VERSION ""

NS_ :

BS_:

BU_:

BO_ 2566605566 MG3IAPL: 8 Vector__XXX
 SG_ MtGt3IvtPwLtdDTUddRs : 0|2@1+ (1,0) [0|3] "" Vector__XXX
 SG_ MtGt3IvtPwLtdDTMPwMx : 10|2@1+ (1,0) [0|3] "" Vector__XXX
 SG_ MtGt3IvtPwLtdDTMPwM : 12|2@1+ (1,0) [0|3] "" Vector__XXX
 SG_ MtrGnrtr3InvrtrPwrLmtdDTTrqMxmm : 18|2@1+ (1,0) [0|3] "" Vector__XXX
 SG_ MtrGnrtr3InvrtrPwrLmtdDTTrqMnmm : 20|2@1+ (1,0) [0|3] "" Vector__XXX
 SG_ MtrGnrtr3InvrtrPwrLmtdDTSpdMxmm : 22|2@1+ (1,0) [0|3] "" Vector__XXX
 SG_ MtrGnrtr3InvrtrPwrLmtdDTSpdMnmm : 24|2@1+ (1,0) [0|3] "" Vector__XXX
 SG_ MtGt3IvtPwLtdDTIvtTpt : 28|2@1+ (1,0) [0|3] "" Vector__XXX
 SG_ MtGt3IvtPwLtdDTMtTpt : 30|2@1+ (1,0) [0|3] "" Vector__XXX
 SG_ MtGt3IvtPwLtdDTFtCdt : 32|2@1+ (1,0) [0|3] "" Vector__XXX
 SG_ MtGt3IvtPwLtdDTAtvTqRtLt : 34|2@1+ (1,0) [0|3] "" Vector__XXX
 SG_ MtGt3IvtPwLtdDTAtvSpdRtLt : 36|2@1+ (1,0) [0|3] "" Vector__XXX
 SG_ MtGt3IvtTqLtdDTMCtsts : 38|2@1+ (1,0) [0|3] "" Vector__XXX
 SG_ MtGt3IvtPwLtdDTDSdCtMx : 2|2@1+ (1,0) [0|3] "" Vector__XXX
 SG_ MtGt3IvtPwLtdDTDSdCtM : 4|2@1+ (1,0) [0|3] "" Vector__XXX
 SG_ MtGt3IvtPwLtdDTDSdVtMx : 6|2@1+ (1,0) [0|3] "" Vector__XXX
 SG_ MtGt3IvtPwLtdDTDSdVtM : 8|2@1+ (1,0) [0|3] "" Vector__XXX
 SG_ MtGt3IvtPwLtdDTDSdPwMx : 14|2@1+ (1,0) [0|3] "" Vector__XXX
 SG_ MtGt3IvtPwLtdDTDSdPwM : 16|2@1+ (1,0) [0|3] "" Vector__XXX

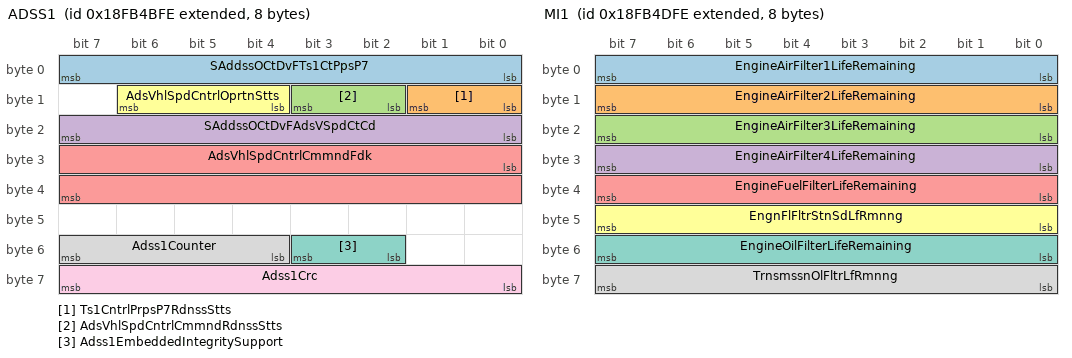
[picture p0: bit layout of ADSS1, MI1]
BO_ 2566605822 ADSS1: 8 Vector__XXX
 SG_ SAddssOCtDvFTs1CtPpsP7 : 0|8@1+ (1,0) [0|250] "sourceadr" Vector__XXX
 SG_ Ts1CntrlPrpsP7RdnssStts : 8|2@1+ (1,0) [0|3] "" Vector__XXX
 SG_ AdsVhlSpdCntrlCmmndRdnssStts : 10|2@1+ (1,0) [0|3] "" Vector__XXX
 SG_ SAddssOCtDvFAdsVSpdCtCd : 16|8@1+ (1,0) [0|250] "sourceadr" Vector__XXX
 SG_ AdsVhlSpdCntrlCmmndFdk : 24|16@1+ (0.00390625,0) [0|250.99609375] "km/h" Vector__XXX
 SG_ AdsVhlSpdCntrlOprtnStts : 12|3@1+ (1,0) [0|7] "" Vector__XXX
 SG_ Adss1EmbeddedIntegritySupport : 50|2@1+ (1,0) [0|3] "" Vector__XXX
 SG_ Adss1Counter : 52|4@1+ (1,0) [0|15] "" Vector__XXX
 SG_ Adss1Crc : 56|8@1+ (1,0) [0|250] "count" Vector__XXX

BO_ 2566606078 CCSI2: 8 Vector__XXX
 SG_ CabHeaterPower : 0|16@1+ (2,0) [0|128510] "W" Vector__XXX
 SG_ CabACCompressorPower : 16|16@1+ (0.5,0) [0|32127.5] "W" Vector__XXX

BO_ 2566606334 MI1: 8 Vector__XXX
 SG_ EngineAirFilter1LifeRemaining : 0|8@1+ (0.4,0) [0|100] "%" Vector__XXX
 SG_ EngineAirFilter2LifeRemaining : 8|8@1+ (0.4,0) [0|100] "%" Vector__XXX
 SG_ EngineAirFilter3LifeRemaining : 16|8@1+ (0.4,0) [0|100] "%" Vector__XXX
 SG_ EngineAirFilter4LifeRemaining : 24|8@1+ (0.4,0) [0|100] "%" Vector__XXX
 SG_ EngineFuelFilterLifeRemaining : 32|8@1+ (0.4,0) [0|100] "%" Vector__XXX
 SG_ EngnFlFltrStnSdLfRmnng : 40|8@1+ (0.4,0) [0|100] "%" Vector__XXX
 SG_ EngineOilFilterLifeRemaining : 48|8@1+ (0.4,0) [0|100] "%" Vector__XXX
 SG_ TrnsmssnOlFltrLfRmnng : 56|8@1+ (0.4,0) [0|100] "%" Vector__XXX

BO_ 2499497726 HCI1: 8 Vector__XXX
 SG_ HoistLeverPosition : 0|16@1+ (0.005,-150) [-100|100] "%" Vector__XXX
 SG_ HoistLeverDetentPositionStatus : 16|2@1+ (1,0) [0|3] "" Vector__XXX

BO_ 2633715710 HVESP6HIST: 19 Vector__XXX
 SG_ Hvesp6StateOfHealth : 0|8@1+ (0.4,0) [0|100] "%" Vector__XXX
 SG_ Hvesp6TotalEnergyThroughput : 24|32@1+ (100,0) [0|421108121500] "Watt-hour" Vector__XXX
 SG_ Hvesp6TotalAccumulatedCharge : 56|32@1+ (100,0) [0|421108121500] "Ah" Vector__XXX
 SG_ Hvesp6TotalLifetimeEnergyInput : 88|32@1+ (1,0) [0|4211081215] "kWh" Vector__XXX
 SG_ Hvesp6TotalLifetimeEnergyOutput : 120|32@1+ (1,0) [0|4211081215] "kWh" Vector__XXX
 SG_ Hvsp6CnttrOpnUndrLdCnt : 8|16@1+ (1,0) [0|64255] "count" Vector__XXX

BO_ 2566607102 HVESP6CFG: 19 Vector__XXX
 SG_ Hvesp6NominalVoltage : 0|16@1+ (0.05,0) [0|3212.75] "V" Vector__XXX
 SG_ Hvesp6CellMaximumVoltageLimit : 112|8@1+ (0.02044,0) [0|5.11] "V" Vector__XXX
 SG_ Hvesp6CellMinimumVoltageLimit : 120|8@1+ (0.02044,0) [0|5.11] "V" Vector__XXX
 SG_ Hvsp6RmmnddMnmmOprtngVltg : 16|16@1+ (0.05,0) [0|3212.75] "V" Vector__XXX
 SG_ Hvsp6RmmnddMxmmOprtngVltg : 32|16@1+ (0.05,0) [0|3212.75] "V" Vector__XXX
 SG_ Hvsp6RmmnddMnmmSttOfChrg : 48|16@1+ (0.0015625,0) [0|100.3984375] "%" Vector__XXX
 SG_ Hvsp6RmmnddMxmmSttOfChrg : 64|16@1+ (0.0015625,0) [0|100.3984375] "%" Vector__XXX
 SG_ Hvsp6RmmnddMxmmOprtngTmprtr : 80|16@1+ (0.03125,-273) [-273|1734.96875] "degC" Vector__XXX
 SG_ Hvsp6RmmnddMnmmOprtngTmprtr : 96|16@1+ (0.03125,-273) [-273|1734.96875] "degC" Vector__XXX
 SG_ Hvesp6NominalRatedCapacity : 128|24@1+ (0.001,0) [0|16449.535] "kWh" Vector__XXX

BO_ 2633716222 HVESP5HIST: 19 Vector__XXX
 SG_ Hvesp5StateOfHealth : 0|8@1+ (0.4,0) [0|100] "%" Vector__XXX
 SG_ Hvesp5TotalEnergyThroughput : 24|32@1+ (100,0) [0|421108121500] "Watt-hour" Vector__XXX
 SG_ Hvesp5TotalAccumulatedCharge : 56|32@1+ (100,0) [0|421108121500] "Ah" Vector__XXX
 SG_ Hvesp5TotalLifetimeEnergyInput : 88|32@1+ (1,0) [0|4211081215] "kWh" Vector__XXX
 SG_ Hvesp5TotalLifetimeEnergyOutput : 120|32@1+ (1,0) [0|4211081215] "kWh" Vector__XXX
 SG_ Hvsp5CnttrOpnUndrLdCnt : 8|16@1+ (1,0) [0|64255] "count" Vector__XXX

BO_ 2566607614 HVESP5CFG: 19 Vector__XXX
 SG_ Hvesp5NominalVoltage : 0|16@1+ (0.05,0) [0|3212.75] "V" Vector__XXX
 SG_ Hvesp5CellMaximumVoltageLimit : 112|8@1+ (0.02044,0) [0|5.11] "V" Vector__XXX
 SG_ Hvesp5CellMinimumVoltageLimit : 120|8@1+ (0.02044,0) [0|5.11] "V" Vector__XXX
 SG_ Hvsp5RmmnddMnmmOprtngVltg : 16|16@1+ (0.05,0) [0|3212.75] "V" Vector__XXX
 SG_ Hvsp5RmmnddMxmmOprtngVltg : 32|16@1+ (0.05,0) [0|3212.75] "V" Vector__XXX
 SG_ Hvsp5RmmnddMnmmSttOfChrg : 48|16@1+ (0.0015625,0) [0|100.3984375] "%" Vector__XXX
 SG_ Hvsp5RmmnddMxmmSttOfChrg : 64|16@1+ (0.0015625,0) [0|100.3984375] "%" Vector__XXX
 SG_ Hvsp5RmmnddMxmmOprtngTmprtr : 80|16@1+ (0.03125,-273) [-273|1734.96875] "degC" Vector__XXX
 SG_ Hvsp5RmmnddMnmmOprtngTmprtr : 96|16@1+ (0.03125,-273) [-273|1734.96875] "degC" Vector__XXX
 SG_ Hvesp5NominalRatedCapacity : 128|24@1+ (0.001,0) [0|16449.535] "kWh" Vector__XXX

BO_ 2633716734 HVESP4HIST: 19 Vector__XXX
 SG_ Hvesp4StateOfHealth : 0|8@1+ (0.4,0) [0|100] "%" Vector__XXX
 SG_ Hvesp4TotalEnergyThroughput : 24|32@1+ (100,0) [0|421108121500] "Watt-hour" Vector__XXX
 SG_ Hvesp4TotalAccumulatedCharge : 56|32@1+ (100,0) [0|421108121500] "Ah" Vector__XXX
 SG_ Hvesp4TotalLifetimeEnergyInput : 88|32@1+ (1,0) [0|4211081215] "kWh" Vector__XXX
 SG_ Hvesp4TotalLifetimeEnergyOutput : 120|32@1+ (1,0) [0|4211081215] "kWh" Vector__XXX
 SG_ Hvsp4CnttrOpnUndrLdCnt : 8|16@1+ (1,0) [0|64255] "count" Vector__XXX

BO_ 2566608126 HVESP4CFG: 19 Vector__XXX
 SG_ Hvesp4NominalVoltage : 0|16@1+ (0.05,0) [0|3212.75] "V" Vector__XXX
 SG_ Hvesp4CellMaximumVoltageLimit : 112|8@1+ (0.02044,0) [0|5.11] "V" Vector__XXX
 SG_ Hvesp4CellMinimumVoltageLimit : 120|8@1+ (0.02044,0) [0|5.11] "V" Vector__XXX
 SG_ Hvsp4RmmnddMnmmOprtngVltg : 16|16@1+ (0.05,0) [0|3212.75] "V" Vector__XXX
 SG_ Hvsp4RmmnddMxmmOprtngVltg : 32|16@1+ (0.05,0) [0|3212.75] "V" Vector__XXX
 SG_ Hvsp4RmmnddMnmmSttOfChrg : 48|16@1+ (0.0015625,0) [0|100.3984375] "%" Vector__XXX
 SG_ Hvsp4RmmnddMxmmSttOfChrg : 64|16@1+ (0.0015625,0) [0|100.3984375] "%" Vector__XXX
 SG_ Hvsp4RmmnddMxmmOprtngTmprtr : 80|16@1+ (0.03125,-273) [-273|1734.96875] "degC" Vector__XXX
 SG_ Hvsp4RmmnddMnmmOprtngTmprtr : 96|16@1+ (0.03125,-273) [-273|1734.96875] "degC" Vector__XXX
 SG_ Hvesp4NominalRatedCapacity : 128|24@1+ (0.001,0) [0|16449.535] "kWh" Vector__XXX

BO_ 2633717246 HVESP3HIST: 19 Vector__XXX
 SG_ Hvesp3StateOfHealth : 0|8@1+ (0.4,0) [0|100] "%" Vector__XXX
 SG_ Hvesp3TotalEnergyThroughput : 24|32@1+ (100,0) [0|421108121500] "Watt-hour" Vector__XXX
 SG_ Hvesp3TotalAccumulatedCharge : 56|32@1+ (100,0) [0|421108121500] "Ah" Vector__XXX
 SG_ Hvesp3TotalLifetimeEnergyInput : 88|32@1+ (1,0) [0|4211081215] "kWh" Vector__XXX
 SG_ Hvesp3TotalLifetimeEnergyOutput : 120|32@1+ (1,0) [0|4211081215] "kWh" Vector__XXX
 SG_ Hvsp3CnttrOpnUndrLdCnt : 8|16@1+ (1,0) [0|64255] "count" Vector__XXX

BO_ 2566608638 HVESP3CFG: 19 Vector__XXX
 SG_ Hvesp3NominalVoltage : 0|16@1+ (0.05,0) [0|3212.75] "V" Vector__XXX
 SG_ Hvesp3CellMaximumVoltageLimit : 112|8@1+ (0.02044,0) [0|5.11] "V" Vector__XXX
 SG_ Hvesp3CellMinimumVoltageLimit : 120|8@1+ (0.02044,0) [0|5.11] "V" Vector__XXX
 SG_ Hvsp3RmmnddMnmmOprtngVltg : 16|16@1+ (0.05,0) [0|3212.75] "V" Vector__XXX
 SG_ Hvsp3RmmnddMxmmOprtngVltg : 32|16@1+ (0.05,0) [0|3212.75] "V" Vector__XXX
 SG_ Hvsp3RmmnddMnmmSttOfChrg : 48|16@1+ (0.0015625,0) [0|100.3984375] "%" Vector__XXX
 SG_ Hvsp3RmmnddMxmmSttOfChrg : 64|16@1+ (0.0015625,0) [0|100.3984375] "%" Vector__XXX
 SG_ Hvsp3RmmnddMxmmOprtngTmprtr : 80|16@1+ (0.03125,-273) [-273|1734.96875] "degC" Vector__XXX
 SG_ Hvsp3RmmnddMnmmOprtngTmprtr : 96|16@1+ (0.03125,-273) [-273|1734.96875] "degC" Vector__XXX
 SG_ Hvesp3NominalRatedCapacity : 128|24@1+ (0.001,0) [0|16449.535] "kWh" Vector__XXX

BO_ 2633717758 HVESP2HIST: 19 Vector__XXX
 SG_ Hvesp2StateOfHealth : 0|8@1+ (0.4,0) [0|100] "%" Vector__XXX
 SG_ Hvesp2TotalEnergyThroughput : 24|32@1+ (100,0) [0|421108121500] "Watt-hour" Vector__XXX
 SG_ Hvesp2TotalAccumulatedCharge : 56|32@1+ (100,0) [0|421108121500] "Ah" Vector__XXX
 SG_ Hvesp2TotalLifetimeEnergyInput : 88|32@1+ (1,0) [0|4211081215] "kWh" Vector__XXX
 SG_ Hvesp2TotalLifetimeEnergyOutput : 120|32@1+ (1,0) [0|4211081215] "kWh" Vector__XXX
 SG_ Hvsp2CnttrOpnUndrLdCnt : 8|16@1+ (1,0) [0|64255] "count" Vector__XXX

BO_ 2566609150 HVESP2CFG: 19 Vector__XXX
 SG_ Hvesp2NominalVoltage : 0|16@1+ (0.05,0) [0|3212.75] "V" Vector__XXX
 SG_ Hvesp2CellMaximumVoltageLimit : 112|8@1+ (0.02044,0) [0|5.11] "V" Vector__XXX
 SG_ Hvesp2CellMinimumVoltageLimit : 120|8@1+ (0.02044,0) [0|5.11] "V" Vector__XXX
 SG_ Hvsp2RmmnddMnmmOprtngVltg : 16|16@1+ (0.05,0) [0|3212.75] "V" Vector__XXX
 SG_ Hvsp2RmmnddMxmmOprtngVltg : 32|16@1+ (0.05,0) [0|3212.75] "V" Vector__XXX
 SG_ Hvsp2RmmnddMnmmSttOfChrg : 48|16@1+ (0.0015625,0) [0|100.3984375] "%" Vector__XXX
 SG_ Hvsp2RmmnddMxmmSttOfChrg : 64|16@1+ (0.0015625,0) [0|100.3984375] "%" Vector__XXX
 SG_ Hvsp2RmmnddMxmmOprtngTmprtr : 80|16@1+ (0.03125,-273) [-273|1734.96875] "degC" Vector__XXX
 SG_ Hvsp2RmmnddMnmmOprtngTmprtr : 96|16@1+ (0.03125,-273) [-273|1734.96875] "degC" Vector__XXX
 SG_ Hvesp2NominalRatedCapacity : 128|24@1+ (0.001,0) [0|16449.535] "kWh" Vector__XXX

BO_ 2633718270 HVESP1HIST: 19 Vector__XXX
 SG_ Hvesp1StateOfHealth : 0|8@1+ (0.4,0) [0|100] "%" Vector__XXX
 SG_ Hvesp1TotalEnergyThroughput : 24|32@1+ (100,0) [0|421108121500] "Watt-hour" Vector__XXX
 SG_ Hvesp1TotalAccumulatedCharge : 56|32@1+ (100,0) [0|421108121500] "Ah" Vector__XXX
 SG_ Hvesp1TotalLifetimeEnergyInput : 88|32@1+ (1,0) [0|4211081215] "kWh" Vector__XXX
 SG_ Hvesp1TotalLifetimeEnergyOutput : 120|32@1+ (1,0) [0|4211081215] "kWh" Vector__XXX
 SG_ Hvsp1CnttrOpnUndrLdCnt : 8|16@1+ (1,0) [0|64255] "count" Vector__XXX

BO_ 2566609662 HVESP1CFG: 19 Vector__XXX
 SG_ Hvesp1NominalVoltage : 0|16@1+ (0.05,0) [0|3212.75] "V" Vector__XXX
 SG_ Hvesp1CellMaximumVoltageLimit : 112|8@1+ (0.02044,0) [0|5.11] "V" Vector__XXX
 SG_ Hvesp1CellMinimumVoltageLimit : 120|8@1+ (0.02044,0) [0|5.11] "V" Vector__XXX
 SG_ Hvsp1RmmnddMnmmOprtngVltg : 16|16@1+ (0.05,0) [0|3212.75] "V" Vector__XXX
 SG_ Hvsp1RmmnddMxmmOprtngVltg : 32|16@1+ (0.05,0) [0|3212.75] "V" Vector__XXX
 SG_ Hvsp1RmmnddMnmmSttOfChrg : 48|16@1+ (0.0015625,0) [0|100.3984375] "%" Vector__XXX
 SG_ Hvsp1RmmnddMxmmSttOfChrg : 64|16@1+ (0.0015625,0) [0|100.3984375] "%" Vector__XXX
 SG_ Hvsp1RmmnddMxmmOprtngTmprtr : 80|16@1+ (0.03125,-273) [-273|1734.96875] "degC" Vector__XXX
 SG_ Hvsp1RmmnddMnmmOprtngTmprtr : 96|16@1+ (0.03125,-273) [-273|1734.96875] "degC" Vector__XXX
 SG_ Hvesp1NominalRatedCapacity : 128|24@1+ (0.001,0) [0|16449.535] "kWh" Vector__XXX

BO_ 2633718782 VFSSM1DET: 24 Vector__XXX
 SG_ VfssMdl1Dttr1DttrTp : 0|4@1+ (1,0) [0|15] "" Vector__XXX
 SG_ VfssMdl1Dttr2DttrTp : 24|4@1+ (1,0) [0|15] "" Vector__XXX
 SG_ VfssMdl1Dttr3DttrTp : 48|4@1+ (1,0) [0|15] "" Vector__XXX
 SG_ VfssMdl1Dttr4DttrTp : 72|4@1+ (1,0) [0|15] "" Vector__XXX
 SG_ VfssMdl1Dttr5DttrTp : 96|4@1+ (1,0) [0|15] "" Vector__XXX
 SG_ VfssMdl1Dttr6DttrTp : 120|4@1+ (1,0) [0|15] "" Vector__XXX
 SG_ VfssMdl1Dttr7DttrTp : 144|4@1+ (1,0) [0|15] "" Vector__XXX
 SG_ VfssMdl1Dttr8DttrTp : 168|4@1+ (1,0) [0|15] "" Vector__XXX
 SG_ VfssMdl1Dttr1DttrDtSlt : 4|4@1+ (1,0) [0|15] "" Vector__XXX
 SG_ VfssMdl1Dttr2DttrDtSlt : 28|4@1+ (1,0) [0|15] "" Vector__XXX
 SG_ VfssMdl1Dttr3DttrDtSlt : 52|4@1+ (1,0) [0|15] "" Vector__XXX
 SG_ VfssMdl1Dttr4DttrDtSlt : 76|4@1+ (1,0) [0|15] "" Vector__XXX
 SG_ VfssMdl1Dttr5DttrDtSlt : 100|4@1+ (1,0) [0|15] "" Vector__XXX
 SG_ VfssMdl1Dttr6DttrDtSlt : 124|4@1+ (1,0) [0|15] "" Vector__XXX
 SG_ VfssMdl1Dttr7DttrDtSlt : 148|4@1+ (1,0) [0|15] "" Vector__XXX
 SG_ VfssMdl1Dttr8DttrDtSlt : 172|4@1+ (1,0) [0|15] "" Vector__XXX

BO_ 2633719038 VFSSM2DET: 24 Vector__XXX
 SG_ VfssMdl2Dttr1DttrTp : 0|4@1+ (1,0) [0|15] "" Vector__XXX
 SG_ VfssMdl2Dttr2DttrTp : 24|4@1+ (1,0) [0|15] "" Vector__XXX
 SG_ VfssMdl2Dttr3DttrTp : 48|4@1+ (1,0) [0|15] "" Vector__XXX
 SG_ VfssMdl2Dttr4DttrTp : 72|4@1+ (1,0) [0|15] "" Vector__XXX
 SG_ VfssMdl2Dttr5DttrTp : 96|4@1+ (1,0) [0|15] "" Vector__XXX
 SG_ VfssMdl2Dttr6DttrTp : 120|4@1+ (1,0) [0|15] "" Vector__XXX
 SG_ VfssMdl2Dttr7DttrTp : 144|4@1+ (1,0) [0|15] "" Vector__XXX
 SG_ VfssMdl2Dttr8DttrTp : 168|4@1+ (1,0) [0|15] "" Vector__XXX
 SG_ VfssMdl2Dttr1DttrDtSlt : 4|4@1+ (1,0) [0|15] "" Vector__XXX
 SG_ VfssMdl2Dttr2DttrDtSlt : 28|4@1+ (1,0) [0|15] "" Vector__XXX
 SG_ VfssMdl2Dttr3DttrDtSlt : 52|4@1+ (1,0) [0|15] "" Vector__XXX
 SG_ VfssMdl2Dttr4DttrDtSlt : 76|4@1+ (1,0) [0|15] "" Vector__XXX
 SG_ VfssMdl2Dttr5DttrDtSlt : 100|4@1+ (1,0) [0|15] "" Vector__XXX
 SG_ VfssMdl2Dttr6DttrDtSlt : 124|4@1+ (1,0) [0|15] "" Vector__XXX
 SG_ VfssMdl2Dttr7DttrDtSlt : 148|4@1+ (1,0) [0|15] "" Vector__XXX
 SG_ VfssMdl2Dttr8DttrDtSlt : 172|4@1+ (1,0) [0|15] "" Vector__XXX

BO_ 2633719294 VFSSM3DET: 24 Vector__XXX
 SG_ VfssMdl3Dttr1DttrTp : 0|4@1+ (1,0) [0|15] "" Vector__XXX
 SG_ VfssMdl3Dttr2DttrTp : 24|4@1+ (1,0) [0|15] "" Vector__XXX
 SG_ VfssMdl3Dttr3DttrTp : 48|4@1+ (1,0) [0|15] "" Vector__XXX
 SG_ VfssMdl3Dttr4DttrTp : 72|4@1+ (1,0) [0|15] "" Vector__XXX
 SG_ VfssMdl3Dttr5DttrTp : 96|4@1+ (1,0) [0|15] "" Vector__XXX
 SG_ VfssMdl3Dttr6DttrTp : 120|4@1+ (1,0) [0|15] "" Vector__XXX
 SG_ VfssMdl3Dttr7DttrTp : 144|4@1+ (1,0) [0|15] "" Vector__XXX
 SG_ VfssMdl3Dttr8DttrTp : 168|4@1+ (1,0) [0|15] "" Vector__XXX
 SG_ VfssMdl3Dttr1DttrDtSlt : 4|4@1+ (1,0) [0|15] "" Vector__XXX
 SG_ VfssMdl3Dttr2DttrDtSlt : 28|4@1+ (1,0) [0|15] "" Vector__XXX
 SG_ VfssMdl3Dttr3DttrDtSlt : 52|4@1+ (1,0) [0|15] "" Vector__XXX
 SG_ VfssMdl3Dttr4DttrDtSlt : 76|4@1+ (1,0) [0|15] "" Vector__XXX
 SG_ VfssMdl3Dttr5DttrDtSlt : 100|4@1+ (1,0) [0|15] "" Vector__XXX
 SG_ VfssMdl3Dttr6DttrDtSlt : 124|4@1+ (1,0) [0|15] "" Vector__XXX
 SG_ VfssMdl3Dttr7DttrDtSlt : 148|4@1+ (1,0) [0|15] "" Vector__XXX
 SG_ VfssMdl3Dttr8DttrDtSlt : 172|4@1+ (1,0) [0|15] "" Vector__XXX

BO_ 2633719550 VFSSM4DET: 24 Vector__XXX
 SG_ VfssMdl4Dttr1DttrTp : 0|4@1+ (1,0) [0|15] "" Vector__XXX
 SG_ VfssMdl4Dttr2DttrTp : 24|4@1+ (1,0) [0|15] "" Vector__XXX
 SG_ VfssMdl4Dttr3DttrTp : 48|4@1+ (1,0) [0|15] "" Vector__XXX
 SG_ VfssMdl4Dttr4DttrTp : 72|4@1+ (1,0) [0|15] "" Vector__XXX
 SG_ VfssMdl4Dttr5DttrTp : 96|4@1+ (1,0) [0|15] "" Vector__XXX
 SG_ VfssMdl4Dttr6DttrTp : 120|4@1+ (1,0) [0|15] "" Vector__XXX
 SG_ VfssMdl4Dttr7DttrTp : 144|4@1+ (1,0) [0|15] "" Vector__XXX
 SG_ VfssMdl4Dttr8DttrTp : 168|4@1+ (1,0) [0|15] "" Vector__XXX
 SG_ VfssMdl4Dttr1DttrDtSlt : 4|4@1+ (1,0) [0|15] "" Vector__XXX
 SG_ VfssMdl4Dttr2DttrDtSlt : 28|4@1+ (1,0) [0|15] "" Vector__XXX
 SG_ VfssMdl4Dttr3DttrDtSlt : 52|4@1+ (1,0) [0|15] "" Vector__XXX
 SG_ VfssMdl4Dttr4DttrDtSlt : 76|4@1+ (1,0) [0|15] "" Vector__XXX
 SG_ VfssMdl4Dttr5DttrDtSlt : 100|4@1+ (1,0) [0|15] "" Vector__XXX
 SG_ VfssMdl4Dttr6DttrDtSlt : 124|4@1+ (1,0) [0|15] "" Vector__XXX
 SG_ VfssMdl4Dttr7DttrDtSlt : 148|4@1+ (1,0) [0|15] "" Vector__XXX
 SG_ VfssMdl4Dttr8DttrDtSlt : 172|4@1+ (1,0) [0|15] "" Vector__XXX

BO_ 2633719806 VFSSM1AUX: 16 Vector__XXX
 SG_ VfssModule1HeatZone1Data : 0|16@1+ (0.01,0) [0|642.55] "V" Vector__XXX
 SG_ VfssModule1HeatZone2Data : 16|16@1+ (0.01,0) [0|642.55] "V" Vector__XXX
 SG_ VfssModule1ReleaseZone1Data : 32|16@1+ (0.01,0) [0|642.55] "V" Vector__XXX
 SG_ VfssModule1ReleaseZone2Data : 48|16@1+ (0.01,0) [0|642.55] "V" Vector__XXX
 SG_ VfssModule1PressureSwitch1Data : 64|16@1+ (0.01,0) [0|642.55] "V" Vector__XXX
 SG_ VfssModule1PressureSwitch2Data : 80|16@1+ (0.01,0) [0|642.55] "V" Vector__XXX
 SG_ VfssModule1PrimaryPowerVoltage : 96|16@1+ (0.01,0) [0|642.55] "V" Vector__XXX
 SG_ VfssMdl1SndrPwrVltg : 112|16@1+ (0.01,0) [0|642.55] "V" Vector__XXX

BO_ 2633720062 VFSSM2AUX: 16 Vector__XXX
 SG_ VfssModule2HeatZone1Data : 0|16@1+ (0.01,0) [0|642.55] "V" Vector__XXX
 SG_ VfssModule2HeatZone2Data : 16|16@1+ (0.01,0) [0|642.55] "V" Vector__XXX
 SG_ VfssModule2ReleaseZone1Data : 32|16@1+ (0.01,0) [0|642.55] "V" Vector__XXX
 SG_ VfssModule2ReleaseZone2Data : 48|16@1+ (0.01,0) [0|642.55] "V" Vector__XXX
 SG_ VfssModule2PressureSwitch1Data : 64|16@1+ (0.01,0) [0|642.55] "V" Vector__XXX
 SG_ VfssModule2PressureSwitch2Data : 80|16@1+ (0.01,0) [0|642.55] "V" Vector__XXX
 SG_ VfssModule2PrimaryPowerVoltage : 96|16@1+ (0.01,0) [0|642.55] "V" Vector__XXX
 SG_ VfssMdl2SndrPwrVltg : 112|16@1+ (0.01,0) [0|642.55] "V" Vector__XXX

BO_ 2633720318 VFSSM3AUX: 16 Vector__XXX
 SG_ VfssModule3HeatZone1Data : 0|16@1+ (0.01,0) [0|642.55] "V" Vector__XXX
 SG_ VfssModule3HeatZone2Data : 16|16@1+ (0.01,0) [0|642.55] "V" Vector__XXX
 SG_ VfssModule3ReleaseZone1Data : 32|16@1+ (0.01,0) [0|642.55] "V" Vector__XXX
 SG_ VfssModule3ReleaseZone2Data : 48|16@1+ (0.01,0) [0|642.55] "V" Vector__XXX
 SG_ VfssModule3PressureSwitch1Data : 64|16@1+ (0.01,0) [0|642.55] "V" Vector__XXX
 SG_ VfssModule3PressureSwitch2Data : 80|16@1+ (0.01,0) [0|642.55] "V" Vector__XXX
 SG_ VfssModule3PrimaryPowerVoltage : 96|16@1+ (0.01,0) [0|642.55] "V" Vector__XXX
 SG_ VfssMdl3SndrPwrVltg : 112|16@1+ (0.01,0) [0|642.55] "V" Vector__XXX

BO_ 2633720574 VFSSM4AUX: 16 Vector__XXX
 SG_ VfssModule4HeatZone1Data : 0|16@1+ (0.01,0) [0|642.55] "V" Vector__XXX
 SG_ VfssModule4HeatZone2Data : 16|16@1+ (0.01,0) [0|642.55] "V" Vector__XXX
 SG_ VfssModule4ReleaseZone1Data : 32|16@1+ (0.01,0) [0|642.55] "V" Vector__XXX
 SG_ VfssModule4ReleaseZone2Data : 48|16@1+ (0.01,0) [0|642.55] "V" Vector__XXX
 SG_ VfssModule4PressureSwitch1Data : 64|16@1+ (0.01,0) [0|642.55] "V" Vector__XXX
 SG_ VfssModule4PressureSwitch2Data : 80|16@1+ (0.01,0) [0|642.55] "V" Vector__XXX
 SG_ VfssModule4PrimaryPowerVoltage : 96|16@1+ (0.01,0) [0|642.55] "V" Vector__XXX
 SG_ VfssMdl4SndrPwrVltg : 112|16@1+ (0.01,0) [0|642.55] "V" Vector__XXX

BO_ 2633720830 VFSSM1NAMES: 104 Vector__XXX
 SG_ VfssModule1Name : 0|64@1+ (1,0) [0|255] "" Vector__XXX
 SG_ VfssModule1DetectorZone1Name : 64|64@1+ (1,0) [0|255] "" Vector__XXX
 SG_ VfssModule1DetectorZone2Name : 128|64@1+ (1,0) [0|255] "" Vector__XXX
 SG_ VfssModule1DetectorZone3Name : 192|64@1+ (1,0) [0|255] "" Vector__XXX
 SG_ VfssModule1DetectorZone4Name : 256|64@1+ (1,0) [0|255] "" Vector__XXX
 SG_ VfssModule1DetectorZone5Name : 320|64@1+ (1,0) [0|255] "" Vector__XXX
 SG_ VfssModule1DetectorZone6Name : 384|64@1+ (1,0) [0|255] "" Vector__XXX
 SG_ VfssModule1DetectorZone7Name : 448|64@1+ (1,0) [0|255] "" Vector__XXX
 SG_ VfssModule1DetectorZone8Name : 512|64@1+ (1,0) [0|255] "" Vector__XXX
 SG_ VfssModule1HeatZone1Name : 576|64@1+ (1,0) [0|255] "" Vector__XXX
 SG_ VfssModule1HeatZone2Name : 640|64@1+ (1,0) [0|255] "" Vector__XXX
 SG_ VfssModule1ReleaseZone1Name : 704|64@1+ (1,0) [0|255] "" Vector__XXX
 SG_ VfssModule1ReleaseZone2Name : 768|64@1+ (1,0) [0|255] "" Vector__XXX

BO_ 2633721086 VFSSM2NAMES: 104 Vector__XXX
 SG_ VfssModule2Name : 0|64@1+ (1,0) [0|255] "" Vector__XXX
 SG_ VfssModule2DetectorZone1Name : 64|64@1+ (1,0) [0|255] "" Vector__XXX
 SG_ VfssModule2DetectorZone2Name : 128|64@1+ (1,0) [0|255] "" Vector__XXX
 SG_ VfssModule2DetectorZone3Name : 192|64@1+ (1,0) [0|255] "" Vector__XXX
 SG_ VfssModule2DetectorZone4Name : 256|64@1+ (1,0) [0|255] "" Vector__XXX
 SG_ VfssModule2DetectorZone5Name : 320|64@1+ (1,0) [0|255] "" Vector__XXX
 SG_ VfssModule2DetectorZone6Name : 384|64@1+ (1,0) [0|255] "" Vector__XXX
 SG_ VfssModule2DetectorZone7Name : 448|64@1+ (1,0) [0|255] "" Vector__XXX
 SG_ VfssModule2DetectorZone8Name : 512|64@1+ (1,0) [0|255] "" Vector__XXX
 SG_ VfssModule2HeatZone1Name : 576|64@1+ (1,0) [0|255] "" Vector__XXX
 SG_ VfssModule2HeatZone2Name : 640|64@1+ (1,0) [0|255] "" Vector__XXX
 SG_ VfssModule2ReleaseZone1Name : 704|64@1+ (1,0) [0|255] "" Vector__XXX
 SG_ VfssModule2ReleaseZone2Name : 768|64@1+ (1,0) [0|255] "" Vector__XXX

BO_ 2633721342 VFSSM3NAMES: 104 Vector__XXX
 SG_ VfssModule3Name : 0|64@1+ (1,0) [0|255] "" Vector__XXX
 SG_ VfssModule3DetectorZone1Name : 64|64@1+ (1,0) [0|255] "" Vector__XXX
 SG_ VfssModule3DetectorZone2Name : 128|64@1+ (1,0) [0|255] "" Vector__XXX
 SG_ VfssModule3DetectorZone3Name : 192|64@1+ (1,0) [0|255] "" Vector__XXX
 SG_ VfssModule3DetectorZone4Name : 256|64@1+ (1,0) [0|255] "" Vector__XXX
 SG_ VfssModule3DetectorZone5Name : 320|64@1+ (1,0) [0|255] "" Vector__XXX
 SG_ VfssModule3DetectorZone6Name : 384|64@1+ (1,0) [0|255] "" Vector__XXX
 SG_ VfssModule3DetectorZone7Name : 448|64@1+ (1,0) [0|255] "" Vector__XXX
 SG_ VfssModule3DetectorZone8Name : 512|64@1+ (1,0) [0|255] "" Vector__XXX
 SG_ VfssModule3HeatZone1Name : 576|64@1+ (1,0) [0|255] "" Vector__XXX
 SG_ VfssModule3HeatZone2Name : 640|64@1+ (1,0) [0|255] "" Vector__XXX
 SG_ VfssModule3ReleaseZone1Name : 704|64@1+ (1,0) [0|255] "" Vector__XXX
 SG_ VfssModule3ReleaseZone2Name : 768|64@1+ (1,0) [0|255] "" Vector__XXX

BO_ 2633721598 VFSSM4NAMES: 104 Vector__XXX
 SG_ VfssModule4Name : 0|64@1+ (1,0) [0|255] "" Vector__XXX
 SG_ VfssModule4DetectorZone1Name : 64|64@1+ (1,0) [0|255] "" Vector__XXX
 SG_ VfssModule4DetectorZone2Name : 128|64@1+ (1,0) [0|255] "" Vector__XXX
 SG_ VfssModule4DetectorZone3Name : 192|64@1+ (1,0) [0|255] "" Vector__XXX
 SG_ VfssModule4DetectorZone4Name : 256|64@1+ (1,0) [0|255] "" Vector__XXX
 SG_ VfssModule4DetectorZone5Name : 320|64@1+ (1,0) [0|255] "" Vector__XXX
 SG_ VfssModule4DetectorZone6Name : 384|64@1+ (1,0) [0|255] "" Vector__XXX
 SG_ VfssModule4DetectorZone7Name : 448|64@1+ (1,0) [0|255] "" Vector__XXX
 SG_ VfssModule4DetectorZone8Name : 512|64@1+ (1,0) [0|255] "" Vector__XXX
 SG_ VfssModule4HeatZone1Name : 576|64@1+ (1,0) [0|255] "" Vector__XXX
 SG_ VfssModule4HeatZone2Name : 640|64@1+ (1,0) [0|255] "" Vector__XXX
 SG_ VfssModule4ReleaseZone1Name : 704|64@1+ (1,0) [0|255] "" Vector__XXX
 SG_ VfssModule4ReleaseZone2Name : 768|64@1+ (1,0) [0|255] "" Vector__XXX

BO_ 2566612990 MG2IAPL: 8 Vector__XXX
 SG_ MtGt2IvtPwLtdDTUddRs : 0|2@1+ (1,0) [0|3] "" Vector__XXX
 SG_ MtGt2IvtPwLtdDTMPwMx : 10|2@1+ (1,0) [0|3] "" Vector__XXX
 SG_ MtGt2IvtPwLtdDTMPwM : 12|2@1+ (1,0) [0|3] "" Vector__XXX
 SG_ MtrGnrtr2InvrtrPwrLmtdDTTrqMxmm : 18|2@1+ (1,0) [0|3] "" Vector__XXX
 SG_ MtrGnrtr2InvrtrPwrLmtdDTTrqMnmm : 20|2@1+ (1,0) [0|3] "" Vector__XXX
 SG_ MtrGnrtr2InvrtrPwrLmtdDTSpdMxmm : 22|2@1+ (1,0) [0|3] "" Vector__XXX
 SG_ MtrGnrtr2InvrtrPwrLmtdDTSpdMnmm : 24|2@1+ (1,0) [0|3] "" Vector__XXX
 SG_ MtGt2IvtPwLtdDTIvtTpt : 28|2@1+ (1,0) [0|3] "" Vector__XXX
 SG_ MtGt2IvtPwLtdDTMtTpt : 30|2@1+ (1,0) [0|3] "" Vector__XXX
 SG_ MtGt2IvtPwLtdDTFtCdt : 32|2@1+ (1,0) [0|3] "" Vector__XXX
 SG_ MtGt2IvtPwLtdDTAtvTqRtLt : 34|2@1+ (1,0) [0|3] "" Vector__XXX
 SG_ MtGt2IvtPwLtdDTAtvSpdRtLt : 36|2@1+ (1,0) [0|3] "" Vector__XXX
 SG_ MtGt2IvtTqLtdDTMCtsts : 38|2@1+ (1,0) [0|3] "" Vector__XXX
 SG_ MtGt2IvtPwLtdDTDSdCtMx : 2|2@1+ (1,0) [0|3] "" Vector__XXX
 SG_ MtGt2IvtPwLtdDTDSdCtM : 4|2@1+ (1,0) [0|3] "" Vector__XXX
 SG_ MtGt2IvtPwLtdDTDSdVtMx : 6|2@1+ (1,0) [0|3] "" Vector__XXX
 SG_ MtGt2IvtPwLtdDTDSdVtM : 8|2@1+ (1,0) [0|3] "" Vector__XXX
 SG_ MtGt2IvtPwLtdDTDSdPwMx : 14|2@1+ (1,0) [0|3] "" Vector__XXX
 SG_ MtGt2IvtPwLtdDTDSdPwM : 16|2@1+ (1,0) [0|3] "" Vector__XXX

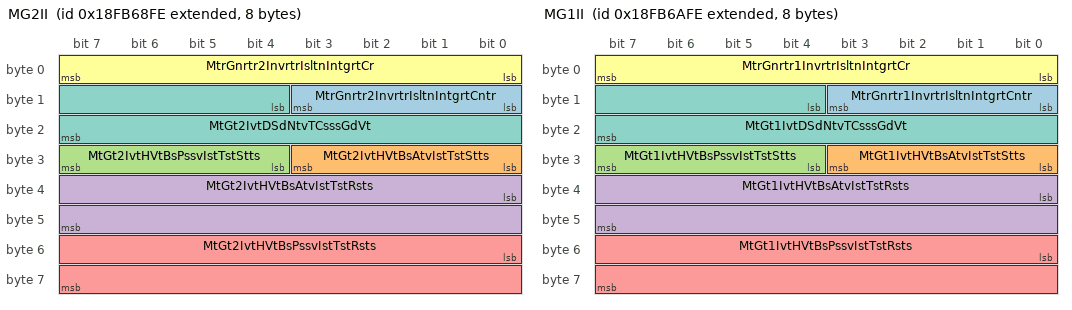
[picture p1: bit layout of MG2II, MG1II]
BO_ 2566613246 MG2II: 8 Vector__XXX
 SG_ MtrGnrtr2InvrtrIsltnIntgrtCntr : 8|4@1+ (1,0) [0|15] "" Vector__XXX
 SG_ MtGt2IvtHVtBsAtvIstTstStts : 24|4@1+ (1,0) [0|15] "" Vector__XXX
 SG_ MtGt2IvtHVtBsPssvIstTstStts : 28|4@1+ (1,0) [0|15] "" Vector__XXX
 SG_ MtGt2IvtHVtBsAtvIstTstRsts : 32|16@1+ (0.1,0) [0|6425.5] "OhmPerV" Vector__XXX
 SG_ MtGt2IvtHVtBsPssvIstTstRsts : 48|16@1+ (0.1,0) [0|6425.5] "OhmPerV" Vector__XXX
 SG_ MtrGnrtr2InvrtrIsltnIntgrtCr : 0|8@1+ (1,0) [0|250] "count" Vector__XXX
 SG_ MtGt2IvtDSdNtvTCsssGdVt : 12|12@1+ (0.0625,-125) [-125|125.9375] "%" Vector__XXX

BO_ 2566613502 MG1IAPL: 8 Vector__XXX
 SG_ MtGt1IvtPwLtdDTUddRs : 0|2@1+ (1,0) [0|3] "" Vector__XXX
 SG_ MtGt1IvtPwLtdDTMPwMx : 10|2@1+ (1,0) [0|3] "" Vector__XXX
 SG_ MtGt1IvtPwLtdDTMPwM : 12|2@1+ (1,0) [0|3] "" Vector__XXX
 SG_ MtrGnrtr1InvrtrPwrLmtdDTTrqMxmm : 18|2@1+ (1,0) [0|3] "" Vector__XXX
 SG_ MtrGnrtr1InvrtrPwrLmtdDTTrqMnmm : 20|2@1+ (1,0) [0|3] "" Vector__XXX
 SG_ MtrGnrtr1InvrtrPwrLmtdDTSpdMxmm : 22|2@1+ (1,0) [0|3] "" Vector__XXX
 SG_ MtrGnrtr1InvrtrPwrLmtdDTSpdMnmm : 24|2@1+ (1,0) [0|3] "" Vector__XXX
 SG_ MtGt1IvtPwLtdDTIvtTpt : 28|2@1+ (1,0) [0|3] "" Vector__XXX
 SG_ MtGt1IvtPwLtdDTMtTpt : 30|2@1+ (1,0) [0|3] "" Vector__XXX
 SG_ MtGt1IvtPwLtdDTFtCdt : 32|2@1+ (1,0) [0|3] "" Vector__XXX
 SG_ MtGt1IvtPwLtdDTAtvTqRtLt : 34|2@1+ (1,0) [0|3] "" Vector__XXX
 SG_ MtGt1IvtPwLtdDTAtvSpdRtLt : 36|2@1+ (1,0) [0|3] "" Vector__XXX
 SG_ MtGt1IvtTqLtdDTMCtsts : 38|2@1+ (1,0) [0|3] "" Vector__XXX
 SG_ MtGt1IvtPwLtdDTDSdCtMx : 2|2@1+ (1,0) [0|3] "" Vector__XXX
 SG_ MtGt1IvtPwLtdDTDSdCtM : 4|2@1+ (1,0) [0|3] "" Vector__XXX
 SG_ MtGt1IvtPwLtdDTDSdVtMx : 6|2@1+ (1,0) [0|3] "" Vector__XXX
 SG_ MtGt1IvtPwLtdDTDSdVtM : 8|2@1+ (1,0) [0|3] "" Vector__XXX
 SG_ MtGt1IvtPwLtdDTDSdPwMx : 14|2@1+ (1,0) [0|3] "" Vector__XXX
 SG_ MtGt1IvtPwLtdDTDSdPwM : 16|2@1+ (1,0) [0|3] "" Vector__XXX

BO_ 2566613758 MG1II: 8 Vector__XXX
 SG_ MtrGnrtr1InvrtrIsltnIntgrtCntr : 8|4@1+ (1,0) [0|15] "" Vector__XXX
 SG_ MtGt1IvtHVtBsAtvIstTstStts : 24|4@1+ (1,0) [0|15] "" Vector__XXX
 SG_ MtGt1IvtHVtBsPssvIstTstStts : 28|4@1+ (1,0) [0|15] "" Vector__XXX
 SG_ MtGt1IvtHVtBsAtvIstTstRsts : 32|16@1+ (0.1,0) [0|6425.5] "OhmPerV" Vector__XXX
 SG_ MtGt1IvtHVtBsPssvIstTstRsts : 48|16@1+ (0.1,0) [0|6425.5] "OhmPerV" Vector__XXX
 SG_ MtrGnrtr1InvrtrIsltnIntgrtCr : 0|8@1+ (1,0) [0|250] "count" Vector__XXX
 SG_ MtGt1IvtDSdNtvTCsssGdVt : 12|12@1+ (0.0625,-125) [-125|125.9375] "%" Vector__XXX

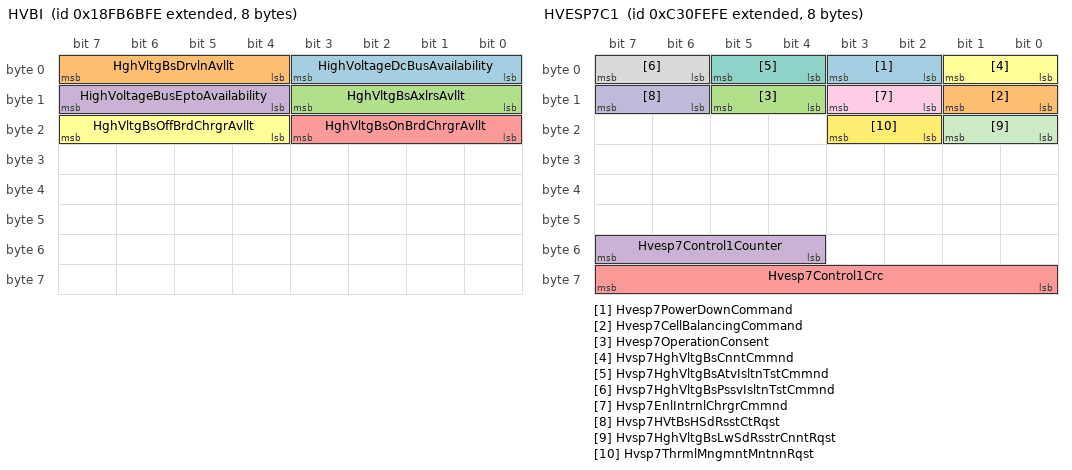
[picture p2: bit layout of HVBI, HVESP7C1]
BO_ 2566614014 HVBI: 8 Vector__XXX
 SG_ HighVoltageDcBusAvailability : 0|4@1+ (1,0) [0|15] "" Vector__XXX
 SG_ HghVltgBsDrvlnAvllt : 4|4@1+ (1,0) [0|15] "" Vector__XXX
 SG_ HghVltgBsAxlrsAvllt : 8|4@1+ (1,0) [0|15] "" Vector__XXX
 SG_ HighVoltageBusEptoAvailability : 12|4@1+ (1,0) [0|15] "" Vector__XXX
 SG_ HghVltgBsOnBrdChrgrAvllt : 16|4@1+ (1,0) [0|15] "" Vector__XXX
 SG_ HghVltgBsOffBrdChrgrAvllt : 20|4@1+ (1,0) [0|15] "" Vector__XXX

BO_ 2352021246 HVESP7C1: 8 Vector__XXX
 SG_ Hvesp7PowerDownCommand : 2|2@1+ (1,0) [0|3] "" Vector__XXX
 SG_ Hvesp7CellBalancingCommand : 8|2@1+ (1,0) [0|3] "" Vector__XXX
 SG_ Hvesp7OperationConsent : 12|2@1+ (1,0) [0|3] "" Vector__XXX
 SG_ Hvesp7Control1Counter : 52|4@1+ (1,0) [0|15] "" Vector__XXX
 SG_ Hvesp7Control1Crc : 56|8@1+ (1,0) [0|250] "count" Vector__XXX
 SG_ Hvsp7HghVltgBsCnntCmmnd : 0|2@1+ (1,0) [0|3] "" Vector__XXX
 SG_ Hvsp7HghVltgBsAtvIsltnTstCmmnd : 4|2@1+ (1,0) [0|3] "" Vector__XXX
 SG_ Hvsp7HghVltgBsPssvIsltnTstCmmnd : 6|2@1+ (1,0) [0|3] "" Vector__XXX
 SG_ Hvsp7EnlIntrnlChrgrCmmnd : 10|2@1+ (1,0) [0|3] "" Vector__XXX
 SG_ Hvsp7HVtBsHSdRsstCtRqst : 14|2@1+ (1,0) [0|3] "" Vector__XXX
 SG_ Hvsp7HghVltgBsLwSdRsstrCnntRqst : 16|2@1+ (1,0) [0|3] "" Vector__XXX
 SG_ Hvsp7ThrmlMngmntMntnnRqst : 18|2@1+ (1,0) [0|3] "" Vector__XXX

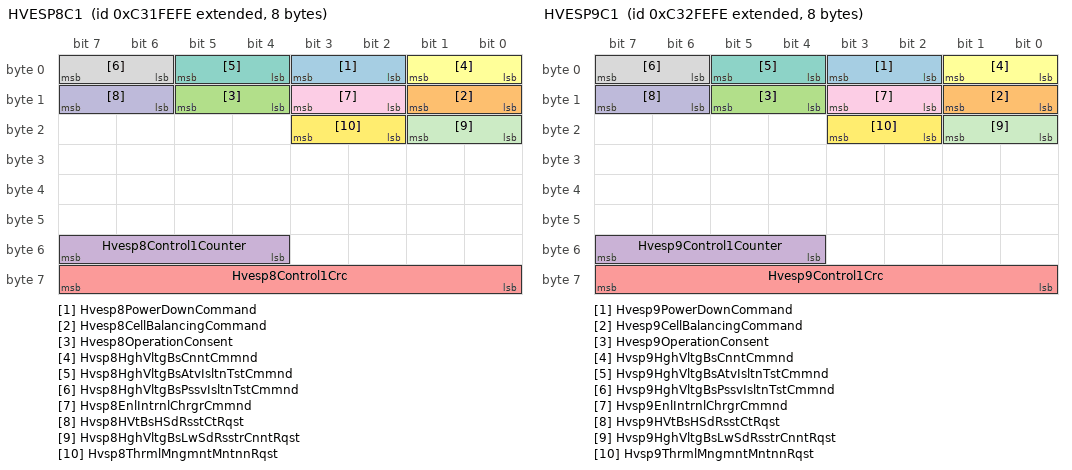
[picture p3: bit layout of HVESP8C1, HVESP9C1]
BO_ 2352086782 HVESP8C1: 8 Vector__XXX
 SG_ Hvesp8PowerDownCommand : 2|2@1+ (1,0) [0|3] "" Vector__XXX
 SG_ Hvesp8CellBalancingCommand : 8|2@1+ (1,0) [0|3] "" Vector__XXX
 SG_ Hvesp8OperationConsent : 12|2@1+ (1,0) [0|3] "" Vector__XXX
 SG_ Hvesp8Control1Counter : 52|4@1+ (1,0) [0|15] "" Vector__XXX
 SG_ Hvesp8Control1Crc : 56|8@1+ (1,0) [0|250] "count" Vector__XXX
 SG_ Hvsp8HghVltgBsCnntCmmnd : 0|2@1+ (1,0) [0|3] "" Vector__XXX
 SG_ Hvsp8HghVltgBsAtvIsltnTstCmmnd : 4|2@1+ (1,0) [0|3] "" Vector__XXX
 SG_ Hvsp8HghVltgBsPssvIsltnTstCmmnd : 6|2@1+ (1,0) [0|3] "" Vector__XXX
 SG_ Hvsp8EnlIntrnlChrgrCmmnd : 10|2@1+ (1,0) [0|3] "" Vector__XXX
 SG_ Hvsp8HVtBsHSdRsstCtRqst : 14|2@1+ (1,0) [0|3] "" Vector__XXX
 SG_ Hvsp8HghVltgBsLwSdRsstrCnntRqst : 16|2@1+ (1,0) [0|3] "" Vector__XXX
 SG_ Hvsp8ThrmlMngmntMntnnRqst : 18|2@1+ (1,0) [0|3] "" Vector__XXX

BO_ 2352152318 HVESP9C1: 8 Vector__XXX
 SG_ Hvesp9PowerDownCommand : 2|2@1+ (1,0) [0|3] "" Vector__XXX
 SG_ Hvesp9CellBalancingCommand : 8|2@1+ (1,0) [0|3] "" Vector__XXX
 SG_ Hvesp9OperationConsent : 12|2@1+ (1,0) [0|3] "" Vector__XXX
 SG_ Hvesp9Control1Counter : 52|4@1+ (1,0) [0|15] "" Vector__XXX
 SG_ Hvesp9Control1Crc : 56|8@1+ (1,0) [0|250] "count" Vector__XXX
 SG_ Hvsp9HghVltgBsCnntCmmnd : 0|2@1+ (1,0) [0|3] "" Vector__XXX
 SG_ Hvsp9HghVltgBsAtvIsltnTstCmmnd : 4|2@1+ (1,0) [0|3] "" Vector__XXX
 SG_ Hvsp9HghVltgBsPssvIsltnTstCmmnd : 6|2@1+ (1,0) [0|3] "" Vector__XXX
 SG_ Hvsp9EnlIntrnlChrgrCmmnd : 10|2@1+ (1,0) [0|3] "" Vector__XXX
 SG_ Hvsp9HVtBsHSdRsstCtRqst : 14|2@1+ (1,0) [0|3] "" Vector__XXX
 SG_ Hvsp9HghVltgBsLwSdRsstrCnntRqst : 16|2@1+ (1,0) [0|3] "" Vector__XXX
 SG_ Hvsp9ThrmlMngmntMntnnRqst : 18|2@1+ (1,0) [0|3] "" Vector__XXX

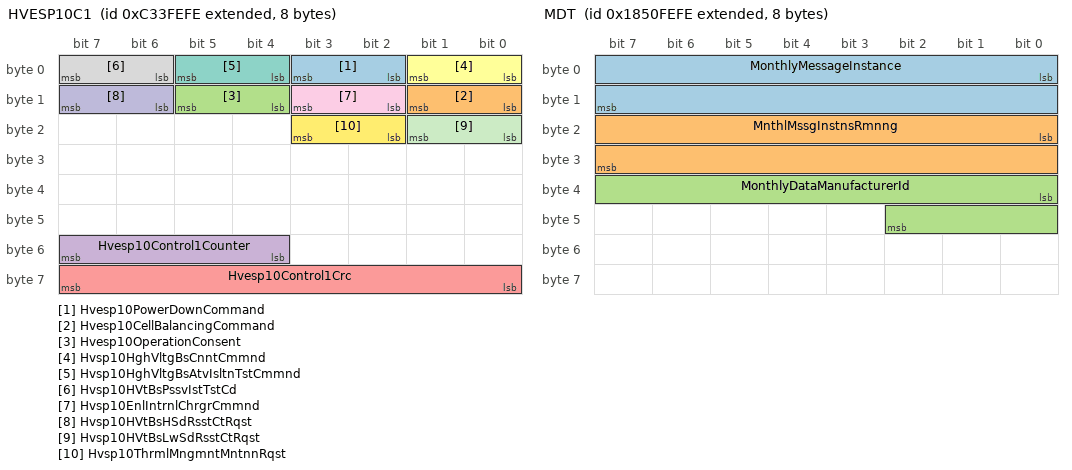
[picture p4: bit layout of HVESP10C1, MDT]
BO_ 2352217854 HVESP10C1: 8 Vector__XXX
 SG_ Hvesp10PowerDownCommand : 2|2@1+ (1,0) [0|3] "" Vector__XXX
 SG_ Hvesp10CellBalancingCommand : 8|2@1+ (1,0) [0|3] "" Vector__XXX
 SG_ Hvesp10OperationConsent : 12|2@1+ (1,0) [0|3] "" Vector__XXX
 SG_ Hvesp10Control1Counter : 52|4@1+ (1,0) [0|15] "" Vector__XXX
 SG_ Hvesp10Control1Crc : 56|8@1+ (1,0) [0|250] "count" Vector__XXX
 SG_ Hvsp10HghVltgBsCnntCmmnd : 0|2@1+ (1,0) [0|3] "" Vector__XXX
 SG_ Hvsp10HghVltgBsAtvIsltnTstCmmnd : 4|2@1+ (1,0) [0|3] "" Vector__XXX
 SG_ Hvsp10HVtBsPssvIstTstCd : 6|2@1+ (1,0) [0|3] "" Vector__XXX
 SG_ Hvsp10EnlIntrnlChrgrCmmnd : 10|2@1+ (1,0) [0|3] "" Vector__XXX
 SG_ Hvsp10HVtBsHSdRsstCtRqst : 14|2@1+ (1,0) [0|3] "" Vector__XXX
 SG_ Hvsp10HVtBsLwSdRsstCtRqst : 16|2@1+ (1,0) [0|3] "" Vector__XXX
 SG_ Hvsp10ThrmlMngmntMntnnRqst : 18|2@1+ (1,0) [0|3] "" Vector__XXX

BO_ 2555379454 DTS: 29 Vector__XXX
 SG_ DataTransferManufacturerId : 0|11@1+ (1,0) [0|2007] "" Vector__XXX
 SG_ TotalWeeklyMessageInstances : 88|16@1+ (1,0) [0|64255] "count" Vector__XXX
 SG_ LongestWeeklyMessageInstance : 104|24@1+ (1,0) [0|16449535] "count" Vector__XXX
 SG_ TotalMonthlyMessageInstances : 160|16@1+ (1,0) [0|64255] "count" Vector__XXX
 SG_ LongestMonthlyMessageInstance : 176|24@1+ (1,0) [0|16449535] "count" Vector__XXX
 SG_ TotalDailyMessageInstances : 16|16@1+ (1,0) [0|64255] "count" Vector__XXX
 SG_ LongestDailyMessageInstance : 32|24@1+ (1,0) [0|16449535] "count" Vector__XXX
 SG_ TotalDailyMessageBytes : 56|32@1+ (1,0) [0|4211081215] "count" Vector__XXX
 SG_ TotalWeeklyMessageBytes : 128|32@1+ (1,0) [0|4211081215] "count" Vector__XXX
 SG_ TotalMonthlyMessageBytes : 200|32@1+ (1,0) [0|4211081215] "count" Vector__XXX

BO_ 2555444990 MDT: 8 Vector__XXX
 SG_ MonthlyMessageInstance : 0|16@1+ (1,0) [0|64255] "count" Vector__XXX
 SG_ MnthlMssgInstnsRmnng : 16|16@1+ (1,0) [0|64255] "count" Vector__XXX
 SG_ MonthlyDataManufacturerId : 32|11@1+ (1,0) [0|2007] "" Vector__XXX

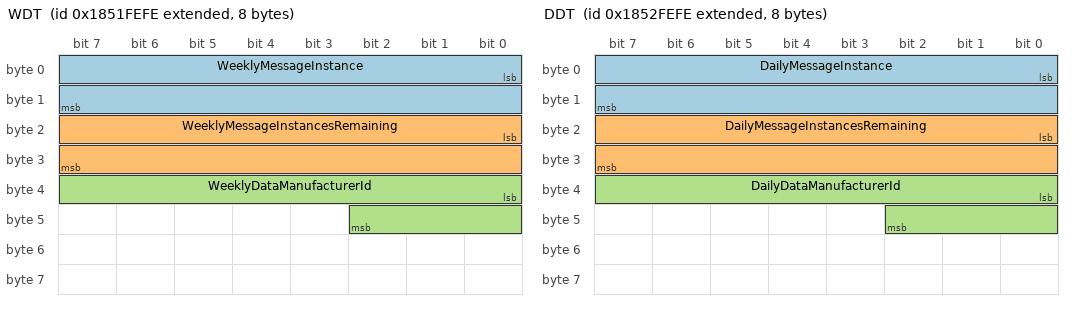
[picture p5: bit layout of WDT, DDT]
BO_ 2555510526 WDT: 8 Vector__XXX
 SG_ WeeklyMessageInstance : 0|16@1+ (1,0) [0|64255] "count" Vector__XXX
 SG_ WeeklyMessageInstancesRemaining : 16|16@1+ (1,0) [0|64255] "count" Vector__XXX
 SG_ WeeklyDataManufacturerId : 32|11@1+ (1,0) [0|2007] "" Vector__XXX

BO_ 2555576062 DDT: 8 Vector__XXX
 SG_ DailyMessageInstance : 0|16@1+ (1,0) [0|64255] "count" Vector__XXX
 SG_ DailyMessageInstancesRemaining : 16|16@1+ (1,0) [0|64255] "count" Vector__XXX
 SG_ DailyDataManufacturerId : 32|11@1+ (1,0) [0|2007] "" Vector__XXX

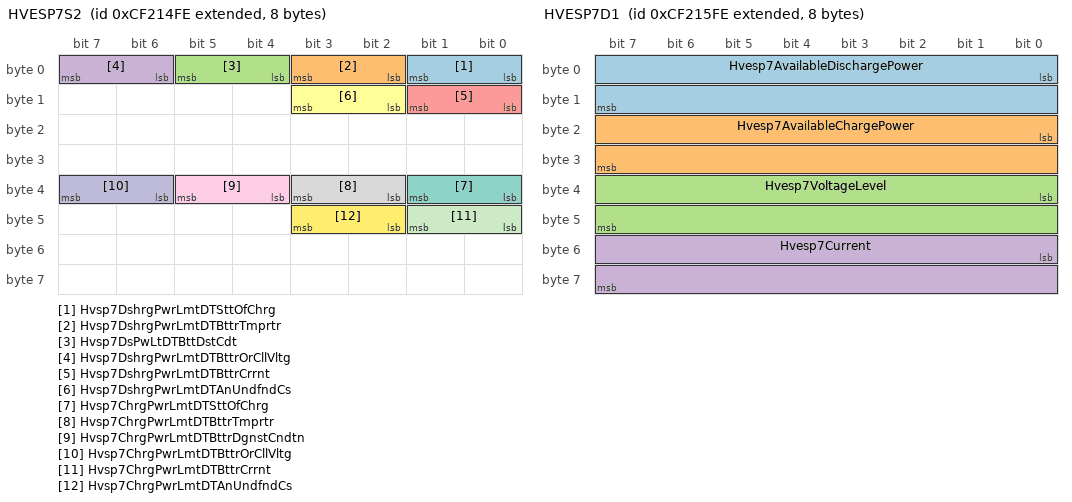
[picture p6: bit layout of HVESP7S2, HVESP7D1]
BO_ 2364675326 HVESP7S2: 8 Vector__XXX
 SG_ Hvsp7DshrgPwrLmtDTSttOfChrg : 0|2@1+ (1,0) [0|3] "" Vector__XXX
 SG_ Hvsp7DshrgPwrLmtDTBttrTmprtr : 2|2@1+ (1,0) [0|3] "" Vector__XXX
 SG_ Hvsp7DsPwLtDTBttDstCdt : 4|2@1+ (1,0) [0|3] "" Vector__XXX
 SG_ Hvsp7DshrgPwrLmtDTBttrOrCllVltg : 6|2@1+ (1,0) [0|3] "" Vector__XXX
 SG_ Hvsp7DshrgPwrLmtDTBttrCrrnt : 8|2@1+ (1,0) [0|3] "" Vector__XXX
 SG_ Hvsp7DshrgPwrLmtDTAnUndfndCs : 10|2@1+ (1,0) [0|3] "" Vector__XXX
 SG_ Hvsp7ChrgPwrLmtDTSttOfChrg : 32|2@1+ (1,0) [0|3] "" Vector__XXX
 SG_ Hvsp7ChrgPwrLmtDTBttrTmprtr : 34|2@1+ (1,0) [0|3] "" Vector__XXX
 SG_ Hvsp7ChrgPwrLmtDTBttrDgnstCndtn : 36|2@1+ (1,0) [0|3] "" Vector__XXX
 SG_ Hvsp7ChrgPwrLmtDTBttrOrCllVltg : 38|2@1+ (1,0) [0|3] "" Vector__XXX
 SG_ Hvsp7ChrgPwrLmtDTBttrCrrnt : 40|2@1+ (1,0) [0|3] "" Vector__XXX
 SG_ Hvsp7ChrgPwrLmtDTAnUndfndCs : 42|2@1+ (1,0) [0|3] "" Vector__XXX

BO_ 2364675582 HVESP7D1: 8 Vector__XXX
 SG_ Hvesp7AvailableDischargePower : 0|16@1+ (0.05,0) [0|3212.75] "kW" Vector__XXX
 SG_ Hvesp7AvailableChargePower : 16|16@1+ (0.05,0) [0|3212.75] "kW" Vector__XXX
 SG_ Hvesp7VoltageLevel : 32|16@1+ (0.05,0) [0|3212.75] "V" Vector__XXX
 SG_ Hvesp7Current : 48|16@1+ (0.05,-1600) [-1600|1612.75] "A" Vector__XXX

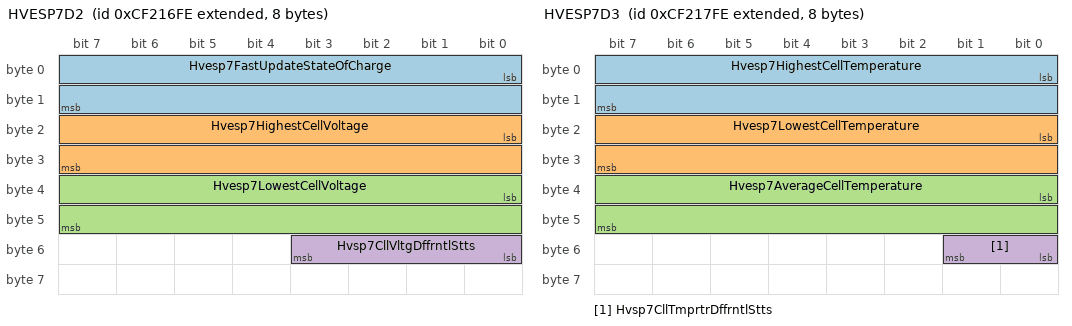
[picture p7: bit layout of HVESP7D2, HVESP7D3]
BO_ 2364675838 HVESP7D2: 8 Vector__XXX
 SG_ Hvesp7FastUpdateStateOfCharge : 0|16@1+ (0.0015625,0) [0|100.3984375] "%" Vector__XXX
 SG_ Hvesp7HighestCellVoltage : 16|16@1+ (0.001,0) [0|64.255] "V" Vector__XXX
 SG_ Hvesp7LowestCellVoltage : 32|16@1+ (0.001,0) [0|64.255] "V" Vector__XXX
 SG_ Hvsp7CllVltgDffrntlStts : 48|4@1+ (1,0) [0|15] "" Vector__XXX

BO_ 2364676094 HVESP7D3: 8 Vector__XXX
 SG_ Hvesp7HighestCellTemperature : 0|16@1+ (0.03125,-273) [-273|1734.96875] "degC" Vector__XXX
 SG_ Hvesp7LowestCellTemperature : 16|16@1+ (0.03125,-273) [-273|1734.96875] "degC" Vector__XXX
 SG_ Hvesp7AverageCellTemperature : 32|16@1+ (0.03125,-273) [-273|1734.96875] "degC" Vector__XXX
 SG_ Hvsp7CllTmprtrDffrntlStts : 48|2@1+ (1,0) [0|3] "" Vector__XXX

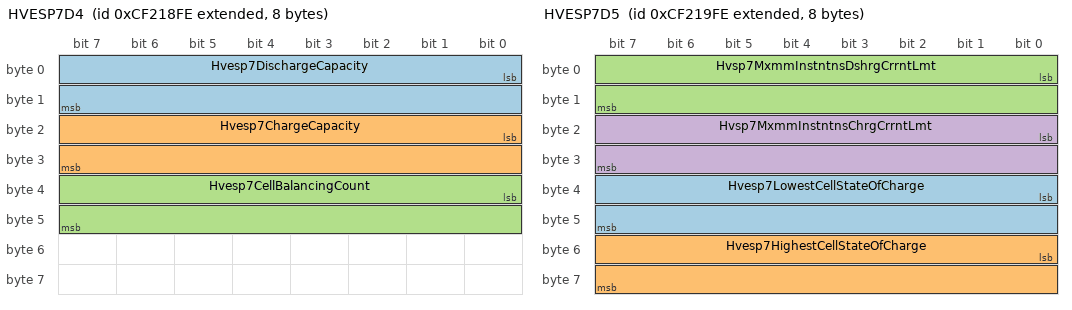
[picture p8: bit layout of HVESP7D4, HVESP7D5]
BO_ 2364676350 HVESP7D4: 8 Vector__XXX
 SG_ Hvesp7DischargeCapacity : 0|16@1+ (0.01,0) [0|642.55] "Ah" Vector__XXX
 SG_ Hvesp7ChargeCapacity : 16|16@1+ (0.01,0) [0|642.55] "Ah" Vector__XXX
 SG_ Hvesp7CellBalancingCount : 32|16@1+ (1,0) [0|64255] "count" Vector__XXX

BO_ 2364676606 HVESP7D5: 8 Vector__XXX
 SG_ Hvesp7LowestCellStateOfCharge : 32|16@1+ (0.0015625,0) [0|100.3984375] "%" Vector__XXX
 SG_ Hvesp7HighestCellStateOfCharge : 48|16@1+ (0.0015625,0) [0|100.3984375] "%" Vector__XXX
 SG_ Hvsp7MxmmInstntnsDshrgCrrntLmt : 0|16@1+ (0.05,-1600) [-1600|0] "A" Vector__XXX
 SG_ Hvsp7MxmmInstntnsChrgCrrntLmt : 16|16@1+ (0.05,-1600) [0|1612.75] "A" Vector__XXX

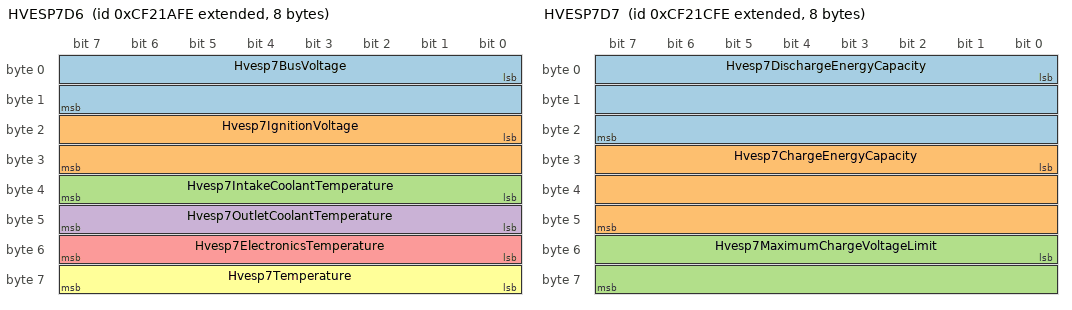
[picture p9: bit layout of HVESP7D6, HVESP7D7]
BO_ 2364676862 HVESP7D6: 8 Vector__XXX
 SG_ Hvesp7BusVoltage : 0|16@1+ (0.05,0) [0|3212.75] "V" Vector__XXX
 SG_ Hvesp7IgnitionVoltage : 16|16@1+ (0.01,0) [0|642.55] "V" Vector__XXX
 SG_ Hvesp7IntakeCoolantTemperature : 32|8@1+ (1,-40) [-40|210] "degC" Vector__XXX
 SG_ Hvesp7OutletCoolantTemperature : 40|8@1+ (1,-40) [-40|210] "degC" Vector__XXX
 SG_ Hvesp7ElectronicsTemperature : 48|8@1+ (1,-40) [-40|210] "degC" Vector__XXX
 SG_ Hvesp7Temperature : 56|8@1+ (1,-40) [-40|210] "degC" Vector__XXX

BO_ 2364677118 HVESP7S1: 8 Vector__XXX
 SG_ Hvesp7HvilStatus : 20|2@1+ (1,0) [0|3] "" Vector__XXX
 SG_ Hvesp7InertiaSwitchStatus : 22|2@1+ (1,0) [0|3] "" Vector__XXX
 SG_ Hvesp7StateOfChargeStatus : 24|4@1+ (1,0) [0|15] "" Vector__XXX
 SG_ Hvesp7CellBalanceStatus : 28|2@1+ (1,0) [0|3] "" Vector__XXX
 SG_ Hvesp7CellBalancingActive : 30|2@1+ (1,0) [0|3] "" Vector__XXX
 SG_ Hvesp7InternalChargerStatus : 32|2@1+ (1,0) [0|3] "" Vector__XXX
 SG_ Hvesp7OperationalStatus : 44|4@1+ (1,0) [0|15] "" Vector__XXX
 SG_ Hvesp7Status1Counter : 52|4@1+ (1,0) [0|15] "" Vector__XXX
 SG_ Hvesp7Status1Crc : 56|8@1+ (1,0) [0|250] "count" Vector__XXX
 SG_ Hvsp7HghVltgBsPstvCnttrStt : 0|2@1+ (1,0) [0|3] "" Vector__XXX
 SG_ Hvsp7HghVltgBsNgtvCnttrStt : 2|2@1+ (1,0) [0|3] "" Vector__XXX
 SG_ Hvsp7HghVltgBsDsnntFrwrnng : 4|4@1+ (1,0) [0|15] "" Vector__XXX
 SG_ Hvsp7HghVltgBsPrChrgRlStt : 8|2@1+ (1,0) [0|3] "" Vector__XXX
 SG_ Hvsp7CntrOfPkCnttrStt : 10|2@1+ (1,0) [0|3] "" Vector__XXX
 SG_ Hvsp7HghVltgBsAtvIsltnTstStts : 12|4@1+ (1,0) [0|15] "" Vector__XXX
 SG_ Hvsp7HghVltgBsPssvIsltnTstStts : 16|4@1+ (1,0) [0|15] "" Vector__XXX
 SG_ Hvsp7HghVltgBsCnntnStts : 40|4@1+ (1,0) [0|15] "" Vector__XXX

BO_ 2364677374 HVESP7D7: 8 Vector__XXX
 SG_ Hvesp7DischargeEnergyCapacity : 0|24@1+ (0.001,0) [0|16449.535] "kWh" Vector__XXX
 SG_ Hvesp7ChargeEnergyCapacity : 24|24@1+ (0.001,0) [0|16449.535] "kWh" Vector__XXX
 SG_ Hvesp7MaximumChargeVoltageLimit : 48|16@1+ (0.05,0) [0|3212.75] "V" Vector__XXX

CM_ BO_ 2566605566 "Motor/Generator 3 Inverter Active Power Limits";
CM_ SG_ 2566605566 MtGt3IvtPwLtdDTUddRs "Motor/Generator 3 Inverter Power Limited due to Undefined Reason: Output power is being limited due to an undefined reason.00b = No power limit for this reason01b = Power limited for this reason10b = Error11b = Not Available";
CM_ SG_ 2566605566 MtGt3IvtPwLtdDTMPwMx "Motor/Generator 3 Inverter Power Limited due to Mechanical Power Maximum: Output power is being limited due to Mechanical Power (product of SPN 11803 [Torque] and SPN 11801 [Speed]) approaching or exceeding the SPN 11835 [Inverter Limits Active Mecha...";
CM_ SG_ 2566605566 MtGt3IvtPwLtdDTMPwM "Motor/Generator 3 Inverter Power Limited due to Mechanical Power Minimum: Output power is being limited due to Mechanical Power (product of SPN 11803 [Torque] and SPN 11801 [Speed]) approaching or falling below the SPN 11836 [Inverter Limits Active M...";
CM_ SG_ 2566605566 MtrGnrtr3InvrtrPwrLmtdDTTrqMxmm "Motor/Generator 3 Inverter Power Limited due to Torque Maximum: Output power is being limited due to SPN 11803 [Torque] approaching or exceeding the SPN 11847 [Inverter Limits Active Torque Maximum].00b = No power limit for this reason01b = Power lim...";
CM_ SG_ 2566605566 MtrGnrtr3InvrtrPwrLmtdDTTrqMnmm "Motor/Generator 3 Inverter Power Limited due to Torque Minimum: Output power is being limited due to SPN 11803 [Torque] approaching or falling below the SPN 11848 [Inverter Limits Active Torque Minimum].00b = No power limit for this reason01b = Power...";
CM_ SG_ 2566605566 MtrGnrtr3InvrtrPwrLmtdDTSpdMxmm "Motor/Generator 3 Inverter Power Limited due to Speed Maximum: Output power is being limited due to SPN 11801 [Speed] approaching or exceeding the SPN 11849 [Inverter Limits Active Speed Maximum].00b = No power limit for this reason01b = Power limite...";
CM_ SG_ 2566605566 MtrGnrtr3InvrtrPwrLmtdDTSpdMnmm "Motor/Generator 3 Inverter Power Limited due to Speed Minimum: Output power is being limited due to SPN 11801 [Speed] approaching or falling below the SPN 11850 [Inverter Limits Active Speed Minimum].00b = No power limit for this reason01b = Power li...";
CM_ SG_ 2566605566 MtGt3IvtPwLtdDTIvtTpt "Motor/Generator 3 Inverter Power Limited due to Inverter Temperature: Output power is being limited due to one or more inverter temperature(s), see SPNs 11867 through 11870 [Inverter Temperature 1-4] approaching or exceeding internally defined limit(...";
CM_ SG_ 2566605566 MtGt3IvtPwLtdDTMtTpt "Motor/Generator 3 Inverter Power Limited due to Motor Temperature: Output power is being limited due to one or more motor temperature(s), see SPNs 11802 and 11871 through 11873 [Motor Temperature 1-4] approaching or exceeding internally defined limit...";
CM_ SG_ 2566605566 MtGt3IvtPwLtdDTFtCdt "Motor/Generator 3 Inverter Power Limited Due to Fault Condition: Output power is being limited due to an fault condition that requires a torque limitation to prevent further damage (e.g. 'limp home mode').  For example, this could be in case of tempe...";
CM_ SG_ 2566605566 MtGt3IvtPwLtdDTAtvTqRtLt "Motor/Generator 3 Inverter Power Limited Due to Active Torque Rate Limit: Output power is being limited due to exceeding internally defined torque rate limit(s) or SPN 11907 [Inverter Rate Limits Request Absolute Torque Rate Limit].00b = No power lim...";
CM_ SG_ 2566605566 MtGt3IvtPwLtdDTAtvSpdRtLt "Motor/Generator 3 Inverter Power Limited Due to Active Speed Rate Limit: Output power is being limited due to exceeding internally defined speed rate limit(s) or SPN 11906 [Inverter Rate Limits Request Absolute Speed Rate Limit].00b = No power limit ...";
CM_ SG_ 2566605566 MtGt3IvtTqLtdDTMCtsts "Motor/Generator 3 Inverter Torque Limited Due to Machine Characteristics: Output torque is being limited due to SPN 11803 [Torque] approaching or exceeding a motor design characteristic.  For example, for permanent magnet machines, this would be in t...";
CM_ SG_ 2566605566 MtGt3IvtPwLtdDTDSdCtMx "Motor/Generator 3 Inverter Power Limited due to DC Side Current Maximum: Output power is being limited due to SPN 11826 [Inverter DC Side Current] approaching or exceeding the SPN 11865 [Inverter Limits Active DC Side Current Maximum].00b = No power ...";
CM_ SG_ 2566605566 MtGt3IvtPwLtdDTDSdCtM "Motor/Generator 3 Inverter Power Limited due to DC Side Current Minimum: Output power is being limited due to SPN 11826 [Inverter DC Side Current] approaching or falling below the SPN 11866 [Inverter Limits Active DC Side Current Minimum].00b = No po...";
CM_ SG_ 2566605566 MtGt3IvtPwLtdDTDSdVtMx "Motor/Generator 3 Inverter Power Limited due to DC Side Voltage Maximum: Output power is being limited due to SPN 11804 [Inverter DC Side Voltage] approaching or exceeding the SPN 11863 [Inverter Limits Active DC Side Voltage Maximum].00b = No power ...";
CM_ SG_ 2566605566 MtGt3IvtPwLtdDTDSdVtM "Motor/Generator 3 Inverter Power Limited due to DC Side Voltage Minimum: Output power is being limited due to SPN 11804 [Inverter DC Side Voltage] approaching or falling below the SPN 11864 [Inverter Limits Active DC Side Voltage Minimum].00b = No po...";
CM_ SG_ 2566605566 MtGt3IvtPwLtdDTDSdPwMx "Motor/Generator 3 Inverter Power Limited due to DC Side Power Maximum: Output power is being limited due to DC Side Power (product of SPN 11826 [Inverter DC Side Current] and SPN 11804 [Inverter DC Side Voltage]) approaching or exceeding the SPN 1183...";
CM_ SG_ 2566605566 MtGt3IvtPwLtdDTDSdPwM "Motor/Generator 3 Inverter Power Limited due to DC Side Power Minimum: Output power is being limited due to DC Side Power (product of SPN 11826 [Inverter DC Side Current] and SPN 11804 [Inverter DC Side Voltage]) approaching or falling below the SPN ...";
CM_ BO_ 2566605822 "Automated Driving System Status 1";
CM_ SG_ 2566605822 SAddssOCtDvFTs1CtPpsP7 "Source Address of Controlling Device for TSC1 Control Purpose P7: THe source address of the SAE J1939 device that is currently sending a TSC1 message with control purpose P7 that is actively controlling or limiting the power system output.254 (FEh) i...";
CM_ SG_ 2566605822 Ts1CntrlPrpsP7RdnssStts "TSC1 Control Purpose P7 Readiness Status: This parameter is used to indicate an application's state of readiness for responding to TSC1 Control Purpose P7 (see SPN 3350) messages.00b = Not Ready01b = Ready10b = Error11b = Not Available/Not Supported....";
CM_ SG_ 2566605822 AdsVhlSpdCntrlCmmndRdnssStts "ADS Vehicle Speed Control Command Readiness Status: Used to indicate the recipient's state of readiness for responding to ADS Vehicle Speed Control Command (SPN 15248) of the automated driving system (ADS).00b = Not Ready01b = Ready10b = Error11b = N...";
CM_ SG_ 2566605822 SAddssOCtDvFAdsVSpdCtCd "Source Address of Controlling Device for ADS Vehicle Speed Control Command: The receiving application is currently acting upon the ADS Vehicle Speed Control Command (SPN 15248) of the automated driving system (ADS) from this source address.Note:254 (...";
CM_ SG_ 2566605822 AdsVhlSpdCntrlCmmndFdk "ADS Vehicle Speed Control Command Feedback: This parameter represents the current vehicle speed commanded by the automated driving system (ADS) via ADS Vehicle Speed Control Command (SPN 15248).Note: 0xFB00 denotes no ADS Vehicle Speed Control is bei...";
CM_ SG_ 2566605822 AdsVhlSpdCntrlOprtnStts "ADS Vehicle Speed Control Operation Status: Used to indicate the operation status of the application responding to the ADS Vehicle Speed Control Command (SPN 15248).000b = ADS Vehicle Speed Control Command Not Active001b = Maximum Positive Torque010b...";
CM_ SG_ 2566605822 Adss1EmbeddedIntegritySupport "ADSS1 Embedded Integrity Support: Indicates that SPN 23058 (ADSS1 CRC) and SPN 23057 (ADSS1 Counter) are supported by the sender.00b = ADSS1 embedded CRC and Counter are supported by the sender01b = ADSS1 protection is provided using an external (not...";
CM_ SG_ 2566605822 Adss1Counter "ADSS1 Counter: The message counter is used to detect situations where the transmitting ECU malfunction repeats the same frame all the time. The receiver of the information may use the counter parameter to detect this situation. The transmitting devic...";
CM_ SG_ 2566605822 Adss1Crc "ADSS1 CRC: The CRC is defined as follows:  - Length: 8 bits  - Polynomial: x^8+x^5+x^3+x^2+x+1  - Initial Value: FFh  - Input Data Reflection: Not reflected  - Result Data Reflection: Not reflected  - XOR value: FFhSAE makes no claim of the functiona...";
CM_ BO_ 2566606078 "Cab Climate System Information 2";
CM_ SG_ 2566606078 CabHeaterPower "Cab Heater Power: Electrical power consumed by the cab heater.";
CM_ SG_ 2566606078 CabACCompressorPower "Cab A/C Compressor Power: Electrical power consumed by the Cab A/C Compressor. ";
CM_ BO_ 2566606334 "Maintenance Information";
CM_ SG_ 2566606334 EngineAirFilter1LifeRemaining "Engine Air Filter 1 Life Remaining: Signal which indicates an actual life remaining in percent of the engine air filter #1. 0% represents no life remaining in the filter and 100% represents a new filter with full life remaining.";
CM_ SG_ 2566606334 EngineAirFilter2LifeRemaining "Engine Air Filter 2 Life Remaining: Signal which indicates an actual life remaining in percent of the engine air filter #2. 0% represents no life remaining in the filter and 100% represents a new filter with full life remaining.";
CM_ SG_ 2566606334 EngineAirFilter3LifeRemaining "Engine Air Filter 3 Life Remaining: Signal which indicates an actual life remaining in percent of the engine air filter #3. 0% represents no life remaining in the filter and 100% represents a new filter with full life remaining.";
CM_ SG_ 2566606334 EngineAirFilter4LifeRemaining "Engine Air Filter 4 Life Remaining: Signal which indicates an actual life remaining in percent of the engine air filter #4. 0% represents no life remaining in the filter and 100% represents a new filter with full life remaining.";
CM_ SG_ 2566606334 EngineFuelFilterLifeRemaining "Engine Fuel Filter Life Remaining: Signal which indicates an actual life remaining in percent of the engine fuel filter.  0% represents no life remaining in the filter and 100% represents a new filter with full life remaining.";
CM_ SG_ 2566606334 EngnFlFltrStnSdLfRmnng "Engine Fuel Filter (Suction Side) Life Remaining: Signal which indicates an actual life remaining in percent of the engine suction side fuel filter.  0% represents no life remaining in the filter and 100% represents a new filter with full life remain...";
CM_ SG_ 2566606334 EngineOilFilterLifeRemaining "Engine Oil Filter Life Remaining: Signal which indicates an actual life remaining in percent of the engine oil filter.  0% represents no life remaining in the filter and 100% represents a new filter with full life remaining.";
CM_ SG_ 2566606334 TrnsmssnOlFltrLfRmnng "Transmission OIl Filter Life Remaining: Signal which indicates an actual life remaining in percent of the transmission oil filter.  0% represents no life remaining in the filter and 100% represents a new filter with full life remaining.";
CM_ BO_ 2499497726 "Hoist Control Information";
CM_ SG_ 2499497726 HoistLeverPosition "Hoist Lever Position: The position of the operator's hoist control lever (used for a dump body) relative to travel from a neutral (center) position.  Position value of 0 indicates the lever is in the neutral (central) position where no hoist movement...";
CM_ SG_ 2499497726 HoistLeverDetentPositionStatus "Hoist Lever Detent Position Status: The status of the hoist lever (used for a dump body) in the detent position for either direction of travel.  00b = Not in the Detent Position01b = In the Detent Position10b = Error Indicator11b = Not Available...";
CM_ BO_ 2633715710 "High Voltage Energy Storage Pack 6 History";
CM_ SG_ 2633715710 Hvesp6StateOfHealth "HVESP6 State of Health: This signal represents the expected remaining Life of this High Voltage Energy Storage Pack instance, in percent.  Battery life is a manufacturer-specific measure of how well the energy storage system is functioning relative t...";
CM_ SG_ 2633715710 Hvesp6TotalEnergyThroughput "HVESP6 Total Energy Throughput: The total energy throughput which has flowed through this High Voltage Energy Storage Pack instance.  This parameter is the sum of the absolute values of the Energy into and out of this HVES instance.  This parameter i...";
CM_ SG_ 2633715710 Hvesp6TotalAccumulatedCharge "HVESP6 Total Accumulated Charge: The total accumulated amp hours which have flowed through this High Voltage Energy Storage Pack instance.  This parameter is the sum of the absolute values of the Ampere hours into and out of this HVES instance.  This...";
CM_ SG_ 2633715710 Hvesp6TotalLifetimeEnergyInput "HVESP6 Total Lifetime Energy Input: The cumulative energy which has flowed into this High Voltage Energy Storage Pack instance over the lifetime of the battery pack. This parameter is the sum of the Energy into this HVES instance.  This value is rese...";
CM_ SG_ 2633715710 Hvesp6TotalLifetimeEnergyOutput "HVESP6 Total Lifetime Energy Output: The cumulative energy which has flowed out of this High Voltage Energy Storage Pack instance over the lifetime of the battery pack. This parameter is the sum of the Energy out of this HVES instance. This value is ...";
CM_ SG_ 2633715710 Hvsp6CnttrOpnUndrLdCnt "HVESP6 Contactor Open Under Load Count: This signal represents the number of times the contactors inside this High Voltage Energy Storage Pack instance have opened while current is flowing through them.  The current level (that determines if an openi...";
CM_ BO_ 2566607102 "High Voltage Energy Storage Pack 6 Configuration";
CM_ SG_ 2566607102 Hvesp6NominalVoltage "HVESP6 Nominal Voltage: Per the HVES manufacturer, this is the nominal operating voltage of this High Voltage Energy Storage Pack instance, e.g. '300V' or '600V'.This parameter is for one of multiple packs in an HVESS.  If there is only one pack in t...";
CM_ SG_ 2566607102 Hvesp6CellMaximumVoltageLimit "HVESP6 Cell Maximum Voltage Limit: Per the HVES manufacturer, this is the maximum cell voltage for this High Voltage Energy Storage Pack instance operation.  Operating above this value may damage HVES hardware, or compromise HVES life.This parameter ...";
CM_ SG_ 2566607102 Hvesp6CellMinimumVoltageLimit "HVESP6 Cell Minimum Voltage Limit: Per the HVES manufacturer, this is the minimum cell voltage for this High Voltage Energy Storage Pack instance operation.  Operating below this value may damage HVES hardware, or compromise HVES life.This parameter ...";
CM_ SG_ 2566607102 Hvsp6RmmnddMnmmOprtngVltg "HVESP6 Recommended Minimum Operating Voltage: Per the HVES manufacturer, this is the minimum recommended voltage level for this High Voltage Energy Storage Pack instance operation.  Operating below this value may compromise HVES life.This parameter i...";
CM_ SG_ 2566607102 Hvsp6RmmnddMxmmOprtngVltg "HVESP6 Recommended Maximum Operating Voltage: Per the HVES manufacturer, this is the maximum recommended voltage level for this High Voltage Energy Storage Pack instance operation.  Operating above this value may compromise HVES life.This parameter i...";
CM_ SG_ 2566607102 Hvsp6RmmnddMnmmSttOfChrg "HVESP6 Recommended Minimum State Of Charge: Per the HVES manufacturer, this is the recommended minimum state of charge for this High Voltage Energy Storage Pack instance operation.  Operating below this value may compromise HVES life.This parameter i...";
CM_ SG_ 2566607102 Hvsp6RmmnddMxmmSttOfChrg "HVESP6 Recommended Maximum State Of Charge: Per the HVES manufacturer, this is the recommended maximum state of charge for this High Voltage Energy Storage Pack instance operation.  Operating above this value may compromise HVES life.This parameter i...";
CM_ SG_ 2566607102 Hvsp6RmmnddMxmmOprtngTmprtr "HVESP6 Recommended Maximum Operating Temperature: Per the HVES manufacturer, this is the recommended maximum temperature for this High Voltage Energy Storage Pack instance operation.  Operating above this value may damage HVES hardware, or compromise...";
CM_ SG_ 2566607102 Hvsp6RmmnddMnmmOprtngTmprtr "HVESP6 Recommended Minimum Operating Temperature: Per the HVES manufacturer, this is the recommended minimum temperature for this High Voltage Energy Storage Pack instance operation.  Operating below this value may damage HVES hardware, or compromise...";
CM_ SG_ 2566607102 Hvesp6NominalRatedCapacity "HVESP6 Nominal Rated Capacity: Per the HVES manufacturer, this is the manufacturer's nominal rated capacity of this instance of the energy storage system.  The rated capacity does not change over the life of the HVES.This parameter is for one of mult...";
CM_ BO_ 2633716222 "High Voltage Energy Storage Pack 5 History";
CM_ SG_ 2633716222 Hvesp5StateOfHealth "HVESP5 State of Health: This signal represents the expected remaining Life of this High Voltage Energy Storage Pack instance, in percent.  Battery life is a manufacturer-specific measure of how well the energy storage system is functioning relative t...";
CM_ SG_ 2633716222 Hvesp5TotalEnergyThroughput "HVESP5 Total Energy Throughput: The total energy throughput which has flowed through this High Voltage Energy Storage Pack instance.  This parameter is the sum of the absolute values of the Energy into and out of this HVES instance.  This parameter i...";
CM_ SG_ 2633716222 Hvesp5TotalAccumulatedCharge "HVESP5 Total Accumulated Charge: The total accumulated amp hours which have flowed through this High Voltage Energy Storage Pack instance.  This parameter is the sum of the absolute values of the Ampere hours into and out of this HVES instance.  This...";
CM_ SG_ 2633716222 Hvesp5TotalLifetimeEnergyInput "HVESP5 Total Lifetime Energy Input: The cumulative energy which has flowed into this High Voltage Energy Storage Pack instance over the lifetime of the battery pack. This parameter is the sum of the Energy into this HVES instance. This value is reset...";
CM_ SG_ 2633716222 Hvesp5TotalLifetimeEnergyOutput "HVESP5 Total Lifetime Energy Output: The cumulative energy which has flowed out of this High Voltage Energy Storage Pack instance over the lifetime of the battery pack. This parameter is the sum of the Energy out of this HVES instance. This value is ...";
CM_ SG_ 2633716222 Hvsp5CnttrOpnUndrLdCnt "HVESP5 Contactor Open Under Load Count: This signal represents the number of times the contactors inside this High Voltage Energy Storage Pack instance have opened while current is flowing through them.  The current level (that determines if an openi...";
CM_ BO_ 2566607614 "High Voltage Energy Storage Pack 5 Configuration";
CM_ SG_ 2566607614 Hvesp5NominalVoltage "HVESP5 Nominal Voltage: Per the HVES manufacturer, this is the nominal operating voltage of this High Voltage Energy Storage Pack instance, e.g. '300V' or '600V'.This parameter is for one of multiple packs in an HVESS.  If there is only one pack in t...";
CM_ SG_ 2566607614 Hvesp5CellMaximumVoltageLimit "HVESP5 Cell Maximum Voltage Limit: Per the HVES manufacturer, this is the maximum cell voltage for this High Voltage Energy Storage Pack instance operation.  Operating above this value may damage HVES hardware, or compromise HVES life.This parameter ...";
CM_ SG_ 2566607614 Hvesp5CellMinimumVoltageLimit "HVESP5 Cell Minimum Voltage Limit: Per the HVES manufacturer, this is the minimum cell voltage for this High Voltage Energy Storage Pack instance operation.  Operating below this value may damage HVES hardware, or compromise HVES life.This parameter ...";
CM_ SG_ 2566607614 Hvsp5RmmnddMnmmOprtngVltg "HVESP5 Recommended Minimum Operating Voltage: Per the HVES manufacturer, this is the minimum recommended voltage level for this High Voltage Energy Storage Pack instance operation.  Operating below this value may compromise HVES life.This parameter i...";
CM_ SG_ 2566607614 Hvsp5RmmnddMxmmOprtngVltg "HVESP5 Recommended Maximum Operating Voltage: Per the HVES manufacturer, this is the maximum recommended voltage level for this High Voltage Energy Storage Pack instance operation.  Operating above this value may compromise HVES life.This parameter i...";
CM_ SG_ 2566607614 Hvsp5RmmnddMnmmSttOfChrg "HVESP5 Recommended Minimum State Of Charge: Per the HVES manufacturer, this is the recommended minimum state of charge for this High Voltage Energy Storage Pack instance operation.  Operating below this value may compromise HVES life.This parameter i...";
CM_ SG_ 2566607614 Hvsp5RmmnddMxmmSttOfChrg "HVESP5 Recommended Maximum State Of Charge: Per the HVES manufacturer, this is the recommended maximum state of charge for this High Voltage Energy Storage Pack instance operation.  Operating above this value may compromise HVES life.This parameter i...";
CM_ SG_ 2566607614 Hvsp5RmmnddMxmmOprtngTmprtr "HVESP5 Recommended Maximum Operating Temperature: Per the HVES manufacturer, this is the recommended maximum temperature for this High Voltage Energy Storage Pack instance operation.  Operating above this value may damage HVES hardware, or compromise...";
CM_ SG_ 2566607614 Hvsp5RmmnddMnmmOprtngTmprtr "HVESP5 Recommended Minimum Operating Temperature: Per the HVES manufacturer, this is the recommended minimum temperature for this High Voltage Energy Storage Pack instance operation.  Operating below this value may damage HVES hardware, or compromise...";
CM_ SG_ 2566607614 Hvesp5NominalRatedCapacity "HVESP5 Nominal Rated Capacity: Per the HVES manufacturer, this is the manufacturer's nominal rated capacity of this instance of the energy storage system.  The rated capacity does not change over the life of the HVES.This parameter is for one of mult...";
CM_ BO_ 2633716734 "High Voltage Energy Storage Pack 4 History";
CM_ SG_ 2633716734 Hvesp4StateOfHealth "HVESP4 State of Health: This signal represents the expected remaining Life of this High Voltage Energy Storage Pack instance, in percent.  Battery life is a manufacturer-specific measure of how well the energy storage system is functioning relative t...";
CM_ SG_ 2633716734 Hvesp4TotalEnergyThroughput "HVESP4 Total Energy Throughput: The total energy throughput which has flowed through this High Voltage Energy Storage Pack instance.  This parameter is the sum of the absolute values of the Energy into and out of this HVES instance.  This parameter i...";
CM_ SG_ 2633716734 Hvesp4TotalAccumulatedCharge "HVESP4 Total Accumulated Charge: The total accumulated amp hours which have flowed through this High Voltage Energy Storage Pack instance.  This parameter is the sum of the absolute values of the Ampere hours into and out of this HVES instance.  This...";
CM_ SG_ 2633716734 Hvesp4TotalLifetimeEnergyInput "HVESP4 Total Lifetime Energy Input: The cumulative energy which has flowed into this High Voltage Energy Storage Pack instance over the lifetime of the battery pack. This parameter is the sum of the Energy into this HVES instance. This value is reset...";
CM_ SG_ 2633716734 Hvesp4TotalLifetimeEnergyOutput "HVESP4 Total Lifetime Energy Output: The cumulative energy which has flowed out of this High Voltage Energy Storage Pack instance over the lifetime of the battery pack. This parameter is the sum of the Energy out of this HVES instance. This value is ...";
CM_ SG_ 2633716734 Hvsp4CnttrOpnUndrLdCnt "HVESP4 Contactor Open Under Load Count: This signal represents the number of times the contactors inside this High Voltage Energy Storage Pack instance have opened while current is flowing through them.  The current level (that determines if an openi...";
CM_ BO_ 2566608126 "High Voltage Energy Storage Pack 4 Configuration";
CM_ SG_ 2566608126 Hvesp4NominalVoltage "HVESP4 Nominal Voltage: Per the HVES manufacturer, this is the nominal operating voltage of this High Voltage Energy Storage Pack instance, e.g. '300V' or '600V'.This parameter is for one of multiple packs in an HVESS.  If there is only one pack in t...";
CM_ SG_ 2566608126 Hvesp4CellMaximumVoltageLimit "HVESP4 Cell Maximum Voltage Limit: Per the HVES manufacturer, this is the maximum cell voltage for this High Voltage Energy Storage Pack instance operation.  Operating above this value may damage HVES hardware, or compromise HVES life.This parameter ...";
CM_ SG_ 2566608126 Hvesp4CellMinimumVoltageLimit "HVESP4 Cell Minimum Voltage Limit: Per the HVES manufacturer, this is the minimum cell voltage for this High Voltage Energy Storage Pack instance operation.  Operating below this value may damage HVES hardware, or compromise HVES life.This parameter ...";
CM_ SG_ 2566608126 Hvsp4RmmnddMnmmOprtngVltg "HVESP4 Recommended Minimum Operating Voltage: Per the HVES manufacturer, this is the minimum recommended voltage level for this High Voltage Energy Storage Pack instance operation.  Operating below this value may compromise HVES life.This parameter i...";
CM_ SG_ 2566608126 Hvsp4RmmnddMxmmOprtngVltg "HVESP4 Recommended Maximum Operating Voltage: Per the HVES manufacturer, this is the maximum recommended voltage level for this High Voltage Energy Storage Pack instance operation.  Operating above this value may compromise HVES life.This parameter i...";
CM_ SG_ 2566608126 Hvsp4RmmnddMnmmSttOfChrg "HVESP4 Recommended Minimum State Of Charge: Per the HVES manufacturer, this is the recommended minimum state of charge for this High Voltage Energy Storage Pack instance operation.  Operating below this value may compromise HVES life.This parameter i...";
CM_ SG_ 2566608126 Hvsp4RmmnddMxmmSttOfChrg "HVESP4 Recommended Maximum State Of Charge: Per the HVES manufacturer, this is the recommended maximum state of charge for this High Voltage Energy Storage Pack instance operation.  Operating above this value may compromise HVES life.This parameter i...";
CM_ SG_ 2566608126 Hvsp4RmmnddMxmmOprtngTmprtr "HVESP4 Recommended Maximum Operating Temperature: Per the HVES manufacturer, this is the recommended maximum temperature for this High Voltage Energy Storage Pack instance operation.  Operating above this value may damage HVES hardware, or compromise...";
CM_ SG_ 2566608126 Hvsp4RmmnddMnmmOprtngTmprtr "HVESP4 Recommended Minimum Operating Temperature: Per the HVES manufacturer, this is the recommended minimum temperature for this High Voltage Energy Storage Pack instance operation.  Operating below this value may damage HVES hardware, or compromise...";
CM_ SG_ 2566608126 Hvesp4NominalRatedCapacity "HVESP4 Nominal Rated Capacity: Per the HVES manufacturer, this is the manufacturer's nominal rated capacity of this instance of the energy storage system.  The rated capacity does not change over the life of the HVES.This parameter is for one of mult...";
CM_ BO_ 2633717246 "High Voltage Energy Storage Pack 3 History";
CM_ SG_ 2633717246 Hvesp3StateOfHealth "HVESP3 State of Health: This signal represents the expected remaining Life of this High Voltage Energy Storage Pack instance, in percent.  Battery life is a manufacturer-specific measure of how well the energy storage system is functioning relative t...";
CM_ SG_ 2633717246 Hvesp3TotalEnergyThroughput "HVESP3 Total Energy Throughput: The total energy throughput which has flowed through this High Voltage Energy Storage Pack instance.  This parameter is the sum of the absolute values of the Energy into and out of this HVES instance.  This parameter i...";
CM_ SG_ 2633717246 Hvesp3TotalAccumulatedCharge "HVESP3 Total Accumulated Charge: The total accumulated amp hours which have flowed through this High Voltage Energy Storage Pack instance.  This parameter is the sum of the absolute values of the Ampere hours into and out of this HVES instance.  This...";
CM_ SG_ 2633717246 Hvesp3TotalLifetimeEnergyInput "HVESP3 Total Lifetime Energy Input: The cumulative energy which has flowed into this High Voltage Energy Storage Pack instance over the lifetime of the battery pack. This parameter is the sum of the Energy into this HVES instance. This value is reset...";
CM_ SG_ 2633717246 Hvesp3TotalLifetimeEnergyOutput "HVESP3 Total Lifetime Energy Output: The cumulative energy which has flowed out of this High Voltage Energy Storage Pack instance over the lifetime of the battery pack. This parameter is the sum of the Energy out of this HVES instance. This value is ...";
CM_ SG_ 2633717246 Hvsp3CnttrOpnUndrLdCnt "HVESP3 Contactor Open Under Load Count: This signal represents the number of times the contactors inside this High Voltage Energy Storage Pack instance have opened while current is flowing through them.  The current level (that determines if an openi...";
CM_ BO_ 2566608638 "High Voltage Energy Storage Pack 3 Configuration";
CM_ SG_ 2566608638 Hvesp3NominalVoltage "HVESP3 Nominal Voltage: Per the HVES manufacturer, this is the nominal operating voltage of this High Voltage Energy Storage Pack instance, e.g. '300V' or '600V'.This parameter is for one of multiple packs in an HVESS.  If there is only one pack in t...";
CM_ SG_ 2566608638 Hvesp3CellMaximumVoltageLimit "HVESP3 Cell Maximum Voltage Limit: Per the HVES manufacturer, this is the maximum cell voltage for this High Voltage Energy Storage Pack instance operation.  Operating above this value may damage HVES hardware, or compromise HVES life.This parameter ...";
CM_ SG_ 2566608638 Hvesp3CellMinimumVoltageLimit "HVESP3 Cell Minimum Voltage Limit: Per the HVES manufacturer, this is the minimum cell voltage for this High Voltage Energy Storage Pack instance operation.  Operating below this value may damage HVES hardware, or compromise HVES life.This parameter ...";
CM_ SG_ 2566608638 Hvsp3RmmnddMnmmOprtngVltg "HVESP3 Recommended Minimum Operating Voltage: Per the HVES manufacturer, this is the minimum recommended voltage level for this High Voltage Energy Storage Pack instance operation.  Operating below this value may compromise HVES life.This parameter i...";
CM_ SG_ 2566608638 Hvsp3RmmnddMxmmOprtngVltg "HVESP3 Recommended Maximum Operating Voltage: Per the HVES manufacturer, this is the maximum recommended voltage level for this High Voltage Energy Storage Pack instance operation.  Operating above this value may compromise HVES life.This parameter i...";
CM_ SG_ 2566608638 Hvsp3RmmnddMnmmSttOfChrg "HVESP3 Recommended Minimum State Of Charge: Per the HVES manufacturer, this is the recommended minimum state of charge for this High Voltage Energy Storage Pack instance operation.  Operating below this value may compromise HVES life.This parameter i...";
CM_ SG_ 2566608638 Hvsp3RmmnddMxmmSttOfChrg "HVESP3 Recommended Maximum State Of Charge: Per the HVES manufacturer, this is the recommended maximum state of charge for this High Voltage Energy Storage Pack instance operation.  Operating above this value may compromise HVES life.This parameter i...";
CM_ SG_ 2566608638 Hvsp3RmmnddMxmmOprtngTmprtr "HVESP3 Recommended Maximum Operating Temperature: Per the HVES manufacturer, this is the recommended maximum temperature for this High Voltage Energy Storage Pack instance operation.  Operating above this value may damage HVES hardware, or compromise...";
CM_ SG_ 2566608638 Hvsp3RmmnddMnmmOprtngTmprtr "HVESP3 Recommended Minimum Operating Temperature: Per the HVES manufacturer, this is the recommended minimum temperature for this High Voltage Energy Storage Pack instance operation.  Operating below this value may damage HVES hardware, or compromise...";
CM_ SG_ 2566608638 Hvesp3NominalRatedCapacity "HVESP3 Nominal Rated Capacity: Per the HVES manufacturer, this is the manufacturer's nominal rated capacity of this instance of the energy storage system.  The rated capacity does not change over the life of the HVES.This parameter is for one of mult...";
CM_ BO_ 2633717758 "High Voltage Energy Storage Pack 2 History";
CM_ SG_ 2633717758 Hvesp2StateOfHealth "HVESP2 State of Health: This signal represents the expected remaining Life of this High Voltage Energy Storage Pack instance, in percent.  Battery life is a manufacturer-specific measure of how well the energy storage system is functioning relative t...";
CM_ SG_ 2633717758 Hvesp2TotalEnergyThroughput "HVESP2 Total Energy Throughput: The total energy throughput which has flowed through this High Voltage Energy Storage Pack instance.  This parameter is the sum of the absolute values of the Energy into and out of this HVES instance.  This parameter i...";
CM_ SG_ 2633717758 Hvesp2TotalAccumulatedCharge "HVESP2 Total Accumulated Charge: The total accumulated amp hours which have flowed through this High Voltage Energy Storage Pack instance.  This parameter is the sum of the absolute values of the Ampere hours into and out of this HVES instance.  This...";
CM_ SG_ 2633717758 Hvesp2TotalLifetimeEnergyInput "HVESP2 Total Lifetime Energy Input: The cumulative energy which has flowed into this High Voltage Energy Storage Pack instance over the lifetime of the battery pack. This parameter is the sum of the Energy into this HVES instance. This value is reset...";
CM_ SG_ 2633717758 Hvesp2TotalLifetimeEnergyOutput "HVESP2 Total Lifetime Energy Output: The cumulative energy which has flowed out of this High Voltage Energy Storage Pack instance over the lifetime of the battery pack. This parameter is the sum of the Energy out of this HVES instance. This value is ...";
CM_ SG_ 2633717758 Hvsp2CnttrOpnUndrLdCnt "HVESP2 Contactor Open Under Load Count: This signal represents the number of times the contactors inside this High Voltage Energy Storage Pack instance have opened while current is flowing through them.  The current level (that determines if an openi...";
CM_ BO_ 2566609150 "High Voltage Energy Storage Pack 2 Configuration";
CM_ SG_ 2566609150 Hvesp2NominalVoltage "HVESP2 Nominal Voltage: Per the HVES manufacturer, this is the nominal operating voltage of this High Voltage Energy Storage Pack instance, e.g. '300V' or '600V'.This parameter is for one of multiple packs in an HVESS.  If there is only one pack in t...";
CM_ SG_ 2566609150 Hvesp2CellMaximumVoltageLimit "HVESP2 Cell Maximum Voltage Limit: Per the HVES manufacturer, this is the maximum cell voltage for this High Voltage Energy Storage Pack instance operation.  Operating above this value may damage HVES hardware, or compromise HVES life.This parameter ...";
CM_ SG_ 2566609150 Hvesp2CellMinimumVoltageLimit "HVESP2 Cell Minimum Voltage Limit: Per the HVES manufacturer, this is the minimum cell voltage for this High Voltage Energy Storage Pack instance operation.  Operating below this value may damage HVES hardware, or compromise HVES life.This parameter ...";
CM_ SG_ 2566609150 Hvsp2RmmnddMnmmOprtngVltg "HVESP2 Recommended Minimum Operating Voltage: Per the HVES manufacturer, this is the minimum recommended voltage level for this High Voltage Energy Storage Pack instance operation.  Operating below this value may compromise HVES life.This parameter i...";
CM_ SG_ 2566609150 Hvsp2RmmnddMxmmOprtngVltg "HVESP2 Recommended Maximum Operating Voltage: Per the HVES manufacturer, this is the maximum recommended voltage level for this High Voltage Energy Storage Pack instance operation.  Operating above this value may compromise HVES life.This parameter i...";
CM_ SG_ 2566609150 Hvsp2RmmnddMnmmSttOfChrg "HVESP2 Recommended Minimum State Of Charge: Per the HVES manufacturer, this is the recommended minimum state of charge for this High Voltage Energy Storage Pack instance operation.  Operating below this value may compromise HVES life.This parameter i...";
CM_ SG_ 2566609150 Hvsp2RmmnddMxmmSttOfChrg "HVESP2 Recommended Maximum State Of Charge: Per the HVES manufacturer, this is the recommended maximum state of charge for this High Voltage Energy Storage Pack instance operation.  Operating above this value may compromise HVES life.This parameter i...";
CM_ SG_ 2566609150 Hvsp2RmmnddMxmmOprtngTmprtr "HVESP2 Recommended Maximum Operating Temperature: Per the HVES manufacturer, this is the recommended maximum temperature for this High Voltage Energy Storage Pack instance operation.  Operating above this value may damage HVES hardware, or compromise...";
CM_ SG_ 2566609150 Hvsp2RmmnddMnmmOprtngTmprtr "HVESP2 Recommended Minimum Operating Temperature: Per the HVES manufacturer, this is the recommended minimum temperature for this High Voltage Energy Storage Pack instance operation.  Operating below this value may damage HVES hardware, or compromise...";
CM_ SG_ 2566609150 Hvesp2NominalRatedCapacity "HVESP2 Nominal Rated Capacity: Per the HVES manufacturer, this is the manufacturer's nominal rated capacity of this instance of the energy storage system.  The rated capacity does not change over the life of the HVES.This parameter is for one of mult...";
CM_ BO_ 2633718270 "High Voltage Energy Storage Pack 1 History";
CM_ SG_ 2633718270 Hvesp1StateOfHealth "HVESP1 State of Health: This signal represents the expected remaining Life of this High Voltage Energy Storage Pack instance, in percent.  Battery life is a manufacturer-specific measure of how well the energy storage system is functioning relative t...";
CM_ SG_ 2633718270 Hvesp1TotalEnergyThroughput "HVESP1 Total Energy Throughput: The total energy throughput which has flowed through this High Voltage Energy Storage Pack instance.  This parameter is the sum of the absolute values of the Energy into and out of this HVES instance.  This parameter i...";
CM_ SG_ 2633718270 Hvesp1TotalAccumulatedCharge "HVESP1 Total Accumulated Charge: The total accumulated amp hours which have flowed through this High Voltage Energy Storage Pack instance.  This parameter is the sum of the absolute values of the Ampere hours into and out of this HVES instance.  This...";
CM_ SG_ 2633718270 Hvesp1TotalLifetimeEnergyInput "HVESP1 Total Lifetime Energy Input: The cumulative energy which has flowed into this High Voltage Energy Storage Pack instance over the lifetime of the battery pack. This parameter is the sum of the Energy into this HVES instance. This value is reset...";
CM_ SG_ 2633718270 Hvesp1TotalLifetimeEnergyOutput "HVESP1 Total Lifetime Energy Output: The cumulative energy which has flowed out of this High Voltage Energy Storage Pack instance over the lifetime of the battery pack. This parameter is the sum of the Energy out of this HVES instance. This value is ...";
CM_ SG_ 2633718270 Hvsp1CnttrOpnUndrLdCnt "HVESP1 Contactor Open Under Load Count: This signal represents the number of times the contactors inside this High Voltage Energy Storage Pack instance have opened while current is flowing through them.  The current level (that determines if an openi...";
CM_ BO_ 2566609662 "High Voltage Energy Storage Pack 1 Configuration";
CM_ SG_ 2566609662 Hvesp1NominalVoltage "HVESP1 Nominal Voltage: Per the HVES manufacturer, this is the nominal operating voltage of this High Voltage Energy Storage Pack instance, e.g. '300V' or '600V'.This parameter is for one of multiple packs in an HVESS.  If there is only one pack in t...";
CM_ SG_ 2566609662 Hvesp1CellMaximumVoltageLimit "HVESP1 Cell Maximum Voltage Limit: Per the HVES manufacturer, this is the maximum cell voltage for this High Voltage Energy Storage Pack instance operation.  Operating above this value may damage HVES hardware, or compromise HVES life.This parameter ...";
CM_ SG_ 2566609662 Hvesp1CellMinimumVoltageLimit "HVESP1 Cell Minimum Voltage Limit: Per the HVES manufacturer, this is the minimum cell voltage for this High Voltage Energy Storage Pack instance operation.  Operating below this value may damage HVES hardware, or compromise HVES life.This parameter ...";
CM_ SG_ 2566609662 Hvsp1RmmnddMnmmOprtngVltg "HVESP1 Recommended Minimum Operating Voltage: Per the HVES manufacturer, this is the minimum recommended voltage level for this High Voltage Energy Storage Pack instance operation.  Operating below this value may compromise HVES life.This parameter i...";
CM_ SG_ 2566609662 Hvsp1RmmnddMxmmOprtngVltg "HVESP1 Recommended Maximum Operating Voltage: Per the HVES manufacturer, this is the maximum recommended voltage level for this High Voltage Energy Storage Pack instance operation.  Operating above this value may compromise HVES life.This parameter i...";
CM_ SG_ 2566609662 Hvsp1RmmnddMnmmSttOfChrg "HVESP1 Recommended Minimum State Of Charge: Per the HVES manufacturer, this is the recommended minimum state of charge for this High Voltage Energy Storage Pack instance operation.  Operating below this value may compromise HVES life.This parameter i...";
CM_ SG_ 2566609662 Hvsp1RmmnddMxmmSttOfChrg "HVESP1 Recommended Maximum State Of Charge: Per the HVES manufacturer, this is the recommended maximum state of charge for this High Voltage Energy Storage Pack instance operation.  Operating above this value may compromise HVES life.This parameter i...";
CM_ SG_ 2566609662 Hvsp1RmmnddMxmmOprtngTmprtr "HVESP1 Recommended Maximum Operating Temperature: Per the HVES manufacturer, this is the recommended maximum temperature for this High Voltage Energy Storage Pack instance operation.  Operating above this value may damage HVES hardware, or compromise...";
CM_ SG_ 2566609662 Hvsp1RmmnddMnmmOprtngTmprtr "HVESP1 Recommended Minimum Operating Temperature: Per the HVES manufacturer, this is the recommended minimum temperature for this High Voltage Energy Storage Pack instance operation.  Operating below this value may damage HVES hardware, or compromise...";
CM_ SG_ 2566609662 Hvesp1NominalRatedCapacity "HVESP1 Nominal Rated Capacity: Per the HVES manufacturer, this is the manufacturer's nominal rated capacity of this instance of the energy storage system.  The rated capacity does not change over the life of the HVES.This parameter is for one of mult...";
CM_ BO_ 2633718782 "Vehicle Fire Suppression System Module 1 Detector Data";
CM_ SG_ 2633718782 VfssMdl1Dttr1DttrTp "VFSS Module 1 Detector 1 Detector Type: The type of detector for detector 1 of module 1.0 = Analog thermal sensor1 = Analog gas sensor2 = Analog optical sensor3 = Heat detector4 = Manual release switch5 = SAE Reserved6 = SAE Reserved7 = SAE Reserved8...";
CM_ SG_ 2633718782 VfssMdl1Dttr2DttrTp "VFSS Module 1 Detector 2 Detector Type: The type of detector for detector 2 of module 1.0 = Analog thermal sensor1 = Analog gas sensor2 = Analog optical sensor3 = Heat detector4 = Manual release switch5 = SAE Reserved6 = SAE Reserved7 = SAE Reserved8...";
CM_ SG_ 2633718782 VfssMdl1Dttr3DttrTp "VFSS Module 1 Detector 3 Detector Type: The type of detector for detector 3 of module 1.0 = Analog thermal sensor1 = Analog gas sensor2 = Analog optical sensor3 = Heat detector4 = Manual release switch5 = SAE Reserved6 = SAE Reserved7 = SAE Reserved8...";
CM_ SG_ 2633718782 VfssMdl1Dttr4DttrTp "VFSS Module 1 Detector 4 Detector Type: The type of detector for detector 4 of module 1.0 = Analog thermal sensor1 = Analog gas sensor2 = Analog optical sensor3 = Heat detector4 = Manual release switch5 = SAE Reserved6 = SAE Reserved7 = SAE Reserved8...";
CM_ SG_ 2633718782 VfssMdl1Dttr5DttrTp "VFSS Module 1 Detector 5 Detector Type: The type of detector for detector 5 of module 1.0 = Analog thermal sensor1 = Analog gas sensor2 = Analog optical sensor3 = Heat detector4 = Manual release switch5 = SAE Reserved6 = SAE Reserved7 = SAE Reserved8...";
CM_ SG_ 2633718782 VfssMdl1Dttr6DttrTp "VFSS Module 1 Detector 6 Detector Type: The type of detector for detector 6 of module 1.0 = Analog thermal sensor1 = Analog gas sensor2 = Analog optical sensor3 = Heat detector4 = Manual release switch5 = SAE Reserved6 = SAE Reserved7 = SAE Reserved8...";
CM_ SG_ 2633718782 VfssMdl1Dttr7DttrTp "VFSS Module 1 Detector 7 Detector Type: The type of detector for detector 7 of module 1.0 = Analog thermal sensor1 = Analog gas sensor2 = Analog optical sensor3 = Heat detector4 = Manual release switch5 = SAE Reserved6 = SAE Reserved7 = SAE Reserved8...";
CM_ SG_ 2633718782 VfssMdl1Dttr8DttrTp "VFSS Module 1 Detector 8 Detector Type: The type of detector for detector 8 of module 1.0 = Analog thermal sensor1 = Analog gas sensor2 = Analog optical sensor3 = Heat detector4 = Manual release switch5 = SAE Reserved6 = SAE Reserved7 = SAE Reserved8...";
CM_ SG_ 2633718782 VfssMdl1Dttr1DttrDtSlt "VFSS Module 1 Detector 1 Detector Data SLOT: The SAE SLOT encoding used for data reported in SPN 10847 (VFSS Module 1 Detector 1 Data) for this detector instance of this module.0 = SAEev03 (voltage)1 = SAEpc07 (percent)2 = SAEtp02 (temperature)3 = SA...";
CM_ SG_ 2633718782 VfssMdl1Dttr2DttrDtSlt "VFSS Module 1 Detector 2 Detector Data SLOT: The SAE SLOT encoding used for data reported in SPN 10848 (VFSS Module 1 Detector 2 Data) for this detector instance of this module.0 = SAEev03 (voltage)1 = SAEpc07 (percent)2 = SAEtp02 (temperature)3 = SA...";
CM_ SG_ 2633718782 VfssMdl1Dttr3DttrDtSlt "VFSS Module 1 Detector 3 Detector Data SLOT: The SAE SLOT encoding used for data reported in SPN 10853 (VFSS Module 1 Detector 3 Data) for this detector instance of this module.0 = SAEev03 (voltage)1 = SAEpc07 (percent)2 = SAEtp02 (temperature)3 = SA...";
CM_ SG_ 2633718782 VfssMdl1Dttr4DttrDtSlt "VFSS Module 1 Detector 4 Detector Data SLOT: The SAE SLOT encoding used for data reported in SPN 10856 (VFSS Module 1 Detector 4 Data) for this detector instance of this module.0 = SAEev03 (voltage)1 = SAEpc07 (percent)2 = SAEtp02 (temperature)3 = SA...";
CM_ SG_ 2633718782 VfssMdl1Dttr5DttrDtSlt "VFSS Module 1 Detector 5 Detector Data SLOT: The SAE SLOT encoding used for data reported in SPN 10859 (VFSS Module 1 Detector 5 Data) for this detector instance of this module.0 = SAEev03 (voltage)1 = SAEpc07 (percent)2 = SAEtp02 (temperature)3 = SA...";
CM_ SG_ 2633718782 VfssMdl1Dttr6DttrDtSlt "VFSS Module 1 Detector 6 Detector Data SLOT: The SAE SLOT encoding used for data reported in SPN 10861 (VFSS Module 1 Detector 6 Data) for this detector instance of this module.0 = SAEev03 (voltage)1 = SAEpc07 (percent)2 = SAEtp02 (temperature)3 = SA...";
CM_ SG_ 2633718782 VfssMdl1Dttr7DttrDtSlt "VFSS Module 1 Detector 7 Detector Data SLOT: The SAE SLOT encoding used for data reported in SPN 10865 (VFSS Module 1 Detector 7 Data) for this detector instance of this module.0 = SAEev03 (voltage)1 = SAEpc07 (percent)2 = SAEtp02 (temperature)3 = SA...";
CM_ SG_ 2633718782 VfssMdl1Dttr8DttrDtSlt "VFSS Module 1 Detector 8 Detector Data SLOT: The SAE SLOT encoding used for data reported in SPN 10868 (VFSS Module 1 Detector 8 Data) for this detector instance of this module.0 = SAEev03 (voltage)1 = SAEpc07 (percent)2 = SAEtp02 (temperature)3 = SA...";
CM_ BO_ 2633719038 "Vehicle Fire Suppression System Module 2 Detector Data";
CM_ SG_ 2633719038 VfssMdl2Dttr1DttrTp "VFSS Module 2 Detector 1 Detector Type: The type of detector for detector 1 of module 2.0 = Analog thermal sensor1 = Analog gas sensor2 = Analog optical sensor3 = Heat detector4 = Manual release switch5 = SAE Reserved6 = SAE Reserved7 = SAE Reserved8...";
CM_ SG_ 2633719038 VfssMdl2Dttr2DttrTp "VFSS Module 2 Detector 2 Detector Type: The type of detector for detector 2 of module 2.0 = Analog thermal sensor1 = Analog gas sensor2 = Analog optical sensor3 = Heat detector4 = Manual release switch5 = SAE Reserved6 = SAE Reserved7 = SAE Reserved8...";
CM_ SG_ 2633719038 VfssMdl2Dttr3DttrTp "VFSS Module 2 Detector 3 Detector Type: The type of detector for detector 3 of module 2.0 = Analog thermal sensor1 = Analog gas sensor2 = Analog optical sensor3 = Heat detector4 = Manual release switch5 = SAE Reserved6 = SAE Reserved7 = SAE Reserved8...";
CM_ SG_ 2633719038 VfssMdl2Dttr4DttrTp "VFSS Module 2 Detector 4 Detector Type: The type of detector for detector 4 of module 2.0 = Analog thermal sensor1 = Analog gas sensor2 = Analog optical sensor3 = Heat detector4 = Manual release switch5 = SAE Reserved6 = SAE Reserved7 = SAE Reserved8...";
CM_ SG_ 2633719038 VfssMdl2Dttr5DttrTp "VFSS Module 2 Detector 5 Detector Type: The type of detector for detector 5 of module 2.0 = Analog thermal sensor1 = Analog gas sensor2 = Analog optical sensor3 = Heat detector4 = Manual release switch5 = SAE Reserved6 = SAE Reserved7 = SAE Reserved8...";
CM_ SG_ 2633719038 VfssMdl2Dttr6DttrTp "VFSS Module 2 Detector 6 Detector Type: The type of detector for detector 6 of module 2.0 = Analog thermal sensor1 = Analog gas sensor2 = Analog optical sensor3 = Heat detector4 = Manual release switch5 = SAE Reserved6 = SAE Reserved7 = SAE Reserved8...";
CM_ SG_ 2633719038 VfssMdl2Dttr7DttrTp "VFSS Module 2 Detector 7 Detector Type: The type of detector for detector 7 of module 2.0 = Analog thermal sensor1 = Analog gas sensor2 = Analog optical sensor3 = Heat detector4 = Manual release switch5 = SAE Reserved6 = SAE Reserved7 = SAE Reserved8...";
CM_ SG_ 2633719038 VfssMdl2Dttr8DttrTp "VFSS Module 2 Detector 8 Detector Type: The type of detector for detector 8 of module 2.0 = Analog thermal sensor1 = Analog gas sensor2 = Analog optical sensor3 = Heat detector4 = Manual release switch5 = SAE Reserved6 = SAE Reserved7 = SAE Reserved8...";
CM_ SG_ 2633719038 VfssMdl2Dttr1DttrDtSlt "VFSS Module 2 Detector 1 Detector Data SLOT: The SAE SLOT encoding used for data reported in SPN 10871 (VFSS Module 2 Detector 1 Data) for this detector instance of this module.0 = SAEev03 (voltage)1 = SAEpc07 (percent)2 = SAEtp02 (temperature)3 = SA...";
CM_ SG_ 2633719038 VfssMdl2Dttr2DttrDtSlt "VFSS Module 2 Detector 2 Detector Data SLOT: The SAE SLOT encoding used for data reported in SPN 10871 (VFSS Module 2 Detector 2 Data) for this detector instance of this module.0 = SAEev03 (voltage)1 = SAEpc07 (percent)2 = SAEtp02 (temperature)3 = SA...";
CM_ SG_ 2633719038 VfssMdl2Dttr3DttrDtSlt "VFSS Module 2 Detector 3 Detector Data SLOT: The SAE SLOT encoding used for data reported in SPN 10871 (VFSS Module 2 Detector 3 Data) for this detector instance of this module.0 = SAEev03 (voltage)1 = SAEpc07 (percent)2 = SAEtp02 (temperature)3 = SA...";
CM_ SG_ 2633719038 VfssMdl2Dttr4DttrDtSlt "VFSS Module 2 Detector 4 Detector Data SLOT: The SAE SLOT encoding used for data reported in SPN 10871 (VFSS Module 2 Detector 4 Data) for this detector instance of this module.0 = SAEev03 (voltage)1 = SAEpc07 (percent)2 = SAEtp02 (temperature)3 = SA...";
CM_ SG_ 2633719038 VfssMdl2Dttr5DttrDtSlt "VFSS Module 2 Detector 5 Detector Data SLOT: The SAE SLOT encoding used for data reported in SPN 10871 (VFSS Module 2 Detector 5 Data) for this detector instance of this module.0 = SAEev03 (voltage)1 = SAEpc07 (percent)2 = SAEtp02 (temperature)3 = SA...";
CM_ SG_ 2633719038 VfssMdl2Dttr6DttrDtSlt "VFSS Module 2 Detector 6 Detector Data SLOT: The SAE SLOT encoding used for data reported in SPN 10871 (VFSS Module 2 Detector 6 Data) for this detector instance of this module.0 = SAEev03 (voltage)1 = SAEpc07 (percent)2 = SAEtp02 (temperature)3 = SA...";
CM_ SG_ 2633719038 VfssMdl2Dttr7DttrDtSlt "VFSS Module 2 Detector 7 Detector Data SLOT: The SAE SLOT encoding used for data reported in SPN 10871 (VFSS Module 2 Detector 7 Data) for this detector instance of this module.0 = SAEev03 (voltage)1 = SAEpc07 (percent)2 = SAEtp02 (temperature)3 = SA...";
CM_ SG_ 2633719038 VfssMdl2Dttr8DttrDtSlt "VFSS Module 2 Detector 8 Detector Data SLOT: The SAE SLOT encoding used for data reported in SPN 10871 (VFSS Module 2 Detector 8 Data) for this detector instance of this module.0 = SAEev03 (voltage)1 = SAEpc07 (percent)2 = SAEtp02 (temperature)3 = SA...";
CM_ BO_ 2633719294 "Vehicle Fire Suppression System Module 3 Detector Data";
CM_ SG_ 2633719294 VfssMdl3Dttr1DttrTp "VFSS Module 3 Detector 1 Detector Type: The type of detector for detector 1 of module 3.0 = Analog thermal sensor1 = Analog gas sensor2 = Analog optical sensor3 = Heat detector4 = Manual release switch5 = SAE Reserved6 = SAE Reserved7 = SAE Reserved8...";
CM_ SG_ 2633719294 VfssMdl3Dttr2DttrTp "VFSS Module 3 Detector 2 Detector Type: The type of detector for detector 2 of module 3.0 = Analog thermal sensor1 = Analog gas sensor2 = Analog optical sensor3 = Heat detector4 = Manual release switch5 = SAE Reserved6 = SAE Reserved7 = SAE Reserved8...";
CM_ SG_ 2633719294 VfssMdl3Dttr3DttrTp "VFSS Module 3 Detector 3 Detector Type: The type of detector for detector 3 of module 3.0 = Analog thermal sensor1 = Analog gas sensor2 = Analog optical sensor3 = Heat detector4 = Manual release switch5 = SAE Reserved6 = SAE Reserved7 = SAE Reserved8...";
CM_ SG_ 2633719294 VfssMdl3Dttr4DttrTp "VFSS Module 3 Detector 4 Detector Type: The type of detector for detector 4 of module 3.0 = Analog thermal sensor1 = Analog gas sensor2 = Analog optical sensor3 = Heat detector4 = Manual release switch5 = SAE Reserved6 = SAE Reserved7 = SAE Reserved8...";
CM_ SG_ 2633719294 VfssMdl3Dttr5DttrTp "VFSS Module 3 Detector 5 Detector Type: The type of detector for detector 5 of module 3.0 = Analog thermal sensor1 = Analog gas sensor2 = Analog optical sensor3 = Heat detector4 = Manual release switch5 = SAE Reserved6 = SAE Reserved7 = SAE Reserved8...";
CM_ SG_ 2633719294 VfssMdl3Dttr6DttrTp "VFSS Module 3 Detector 6 Detector Type: The type of detector for detector 6 of module 3.0 = Analog thermal sensor1 = Analog gas sensor2 = Analog optical sensor3 = Heat detector4 = Manual release switch5 = SAE Reserved6 = SAE Reserved7 = SAE Reserved8...";
CM_ SG_ 2633719294 VfssMdl3Dttr7DttrTp "VFSS Module 3 Detector 7 Detector Type: The type of detector for detector 7 of module 3.0 = Analog thermal sensor1 = Analog gas sensor2 = Analog optical sensor3 = Heat detector4 = Manual release switch5 = SAE Reserved6 = SAE Reserved7 = SAE Reserved8...";
CM_ SG_ 2633719294 VfssMdl3Dttr8DttrTp "VFSS Module 3 Detector 8 Detector Type: The type of detector for detector 8 of module 3.0 = Analog thermal sensor1 = Analog gas sensor2 = Analog optical sensor3 = Heat detector4 = Manual release switch5 = SAE Reserved6 = SAE Reserved7 = SAE Reserved8...";
CM_ SG_ 2633719294 VfssMdl3Dttr1DttrDtSlt "VFSS Module 3 Detector 1 Detector Data SLOT: The SAE SLOT encoding used for data reported in SPN 10871 (VFSS Module 3 Detector 1 Data) for this detector instance of this module.0 = SAEev03 (voltage)1 = SAEpc07 (percent)2 = SAEtp02 (temperature)3 = SA...";
CM_ SG_ 2633719294 VfssMdl3Dttr2DttrDtSlt "VFSS Module 3 Detector 2 Detector Data SLOT: The SAE SLOT encoding used for data reported in SPN 10871 (VFSS Module 3 Detector 2 Data) for this detector instance of this module.0 = SAEev03 (voltage)1 = SAEpc07 (percent)2 = SAEtp02 (temperature)3 = SA...";
CM_ SG_ 2633719294 VfssMdl3Dttr3DttrDtSlt "VFSS Module 3 Detector 3 Detector Data SLOT: The SAE SLOT encoding used for data reported in SPN 10871 (VFSS Module 3 Detector 3 Data) for this detector instance of this module.0 = SAEev03 (voltage)1 = SAEpc07 (percent)2 = SAEtp02 (temperature)3 = SA...";
CM_ SG_ 2633719294 VfssMdl3Dttr4DttrDtSlt "VFSS Module 3 Detector 4 Detector Data SLOT: The SAE SLOT encoding used for data reported in SPN 10871 (VFSS Module 3 Detector 4 Data) for this detector instance of this module.0 = SAEev03 (voltage)1 = SAEpc07 (percent)2 = SAEtp02 (temperature)3 = SA...";
CM_ SG_ 2633719294 VfssMdl3Dttr5DttrDtSlt "VFSS Module 3 Detector 5 Detector Data SLOT: The SAE SLOT encoding used for data reported in SPN 10871 (VFSS Module 3 Detector 5 Data) for this detector instance of this module.0 = SAEev03 (voltage)1 = SAEpc07 (percent)2 = SAEtp02 (temperature)3 = SA...";
CM_ SG_ 2633719294 VfssMdl3Dttr6DttrDtSlt "VFSS Module 3 Detector 6 Detector Data SLOT: The SAE SLOT encoding used for data reported in SPN 10871 (VFSS Module 3 Detector 6 Data) for this detector instance of this module.0 = SAEev03 (voltage)1 = SAEpc07 (percent)2 = SAEtp02 (temperature)3 = SA...";
CM_ SG_ 2633719294 VfssMdl3Dttr7DttrDtSlt "VFSS Module 3 Detector 7 Detector Data SLOT: The SAE SLOT encoding used for data reported in SPN 10871 (VFSS Module 3 Detector 7 Data) for this detector instance of this module.0 = SAEev03 (voltage)1 = SAEpc07 (percent)2 = SAEtp02 (temperature)3 = SA...";
CM_ SG_ 2633719294 VfssMdl3Dttr8DttrDtSlt "VFSS Module 3 Detector 8 Detector Data SLOT: The SAE SLOT encoding used for data reported in SPN 10871 (VFSS Module 3 Detector 8 Data) for this detector instance of this module.0 = SAEev03 (voltage)1 = SAEpc07 (percent)2 = SAEtp02 (temperature)3 = SA...";
CM_ BO_ 2633719550 "Vehicle Fire Suppression System Module 4 Detector Data";
CM_ SG_ 2633719550 VfssMdl4Dttr1DttrTp "VFSS Module 4 Detector 1 Detector Type: The type of detector for detector 1 of module 4.0 = Analog thermal sensor1 = Analog gas sensor2 = Analog optical sensor3 = Heat detector4 = Manual release switch5 = SAE Reserved6 = SAE Reserved7 = SAE Reserved8...";
CM_ SG_ 2633719550 VfssMdl4Dttr2DttrTp "VFSS Module 4 Detector 2 Detector Type: The type of detector for detector 2 of module 4.0 = Analog thermal sensor1 = Analog gas sensor2 = Analog optical sensor3 = Heat detector4 = Manual release switch5 = SAE Reserved6 = SAE Reserved7 = SAE Reserved8...";
CM_ SG_ 2633719550 VfssMdl4Dttr3DttrTp "VFSS Module 4 Detector 3 Detector Type: The type of detector for detector 3 of module 4.0 = Analog thermal sensor1 = Analog gas sensor2 = Analog optical sensor3 = Heat detector4 = Manual release switch5 = SAE Reserved6 = SAE Reserved7 = SAE Reserved8...";
CM_ SG_ 2633719550 VfssMdl4Dttr4DttrTp "VFSS Module 4 Detector 4 Detector Type: The type of detector for detector 4 of module 4.0 = Analog thermal sensor1 = Analog gas sensor2 = Analog optical sensor3 = Heat detector4 = Manual release switch5 = SAE Reserved6 = SAE Reserved7 = SAE Reserved8...";
CM_ SG_ 2633719550 VfssMdl4Dttr5DttrTp "VFSS Module 4 Detector 5 Detector Type: The type of detector for detector 5 of module 4.0 = Analog thermal sensor1 = Analog gas sensor2 = Analog optical sensor3 = Heat detector4 = Manual release switch5 = SAE Reserved6 = SAE Reserved7 = SAE Reserved8...";
CM_ SG_ 2633719550 VfssMdl4Dttr6DttrTp "VFSS Module 4 Detector 6 Detector Type: The type of detector for detector 6 of module 4.0 = Analog thermal sensor1 = Analog gas sensor2 = Analog optical sensor3 = Heat detector4 = Manual release switch5 = SAE Reserved6 = SAE Reserved7 = SAE Reserved8...";
CM_ SG_ 2633719550 VfssMdl4Dttr7DttrTp "VFSS Module 4 Detector 7 Detector Type: The type of detector for detector 7 of module 4.0 = Analog thermal sensor1 = Analog gas sensor2 = Analog optical sensor3 = Heat detector4 = Manual release switch5 = SAE Reserved6 = SAE Reserved7 = SAE Reserved8...";
CM_ SG_ 2633719550 VfssMdl4Dttr8DttrTp "VFSS Module 4 Detector 8 Detector Type: The type of detector for detector 8 of module 4.0 = Analog thermal sensor1 = Analog gas sensor2 = Analog optical sensor3 = Heat detector4 = Manual release switch5 = SAE Reserved6 = SAE Reserved7 = SAE Reserved8...";
CM_ SG_ 2633719550 VfssMdl4Dttr1DttrDtSlt "VFSS Module 4 Detector 1 Detector Data SLOT: The SAE SLOT encoding used for data reported in SPN 10871 (VFSS Module 4 Detector 1 Data) for this detector instance of this module.0 = SAEev03 (voltage)1 = SAEpc07 (percent)2 = SAEtp02 (temperature)3 = SA...";
CM_ SG_ 2633719550 VfssMdl4Dttr2DttrDtSlt "VFSS Module 4 Detector 2 Detector Data SLOT: The SAE SLOT encoding used for data reported in SPN 10871 (VFSS Module 4 Detector 2 Data) for this detector instance of this module.0 = SAEev03 (voltage)1 = SAEpc07 (percent)2 = SAEtp02 (temperature)3 = SA...";
CM_ SG_ 2633719550 VfssMdl4Dttr3DttrDtSlt "VFSS Module 4 Detector 3 Detector Data SLOT: The SAE SLOT encoding used for data reported in SPN 10871 (VFSS Module 4 Detector 3 Data) for this detector instance of this module.0 = SAEev03 (voltage)1 = SAEpc07 (percent)2 = SAEtp02 (temperature)3 = SA...";
CM_ SG_ 2633719550 VfssMdl4Dttr4DttrDtSlt "VFSS Module 4 Detector 4 Detector Data SLOT: The SAE SLOT encoding used for data reported in SPN 10871 (VFSS Module 4 Detector 4 Data) for this detector instance of this module.0 = SAEev03 (voltage)1 = SAEpc07 (percent)2 = SAEtp02 (temperature)3 = SA...";
CM_ SG_ 2633719550 VfssMdl4Dttr5DttrDtSlt "VFSS Module 4 Detector 5 Detector Data SLOT: The SAE SLOT encoding used for data reported in SPN 10871 (VFSS Module 4 Detector 5 Data) for this detector instance of this module.0 = SAEev03 (voltage)1 = SAEpc07 (percent)2 = SAEtp02 (temperature)3 = SA...";
CM_ SG_ 2633719550 VfssMdl4Dttr6DttrDtSlt "VFSS Module 4 Detector 6 Detector Data SLOT: The SAE SLOT encoding used for data reported in SPN 10871 (VFSS Module 4 Detector 6 Data) for this detector instance of this module.0 = SAEev03 (voltage)1 = SAEpc07 (percent)2 = SAEtp02 (temperature)3 = SA...";
CM_ SG_ 2633719550 VfssMdl4Dttr7DttrDtSlt "VFSS Module 4 Detector 7 Detector Data SLOT: The SAE SLOT encoding used for data reported in SPN 10871 (VFSS Module 4 Detector 7 Data) for this detector instance of this module.0 = SAEev03 (voltage)1 = SAEpc07 (percent)2 = SAEtp02 (temperature)3 = SA...";
CM_ SG_ 2633719550 VfssMdl4Dttr8DttrDtSlt "VFSS Module 4 Detector 8 Detector Data SLOT: The SAE SLOT encoding used for data reported in SPN 10871 (VFSS Module 4 Detector 8 Data) for this detector instance of this module.0 = SAEev03 (voltage)1 = SAEpc07 (percent)2 = SAEtp02 (temperature)3 = SA...";
CM_ BO_ 2633719806 "Vehicle Fire Suppression System Module 1 Auxiliary Data";
CM_ SG_ 2633719806 VfssModule1HeatZone1Data "VFSS Module 1 Heat Zone 1 Data: Current measured value for heat zone 1 of module 1.";
CM_ SG_ 2633719806 VfssModule1HeatZone2Data "VFSS Module 1 Heat Zone 2 Data: Current measured value for heat zone 2 of module 1.";
CM_ SG_ 2633719806 VfssModule1ReleaseZone1Data "VFSS Module 1 Release Zone 1 Data: Current measured value for release zone 1 of module 1.";
CM_ SG_ 2633719806 VfssModule1ReleaseZone2Data "VFSS Module 1 Release Zone 2 Data: Current measured value for release zone 2 of module 1.";
CM_ SG_ 2633719806 VfssModule1PressureSwitch1Data "VFSS Module 1 Pressure Switch 1 Data: Current measured value for pressure switch 1 of module 1.";
CM_ SG_ 2633719806 VfssModule1PressureSwitch2Data "VFSS Module 1 Pressure Switch 2 Data: Current measured value for pressure switch 2 of module 1.";
CM_ SG_ 2633719806 VfssModule1PrimaryPowerVoltage "VFSS Module 1 Primary Power Voltage: Current measured value for primary power voltage of module 1.";
CM_ SG_ 2633719806 VfssMdl1SndrPwrVltg "VFSS Module 1 Secondary Power Voltage: Current measured value for secondary power voltage of module 1.";
CM_ BO_ 2633720062 "Vehicle Fire Suppression System Module 2 Auxiliary Data";
CM_ SG_ 2633720062 VfssModule2HeatZone1Data "VFSS Module 2 Heat Zone 1 Data: Current measured value for heat zone 1 of module 2.";
CM_ SG_ 2633720062 VfssModule2HeatZone2Data "VFSS Module 2 Heat Zone 2 Data: Current measured value for heat zone 2 of module 2.";
CM_ SG_ 2633720062 VfssModule2ReleaseZone1Data "VFSS Module 2 Release Zone 1 Data: Current measured value for release zone 1 of module 2.";
CM_ SG_ 2633720062 VfssModule2ReleaseZone2Data "VFSS Module 2 Release Zone 2 Data: Current measured value for release zone 2 of module 2.";
CM_ SG_ 2633720062 VfssModule2PressureSwitch1Data "VFSS Module 2 Pressure Switch 1 Data: Current measured value for pressure switch 1 of module 2.";
CM_ SG_ 2633720062 VfssModule2PressureSwitch2Data "VFSS Module 2 Pressure Switch 2 Data: Current measured value for pressure switch 2 of module 2.";
CM_ SG_ 2633720062 VfssModule2PrimaryPowerVoltage "VFSS Module 2 Primary Power Voltage: Current measured value for primary power voltage of module 2.";
CM_ SG_ 2633720062 VfssMdl2SndrPwrVltg "VFSS Module 2 Secondary Power Voltage: Current measured value for secondary power voltage of module 2.";
CM_ BO_ 2633720318 "Vehicle Fire Suppression System Module 3 Auxiliary Data";
CM_ SG_ 2633720318 VfssModule3HeatZone1Data "VFSS Module 3 Heat Zone 1 Data: Current measured value for heat zone 1 of module 3.";
CM_ SG_ 2633720318 VfssModule3HeatZone2Data "VFSS Module 3 Heat Zone 2 Data: Current measured value for heat zone 2 of module 3.";
CM_ SG_ 2633720318 VfssModule3ReleaseZone1Data "VFSS Module 3 Release Zone 1 Data: Current measured value for release zone 1 of module 3.";
CM_ SG_ 2633720318 VfssModule3ReleaseZone2Data "VFSS Module 3 Release Zone 2 Data: Current measured value for release zone 2 of module 3.";
CM_ SG_ 2633720318 VfssModule3PressureSwitch1Data "VFSS Module 3 Pressure Switch 1 Data: Current measured value for pressure switch 1 of module 3.";
CM_ SG_ 2633720318 VfssModule3PressureSwitch2Data "VFSS Module 3 Pressure Switch 2 Data: Current measured value for pressure switch 2 of module 3.";
CM_ SG_ 2633720318 VfssModule3PrimaryPowerVoltage "VFSS Module 3 Primary Power Voltage: Current measured value for primary power voltage of module 3.";
CM_ SG_ 2633720318 VfssMdl3SndrPwrVltg "VFSS Module 3 Secondary Power Voltage: Current measured value for secondary power voltage of module 3.";
CM_ BO_ 2633720574 "Vehicle Fire Suppression System Module 4 Auxiliary Data";
CM_ SG_ 2633720574 VfssModule4HeatZone1Data "VFSS Module 4 Heat Zone 1 Data: Current measured value for heat zone 1 of module 4.";
CM_ SG_ 2633720574 VfssModule4HeatZone2Data "VFSS Module 4 Heat Zone 2 Data: Current measured value for heat zone 2 of module 4.";
CM_ SG_ 2633720574 VfssModule4ReleaseZone1Data "VFSS Module 4 Release Zone 1 Data: Current measured value for release zone 1 of module 4.";
CM_ SG_ 2633720574 VfssModule4ReleaseZone2Data "VFSS Module 4 Release Zone 2 Data: Current measured value for release zone 2 of module 4.";
CM_ SG_ 2633720574 VfssModule4PressureSwitch1Data "VFSS Module 4 Pressure Switch 1 Data: Current measured value for pressure switch 1 of module 4.";
CM_ SG_ 2633720574 VfssModule4PressureSwitch2Data "VFSS Module 4 Pressure Switch 2 Data: Current measured value for pressure switch 2 of module 4.";
CM_ SG_ 2633720574 VfssModule4PrimaryPowerVoltage "VFSS Module 4 Primary Power Voltage: Current measured value for primary power voltage of module 4.";
CM_ SG_ 2633720574 VfssMdl4SndrPwrVltg "VFSS Module 4 Secondary Power Voltage: Current measured value for secondary power voltage of module 4.";
CM_ BO_ 2633720830 "Vehicle Fire Suppression System Module 1 Names";
CM_ SG_ 2633720830 VfssModule1Name "VFSS Module 1 Name: Descriptive name for the VFSS module/zone 1.";
CM_ SG_ 2633720830 VfssModule1DetectorZone1Name "VFSS Module 1 Detector Zone 1 Name: Descriptive name for detector zone 1 of module 1.";
CM_ SG_ 2633720830 VfssModule1DetectorZone2Name "VFSS Module 1 Detector Zone 2 Name: Descriptive name for detector zone 2 of module 1.";
CM_ SG_ 2633720830 VfssModule1DetectorZone3Name "VFSS Module 1 Detector Zone 3 Name: Descriptive name for detector zone 3 of module 1.";
CM_ SG_ 2633720830 VfssModule1DetectorZone4Name "VFSS Module 1 Detector Zone 4 Name: Descriptive name for detector zone 4 of module 1.";
CM_ SG_ 2633720830 VfssModule1DetectorZone5Name "VFSS Module 1 Detector Zone 5 Name: Descriptive name for detector zone 5 of module 1.";
CM_ SG_ 2633720830 VfssModule1DetectorZone6Name "VFSS Module 1 Detector Zone 6 Name: Descriptive name for detector zone 6 of module 1.";
CM_ SG_ 2633720830 VfssModule1DetectorZone7Name "VFSS Module 1 Detector Zone 7 Name: Descriptive name for detector zone 7 of module 1.";
CM_ SG_ 2633720830 VfssModule1DetectorZone8Name "VFSS Module 1 Detector Zone 8 Name: Descriptive name for detector zone 8 of module 1.";
CM_ SG_ 2633720830 VfssModule1HeatZone1Name "VFSS Module 1 Heat Zone 1 Name: Descriptive name for heat zone 1 of module 1.";
CM_ SG_ 2633720830 VfssModule1HeatZone2Name "VFSS Module 1 Heat Zone 2 Name: Descriptive name for heat zone 2 of module 1.";
CM_ SG_ 2633720830 VfssModule1ReleaseZone1Name "VFSS Module 1 Release Zone 1 Name: Descriptive name for release zone 1 of module 1.";
CM_ SG_ 2633720830 VfssModule1ReleaseZone2Name "VFSS Module 1 Release Zone 2 Name: Descriptive name for release zone 2 of module 1.";
CM_ BO_ 2633721086 "Vehicle Fire Suppression System Module 2 Names";
CM_ SG_ 2633721086 VfssModule2Name "VFSS Module 2 Name: Descriptive name for the VFSS module/zone 2.";
CM_ SG_ 2633721086 VfssModule2DetectorZone1Name "VFSS Module 2 Detector Zone 1 Name: Descriptive name for detector zone 1 of module 2.";
CM_ SG_ 2633721086 VfssModule2DetectorZone2Name "VFSS Module 2 Detector Zone 2 Name: Descriptive name for detector zone 2 of module 2.";
CM_ SG_ 2633721086 VfssModule2DetectorZone3Name "VFSS Module 2 Detector Zone 3 Name: Descriptive name for detector zone 3 of module 2.";
CM_ SG_ 2633721086 VfssModule2DetectorZone4Name "VFSS Module 2 Detector Zone 4 Name: Descriptive name for detector zone 4 of module 2.";
CM_ SG_ 2633721086 VfssModule2DetectorZone5Name "VFSS Module 2 Detector Zone 5 Name: Descriptive name for detector zone 5 of module 2.";
CM_ SG_ 2633721086 VfssModule2DetectorZone6Name "VFSS Module 2 Detector Zone 6 Name: Descriptive name for detector zone 6 of module 2.";
CM_ SG_ 2633721086 VfssModule2DetectorZone7Name "VFSS Module 2 Detector Zone 7 Name: Descriptive name for detector zone 7 of module 2.";
CM_ SG_ 2633721086 VfssModule2DetectorZone8Name "VFSS Module 2 Detector Zone 8 Name: Descriptive name for detector zone 8 of module 2.";
CM_ SG_ 2633721086 VfssModule2HeatZone1Name "VFSS Module 2 Heat Zone 1 Name: Descriptive name for heat zone 1 of module 2.";
CM_ SG_ 2633721086 VfssModule2HeatZone2Name "VFSS Module 2 Heat Zone 2 Name: Descriptive name for heat zone 2 of module 2.";
CM_ SG_ 2633721086 VfssModule2ReleaseZone1Name "VFSS Module 2 Release Zone 1 Name: Descriptive name for release zone 1 of module 2.";
CM_ SG_ 2633721086 VfssModule2ReleaseZone2Name "VFSS Module 2 Release Zone 2 Name: Descriptive name for release zone 2 of module 2.";
CM_ BO_ 2633721342 "Vehicle Fire Suppression System Module 3 Names";
CM_ SG_ 2633721342 VfssModule3Name "VFSS Module 3 Name: Descriptive name for the VFSS module/zone 3.";
CM_ SG_ 2633721342 VfssModule3DetectorZone1Name "VFSS Module 3 Detector Zone 1 Name: Descriptive name for detector zone 1 of module 3.";
CM_ SG_ 2633721342 VfssModule3DetectorZone2Name "VFSS Module 3 Detector Zone 2 Name: Descriptive name for detector zone 2 of module 3.";
CM_ SG_ 2633721342 VfssModule3DetectorZone3Name "VFSS Module 3 Detector Zone 3 Name: Descriptive name for detector zone 3 of module 3.";
CM_ SG_ 2633721342 VfssModule3DetectorZone4Name "VFSS Module 3 Detector Zone 4 Name: Descriptive name for detector zone 4 of module 3.";
CM_ SG_ 2633721342 VfssModule3DetectorZone5Name "VFSS Module 3 Detector Zone 5 Name: Descriptive name for detector zone 5 of module 3.";
CM_ SG_ 2633721342 VfssModule3DetectorZone6Name "VFSS Module 3 Detector Zone 6 Name: Descriptive name for detector zone 6 of module 3.";
CM_ SG_ 2633721342 VfssModule3DetectorZone7Name "VFSS Module 3 Detector Zone 7 Name: Descriptive name for detector zone 7 of module 3.";
CM_ SG_ 2633721342 VfssModule3DetectorZone8Name "VFSS Module 3 Detector Zone 8 Name: Descriptive name for detector zone 8 of module 3.";
CM_ SG_ 2633721342 VfssModule3HeatZone1Name "VFSS Module 3 Heat Zone 1 Name: Descriptive name for heat zone 1 of module 3.";
CM_ SG_ 2633721342 VfssModule3HeatZone2Name "VFSS Module 3 Heat Zone 2 Name: Descriptive name for heat zone 2 of module 3.";
CM_ SG_ 2633721342 VfssModule3ReleaseZone1Name "VFSS Module 3 Release Zone 1 Name: Descriptive name for release zone 1 of module 3.";
CM_ SG_ 2633721342 VfssModule3ReleaseZone2Name "VFSS Module 3 Release Zone 2 Name: Descriptive name for release zone 2 of module 3.";
CM_ BO_ 2633721598 "Vehicle Fire Suppression System Module 4 Names";
CM_ SG_ 2633721598 VfssModule4Name "VFSS Module 4 Name: Descriptive name for the VFSS module/zone 4.";
CM_ SG_ 2633721598 VfssModule4DetectorZone1Name "VFSS Module 4 Detector Zone 1 Name: Descriptive name for detector zone 1 of module 4.";
CM_ SG_ 2633721598 VfssModule4DetectorZone2Name "VFSS Module 4 Detector Zone 2 Name: Descriptive name for detector zone 2 of module 4.";
CM_ SG_ 2633721598 VfssModule4DetectorZone3Name "VFSS Module 4 Detector Zone 3 Name: Descriptive name for detector zone 3 of module 4.";
CM_ SG_ 2633721598 VfssModule4DetectorZone4Name "VFSS Module 4 Detector Zone 4 Name: Descriptive name for detector zone 4 of module 4.";
CM_ SG_ 2633721598 VfssModule4DetectorZone5Name "VFSS Module 4 Detector Zone 5 Name: Descriptive name for detector zone 5 of module 4.";
CM_ SG_ 2633721598 VfssModule4DetectorZone6Name "VFSS Module 4 Detector Zone 6 Name: Descriptive name for detector zone 6 of module 4.";
CM_ SG_ 2633721598 VfssModule4DetectorZone7Name "VFSS Module 4 Detector Zone 7 Name: Descriptive name for detector zone 7 of module 4.";
CM_ SG_ 2633721598 VfssModule4DetectorZone8Name "VFSS Module 4 Detector Zone 8 Name: Descriptive name for detector zone 8 of module 4.";
CM_ SG_ 2633721598 VfssModule4HeatZone1Name "VFSS Module 4 Heat Zone 1 Name: Descriptive name for heat zone 1 of module 4.";
CM_ SG_ 2633721598 VfssModule4HeatZone2Name "VFSS Module 4 Heat Zone 2 Name: Descriptive name for heat zone 2 of module 4.";
CM_ SG_ 2633721598 VfssModule4ReleaseZone1Name "VFSS Module 4 Release Zone 1 Name: Descriptive name for release zone 1 of module 4.";
CM_ SG_ 2633721598 VfssModule4ReleaseZone2Name "VFSS Module 4 Release Zone 2 Name: Descriptive name for release zone 2 of module 4.";
CM_ BO_ 2566612990 "Motor/Generator 2 Inverter Active Power Limits";
CM_ SG_ 2566612990 MtGt2IvtPwLtdDTUddRs "Motor/Generator 2 Inverter Power Limited due to Undefined Reason: Output power is being limited due to an undefined reason.00b = No power limit for this reason01b = Power limited for this reason10b = Error11b = Not Available";
CM_ SG_ 2566612990 MtGt2IvtPwLtdDTMPwMx "Motor/Generator 2 Inverter Power Limited due to Mechanical Power Maximum: Output power is being limited due to Mechanical Power (product of SPN 9062 [Torque] and SPN 9058 [Speed]) approaching or exceeding the SPN 10250 [Inverter Limits Active Mechani...";
CM_ SG_ 2566612990 MtGt2IvtPwLtdDTMPwM "Motor/Generator 2 Inverter Power Limited due to Mechanical Power Minimum: Output power is being limited due to Mechanical Power (product of SPN 9062 [Torque] and SPN 9058 [Speed]) approaching or falling below the SPN 10251 [Inverter Limits Active Mec...";
CM_ SG_ 2566612990 MtrGnrtr2InvrtrPwrLmtdDTTrqMxmm "Motor/Generator 2 Inverter Power Limited due to Torque Maximum: Output power is being limited due to SPN 9062 [Torque] approaching or exceeding the SPN 10262 [Inverter Limits Active Torque Maximum].00b = No power limit for this reason01b = Power limi...";
CM_ SG_ 2566612990 MtrGnrtr2InvrtrPwrLmtdDTTrqMnmm "Motor/Generator 2 Inverter Power Limited due to Torque Minimum: Output power is being limited due to SPN 9062 [Torque] approaching or falling below the SPN 10263 [Inverter Limits Active Torque Minimum].00b = No power limit for this reason01b = Power ...";
CM_ SG_ 2566612990 MtrGnrtr2InvrtrPwrLmtdDTSpdMxmm "Motor/Generator 2 Inverter Power Limited due to Speed Maximum: Output power is being limited due to SPN 9058 [Speed] approaching or exceeding the SPN 10264 [Inverter Limits Active Speed Maximum].00b = No power limit for this reason01b = Power limited...";
CM_ SG_ 2566612990 MtrGnrtr2InvrtrPwrLmtdDTSpdMnmm "Motor/Generator 2 Inverter Power Limited due to Speed Minimum: Output power is being limited due to SPN 9058 [Speed] approaching or falling below the SPN 10265 [Inverter Limits Active Speed Minimum].00b = No power limit for this reason01b = Power lim...";
CM_ SG_ 2566612990 MtGt2IvtPwLtdDTIvtTpt "Motor/Generator 2 Inverter Power Limited due to Inverter Temperature: Output power is being limited due to one or more inverter temperature(s), see SPNs 10282 through 10285 [Inverter Temperature 1-4] approaching or exceeding internally defined limit(...";
CM_ SG_ 2566612990 MtGt2IvtPwLtdDTMtTpt "Motor/Generator 2 Inverter Power Limited due to Motor Temperature: Output power is being limited due to one or more motor temperature(s), see SPNs 9060 and 10286 through 10288 [Motor Temperature 1-4] approaching or exceeding internally defined limit(...";
CM_ SG_ 2566612990 MtGt2IvtPwLtdDTFtCdt "Motor/Generator 2 Inverter Power Limited Due to Fault Condition: Output power is being limited due to an fault condition that requires a torque limitation to prevent further damage (e.g. 'limp home mode').  For example, this could be in case of tempe...";
CM_ SG_ 2566612990 MtGt2IvtPwLtdDTAtvTqRtLt "Motor/Generator 2 Inverter Power Limited Due to Active Torque Rate Limit: Output power is being limited due to exceeding internally defined torque rate limit(s) or SPN 10835 [Inverter Rate Limits Request Absolute Torque Rate Limit].00b = No power lim...";
CM_ SG_ 2566612990 MtGt2IvtPwLtdDTAtvSpdRtLt "Motor/Generator 2 Inverter Power Limited Due to Active Speed Rate Limit: Output power is being limited due to exceeding internally defined speed rate limit(s) or SPN 10834 [Inverter Rate Limits Request Absolute Speed Rate Limit].00b = No power limit ...";
CM_ SG_ 2566612990 MtGt2IvtTqLtdDTMCtsts "Motor/Generator 2 Inverter Torque Limited Due to Machine Characteristics: Output torque is being limited due to SPN 9062 [Torque] approaching or exceeding a motor design characteristic.  For example, for permanent magnet machines, this would be in th...";
CM_ SG_ 2566612990 MtGt2IvtPwLtdDTDSdCtMx "Motor/Generator 2 Inverter Power Limited due to DC Side Current Maximum: Output power is being limited due to SPN 10241 [Inverter DC Side Current] approaching or exceeding the SPN 10280 [Inverter Limits Active DC Side Current Maximum].00b = No power ...";
CM_ SG_ 2566612990 MtGt2IvtPwLtdDTDSdCtM "Motor/Generator 2 Inverter Power Limited due to DC Side Current Minimum: Output power is being limited due to SPN 10241 [Inverter DC Side Current] approaching or falling below the SPN 10281 [Inverter Limits Active DC Side Current Minimum].00b = No po...";
CM_ SG_ 2566612990 MtGt2IvtPwLtdDTDSdVtMx "Motor/Generator 2 Inverter Power Limited due to DC Side Voltage Maximum: Output power is being limited due to SPN 9102 [Inverter DC Side Voltage] approaching or exceeding the SPN 10278 [Inverter Limits Active DC Side Voltage Maximum].00b = No power l...";
CM_ SG_ 2566612990 MtGt2IvtPwLtdDTDSdVtM "Motor/Generator 2 Inverter Power Limited due to DC Side Voltage Minimum: Output power is being limited due to SPN 9102 [Inverter DC Side Voltage] approaching or falling below the SPN 10279 [Inverter Limits Active DC Side Voltage Minimum].00b = No pow...";
CM_ SG_ 2566612990 MtGt2IvtPwLtdDTDSdPwMx "Motor/Generator 2 Inverter Power Limited due to DC Side Power Maximum: Output power is being limited due to DC Side Power (product of SPN 10241 [Inverter DC Side Current] and SPN 9102 [Inverter DC Side Voltage]) approaching or exceeding the SPN 10252...";
CM_ SG_ 2566612990 MtGt2IvtPwLtdDTDSdPwM "Motor/Generator 2 Inverter Power Limited due to DC Side Power Minimum: Output power is being limited due to DC Side Power (product of SPN 10241 [Inverter DC Side Current] and SPN 9102 [Inverter DC Side Voltage]) approaching or falling below the SPN 1...";
CM_ BO_ 2566613246 "Motor/Generator 2 Inverter Isolation Integrity";
CM_ SG_ 2566613246 MtrGnrtr2InvrtrIsltnIntgrtCntr "Motor/Generator 2 Inverter Isolation Integrity Counter: The message counter is used to detect situations where the transmitting ECU malfunction repeats the same frame all the time. The receiver of the information may use the counter parameter to dete...";
CM_ SG_ 2566613246 MtGt2IvtHVtBsAtvIstTstStts "Motor/Generator 2 Inverter High-Voltage Bus Active Isolation Test Status: Status of the high-voltage bus electrical active isolation test as performed by this instance of the motor/generator.0000b = No test requested / No test in process0001b = Test ...";
CM_ SG_ 2566613246 MtGt2IvtHVtBsPssvIstTstStts "Motor/Generator 2 Inverter High-Voltage Bus Passive Isolation Test Status: Status of the high-voltage bus electrical passive isolation test as performed by this instance of the Motor/Generator.0000b = No test requested / No test in process0001b = Tes...";
CM_ SG_ 2566613246 MtGt2IvtHVtBsAtvIstTstRsts "Motor/Generator 2 Inverter High-Voltage Bus Active Isolation Test Results: The isolation resistance that resulted from the High-Voltage Bus Active Isolation Test.See SPN 10813 [High-Voltage Bus Active Isolation Test Status] for test status and SPN 10...";
CM_ SG_ 2566613246 MtGt2IvtHVtBsPssvIstTstRsts "Motor/Generator 2 Inverter High-Voltage Bus Passive Isolation Test Results: The isolation resistance that resulted from the High-Voltage Bus Passive Isolation Test.See SPN 10814 [High-Voltage Bus Passive Isolation Test Status] for test status and SPN...";
CM_ SG_ 2566613246 MtrGnrtr2InvrtrIsltnIntgrtCr "Motor/Generator 2 Inverter Isolation Integrity CRC: The CRC is defined as follows: - Length: 8 bits- Polynomial: x^8+x^5+x^3+x^2+x+1- Initial Value: FFh- Input Data Reflection: Not reflected- Result Data Reflection: Not reflected- XOR value: FFh SAE ...";
CM_ SG_ 2566613246 MtGt2IvtDSdNtvTCsssGdVt "Motor/Generator 2 Inverter DC Side Negative to Chassis Ground Voltage: The voltage level of the high voltage DC side, as measured by the inverter between the negative side of the High Voltage DC Side input and the chassis of the inverter enclosure.  ...";
CM_ BO_ 2566613502 "Motor/Generator 1 Inverter Active Power Limits";
CM_ SG_ 2566613502 MtGt1IvtPwLtdDTUddRs "Motor/Generator 1 Inverter Power Limited due to Undefined Reason: Output power is being limited due to an undefined reason.00b = No power limit for this reason01b = Power limited for this reason10b = Error11b = Not Available";
CM_ SG_ 2566613502 MtGt1IvtPwLtdDTMPwMx "Motor/Generator 1 Inverter Power Limited due to Mechanical Power Maximum: Output power is being limited due to Mechanical Power (product of SPN 9061 [Torque] and SPN 9057 [Speed]) approaching or exceeding the SPN 10184 [Inverter Limits Active Mechani...";
CM_ SG_ 2566613502 MtGt1IvtPwLtdDTMPwM "Motor/Generator 1 Inverter Power Limited due to Mechanical Power Minimum: Output power is being limited due to Mechanical Power (product of SPN 9061 [Torque] and SPN 9057 [Speed]) approaching or falling below the SPN 10185 [Inverter Limits Active Mec...";
CM_ SG_ 2566613502 MtrGnrtr1InvrtrPwrLmtdDTTrqMxmm "Motor/Generator 1 Inverter Power Limited due to Torque Maximum: Output power is being limited due to SPN 9061 [Torque] approaching or exceeding the SPN 10196 [Inverter Limits Active Torque Maximum].00b = No power limit for this reason01b = Power limi...";
CM_ SG_ 2566613502 MtrGnrtr1InvrtrPwrLmtdDTTrqMnmm "Motor/Generator 1 Inverter Power Limited due to Torque Minimum: Output power is being limited due to SPN 9061 [Torque] approaching or falling below the SPN 10197 [Inverter Limits Active Torque Minimum].00b = No power limit for this reason01b = Power ...";
CM_ SG_ 2566613502 MtrGnrtr1InvrtrPwrLmtdDTSpdMxmm "Motor/Generator 1 Inverter Power Limited due to Speed Maximum: Output power is being limited due to SPN 9057 [Speed] approaching or exceeding the SPN 10198 [Inverter Limits Active Speed Maximum].00b = No power limit for this reason01b = Power limited...";
CM_ SG_ 2566613502 MtrGnrtr1InvrtrPwrLmtdDTSpdMnmm "Motor/Generator 1 Inverter Power Limited due to Speed Minimum: Output power is being limited due to SPN 9057 [Speed] approaching or falling below the SPN 10199 [Inverter Limits Active Speed Minimum].00b = No power limit for this reason01b = Power lim...";
CM_ SG_ 2566613502 MtGt1IvtPwLtdDTIvtTpt "Motor/Generator 1 Inverter Power Limited due to Inverter Temperature: Output power is being limited due to one or more inverter temperature(s), see SPNs 10216 through 10219 [Inverter Temperature 1-4] approaching or exceeding internally defined limit(...";
CM_ SG_ 2566613502 MtGt1IvtPwLtdDTMtTpt "Motor/Generator 1 Inverter Power Limited due to Motor Temperature: Output power is being limited due to one or more motor temperature(s), see SPNs 9059 and 10220 through 10222 [Motor Temperature 1-4] approaching or exceeding internally defined limit(...";
CM_ SG_ 2566613502 MtGt1IvtPwLtdDTFtCdt "Motor/Generator 1 Inverter Power Limited Due to Fault Condition: Output power is being limited due to an fault condition that requires a torque limitation to prevent further damage (e.g. 'limp home mode').  For example, this could be in case of tempe...";
CM_ SG_ 2566613502 MtGt1IvtPwLtdDTAtvTqRtLt "Motor/Generator 1 Inverter Power Limited Due to Active Torque Rate Limit: Output power is being limited due to exceeding internally defined torque rate limit(s) or SPN 10797 [Inverter Rate Limits Request Absolute Torque Rate Limit]. 00b = No power li...";
CM_ SG_ 2566613502 MtGt1IvtPwLtdDTAtvSpdRtLt "Motor/Generator 1 Inverter Power Limited Due to Active Speed Rate Limit: Output power is being limited due to exceeding internally defined speed rate limit(s) or SPN 10796 [Inverter Rate Limits Request Absolute Speed Rate Limit].00b = No power limit ...";
CM_ SG_ 2566613502 MtGt1IvtTqLtdDTMCtsts "Motor/Generator 1 Inverter Torque Limited Due to Machine Characteristics: Output torque is being limited due to SPN 9061 [Torque] approaching or exceeding a motor design characteristic.  For example, for permanent magnet machines, this would be in th...";
CM_ SG_ 2566613502 MtGt1IvtPwLtdDTDSdCtMx "Motor/Generator 1 Inverter Power Limited due to DC Side Current Maximum: Output power is being limited due to SPN 10175 [Inverter DC Side Current] approaching or exceeding the SPN 10214 [Inverter Limits Active DC Side Current Maximum].00b = No power ...";
CM_ SG_ 2566613502 MtGt1IvtPwLtdDTDSdCtM "Motor/Generator 1 Inverter Power Limited due to DC Side Current Minimum: Output power is being limited due to SPN 10175 [Inverter DC Side Current] approaching or falling below the SPN 10215 [Inverter Limits Active DC Side Current Minimum].00b = No po...";
CM_ SG_ 2566613502 MtGt1IvtPwLtdDTDSdVtMx "Motor/Generator 1 Inverter Power Limited due to DC Side Voltage Maximum: Output power is being limited due to SPN 9101 [Inverter DC Side Voltage] approaching or exceeding the SPN 10212 [Inverter Limits Active DC Side Voltage Maximum].00b = No power l...";
CM_ SG_ 2566613502 MtGt1IvtPwLtdDTDSdVtM "Motor/Generator 1 Inverter Power Limited due to DC Side Voltage Minimum: Output power is being limited due to SPN 9101 [Inverter DC Side Voltage] approaching or falling below the SPN 10213 [Inverter Limits Active DC Side Voltage Minimum].00b = No pow...";
CM_ SG_ 2566613502 MtGt1IvtPwLtdDTDSdPwMx "Motor/Generator 1 Inverter Power Limited due to DC Side Power Maximum: Output power is being limited due to DC Side Power (product of SPN 10175 [Inverter DC Side Current] and SPN 9101 [Inverter DC Side Voltage]) approaching or exceeding the SPN 10186...";
CM_ SG_ 2566613502 MtGt1IvtPwLtdDTDSdPwM "Motor/Generator 1 Inverter Power Limited due to DC Side Power Minimum: Output power is being limited due to DC Side Power (product of SPN 10175 [Inverter DC Side Current] and SPN 9101 [Inverter DC Side Voltage]) approaching or falling below the SPN 1...";
CM_ BO_ 2566613758 "Motor/Generator 1 Inverter Isolation Integrity";
CM_ SG_ 2566613758 MtrGnrtr1InvrtrIsltnIntgrtCntr "Motor/Generator 1 Inverter Isolation Integrity Counter: The message counter is used to detect situations where the transmitting ECU malfunction repeats the same frame all the time. The receiver of the information may use the counter parameter to dete...";
CM_ SG_ 2566613758 MtGt1IvtHVtBsAtvIstTstStts "Motor/Generator 1 Inverter High-Voltage Bus Active Isolation Test Status: Status of the high-voltage bus electrical active isolation test as performed by this instance of the Motor/Generator.0000b = No test requested / No test in process0001b = Test ...";
CM_ SG_ 2566613758 MtGt1IvtHVtBsPssvIstTstStts "Motor/Generator 1 Inverter High-Voltage Bus Passive Isolation Test Status: Status of the high-voltage bus electrical passive isolation test as performed by this instance of the Motor/Generator.0000b = No test requested / No test in process0001b = Tes...";
CM_ SG_ 2566613758 MtGt1IvtHVtBsAtvIstTstRsts "Motor/Generator 1 Inverter High-Voltage Bus Active Isolation Test Results: The isolation resistance that resulted from the High-Voltage Bus Active Isolation Test.See SPN 10775 [High-Voltage Bus Active Isolation Test Status] for test status and SPN 10...";
CM_ SG_ 2566613758 MtGt1IvtHVtBsPssvIstTstRsts "Motor/Generator 1 Inverter High-Voltage Bus Passive Isolation Test Results: The isolation resistance that resulted from the High-Voltage Bus Passive Isolation Test.See SPN 10776 [High-Voltage Bus Passive Isolation Test Status] for test status and SPN...";
CM_ SG_ 2566613758 MtrGnrtr1InvrtrIsltnIntgrtCr "Motor/Generator 1 Inverter Isolation Integrity CRC: The CRC is defined as follows: - Length: 8 bits- Polynomial: x^8+x^5+x^3+x^2+x+1- Initial Value: FFh- Input Data Reflection: Not reflected- Result Data Reflection: Not reflected- XOR value: FFh SAE ...";
CM_ SG_ 2566613758 MtGt1IvtDSdNtvTCsssGdVt "Motor/Generator 1 Inverter DC Side Negative to Chassis Ground Voltage: The voltage level of the high voltage DC side, as measured by the inverter between the negative side of the High Voltage DC Side input and the chassis of the inverter enclosure.  ...";
CM_ BO_ 2566614014 "High Voltage Bus Information";
CM_ SG_ 2566614014 HighVoltageDcBusAvailability "High Voltage DC Bus Availability: This parameter indicates the availability of the high voltage bus to power components.  Power sources may include, but are not limited to batteries, fuel cells, generators, etc.  Note:  For batteries, SPN 8413 exists...";
CM_ SG_ 2566614014 HghVltgBsDrvlnAvllt "High Voltage Bus Driveline Availability: This parameter indicates the availability of the high voltage bus to driveline components.  Components may include, but are not limited to motor/generator inverters.0000b = High voltage DC bus is not connected...";
CM_ SG_ 2566614014 HghVltgBsAxlrsAvllt "High Voltage Bus Auxiliaries Availability: This parameter indicates the availability of the high voltage bus to auxiliary components.0000b = High voltage DC bus is not connected.0001b = High voltage DC bus is connected.0010b = High voltage DC bus con...";
CM_ SG_ 2566614014 HighVoltageBusEptoAvailability "High Voltage Bus ePTO Availability: This parameter indicates the availability of the high voltage bus to electric power take off components.0000b = High voltage DC bus is not connected.0001b = High voltage DC bus is connected.0010b = High voltage DC ...";
CM_ SG_ 2566614014 HghVltgBsOnBrdChrgrAvllt "High Voltage Bus On-Board Charger Availability: This parameter indicates the availability of the high voltage bus to on-board charging components.0000b = High voltage DC bus is not connected.0001b = High voltage DC bus is connected.0010b = High volta...";
CM_ SG_ 2566614014 HghVltgBsOffBrdChrgrAvllt "High Voltage Bus Off-Board Charger Availability: This parameter indicates the availability of the high voltage bus to off-board charging components or supporting on-vehicle contactors.   See SPN 13181 Hybrid or EV DC Inlet Contactor 1 State for conta...";
CM_ BO_ 2352021246 "High Voltage Energy Storage Pack 7 Control 1";
CM_ SG_ 2352021246 Hvesp7PowerDownCommand "HVESP7 Power-Down Command: Command to shut down this High Voltage Energy Storage Pack instance.  A normal power-down may involve steps that take some period of time (tests, writing of data, etc.).  However, an emergency power-down should shut down th...";
CM_ SG_ 2352021246 Hvesp7CellBalancingCommand "HVESP7 Cell Balancing Command: Command for this High Voltage Energy Storage Pack instance to perform cell balancing.This parameter is for one of multiple packs in an HVESS.  If there is only one pack in the system, the HVESS parameters should be used...";
CM_ SG_ 2352021246 Hvesp7OperationConsent "HVESP7 Operation Consent: This parameter provides an indication to this High Voltage Energy Storage Pack instance that an external device is ready for this HVES instance to proceed with normal operation.  In applications which support this parameter,...";
CM_ SG_ 2352021246 Hvesp7Control1Counter "HVESP7 Control 1 Counter: The message counter is used to detect situations where the transmitting ECU malfunction repeats the same frame all the time. The receiver of the information may use the counter parameter to detect this situation. The transmi...";
CM_ SG_ 2352021246 Hvesp7Control1Crc "HVESP7 Control 1 CRC: The CRC is defined as follows: - Length: 8 bits- Polynomial: x^8+x^5+x^3+x^2+x+1- Initial Value: FFh- Input Data Reflection: Not reflected- Result Data Reflection: Not reflected- XOR value: FFh SAE makes no claim of the function...";
CM_ SG_ 2352021246 Hvsp7HghVltgBsCnntCmmnd "HVESP7 High-Voltage Bus Connect Command: Command to connect this High Voltage Energy Storage Pack instance to the high-voltage bus.  The emergency contactor closure request may be used in situations where one or more faults in the hybrid or EV powert...";
CM_ SG_ 2352021246 Hvsp7HghVltgBsAtvIsltnTstCmmnd "HVESP7 High-Voltage Bus Active Isolation Test Command: Command for this High Voltage Energy Storage Pack instance to perform an active electrical isolation test on the high voltage bus.An active isolation test might use a generated signal (e.g. an in...";
CM_ SG_ 2352021246 Hvsp7HghVltgBsPssvIsltnTstCmmnd "HVESP7 High-Voltage Bus Passive Isolation Test Command: Command for this High Voltage Energy Storage Pack instance to perform a passive electrical isolation test on the high voltage bus.A passive isolation test uses additional circuitry (e.g. a high ...";
CM_ SG_ 2352021246 Hvsp7EnlIntrnlChrgrCmmnd "HVESP7 Enable Internal Charger Command: When the HVES has an internal charger this parameter will enable it.   External chargers may use the External Energy Source Connection Demand (SPN 7890) and related SPs.This parameter is for one of multiple pac...";
CM_ SG_ 2352021246 Hvsp7HVtBsHSdRsstCtRqst "HVESP7 High-Voltage Bus High Side Resistor Connect Request: This parameter is used to request connection of this HVES instance High-Voltage bus high side resistor in order to perform an isolation test. See also SPN 14045 (HVESP7 High-Voltage Bus Low ...";
CM_ SG_ 2352021246 Hvsp7HghVltgBsLwSdRsstrCnntRqst "HVESP7 High-Voltage Bus Low Side Resistor Connect Request: This parameter is used to request connection of this HVES instance High-Voltage bus low side resistor in order to perform an isolation test. See also SPN 14044 (HVESP7 High-Voltage Bus High S...";
CM_ SG_ 2352021246 Hvsp7ThrmlMngmntMntnnRqst "HVESP7 Thermal Management Maintenance Request: Request to engage Thermal Management Maintenance Mode for this High Voltage Energy Storage System Pack instance.00b = HVESS Thermal Management Maintenance Mode is not requested01b = HVESS Thermal Managem...";
CM_ BO_ 2352086782 "High Voltage Energy Storage Pack 8 Control 1";
CM_ SG_ 2352086782 Hvesp8PowerDownCommand "HVESP8 Power-Down Command: Command to shut down this High Voltage Energy Storage Pack instance.  A normal power-down may involve steps that take some period of time (tests, writing of data, etc.).  However, an emergency power-down should shut down th...";
CM_ SG_ 2352086782 Hvesp8CellBalancingCommand "HVESP8 Cell Balancing Command: Command for this High Voltage Energy Storage Pack instance to perform cell balancing.This parameter is for one of multiple packs in an HVESS.  If there is only one pack in the system, the HVESS parameters should be used...";
CM_ SG_ 2352086782 Hvesp8OperationConsent "HVESP8 Operation Consent: This parameter provides an indication to this High Voltage Energy Storage Pack instance that an external device is ready for this HVES instance to proceed with normal operation.  In applications which support this parameter,...";
CM_ SG_ 2352086782 Hvesp8Control1Counter "HVESP8 Control 1 Counter: The message counter is used to detect situations where the transmitting ECU malfunction repeats the same frame all the time. The receiver of the information may use the counter parameter to detect this situation. The transmi...";
CM_ SG_ 2352086782 Hvesp8Control1Crc "HVESP8 Control 1 CRC: The CRC is defined as follows: - Length: 8 bits- Polynomial: x^8+x^5+x^3+x^2+x+1- Initial Value: FFh- Input Data Reflection: Not reflected- Result Data Reflection: Not reflected- XOR value: FFh SAE makes no claim of the function...";
CM_ SG_ 2352086782 Hvsp8HghVltgBsCnntCmmnd "HVESP8 High-Voltage Bus Connect Command: Command to connect this High Voltage Energy Storage Pack instance to the high-voltage bus.  The emergency contactor closure request may be used in situations where one or more faults in the hybrid or EV powert...";
CM_ SG_ 2352086782 Hvsp8HghVltgBsAtvIsltnTstCmmnd "HVESP8 High-Voltage Bus Active Isolation Test Command: Command for this High Voltage Energy Storage Pack instance to perform an active electrical isolation test on the high voltage bus.An active isolation test might use a generated signal (e.g. an in...";
CM_ SG_ 2352086782 Hvsp8HghVltgBsPssvIsltnTstCmmnd "HVESP8 High-Voltage Bus Passive Isolation Test Command: Command for this High Voltage Energy Storage Pack instance to perform a passive electrical isolation test on the high voltage bus.A passive isolation test uses additional circuitry (e.g. a high ...";
CM_ SG_ 2352086782 Hvsp8EnlIntrnlChrgrCmmnd "HVESP8 Enable Internal Charger Command: When the HVES has an internal charger this parameter will enable it.   External chargers may use the External Energy Source Connection Demand (SPN 7890) and related SPs.This parameter is for one of multiple pac...";
CM_ SG_ 2352086782 Hvsp8HVtBsHSdRsstCtRqst "HVESP8 High-Voltage Bus High Side Resistor Connect Request: This parameter is used to request connection of this HVES instance High-Voltage bus high side resistor in order to perform an isolation test. See also SPN 14188 (HVESP8 High-Voltage Bus Low ...";
CM_ SG_ 2352086782 Hvsp8HghVltgBsLwSdRsstrCnntRqst "HVESP8 High-Voltage Bus Low Side Resistor Connect Request: This parameter is used to request connection of this HVES instance High-Voltage bus low side resistor in order to perform an isolation test. See also SPN 14187 (HVESP8 High-Voltage Bus High S...";
CM_ SG_ 2352086782 Hvsp8ThrmlMngmntMntnnRqst "HVESP8 Thermal Management Maintenance Request: Request to engage Thermal Management Maintenance Mode for this High Voltage Energy Storage System Pack instance.00b = HVESS Thermal Management Maintenance Mode is not requested01b = HVESS Thermal Managem...";
CM_ BO_ 2352152318 "High Voltage Energy Storage Pack 9 Control 1";
CM_ SG_ 2352152318 Hvesp9PowerDownCommand "HVESP9 Power-Down Command: Command to shut down this High Voltage Energy Storage Pack instance.  A normal power-down may involve steps that take some period of time (tests, writing of data, etc.).  However, an emergency power-down should shut down th...";
CM_ SG_ 2352152318 Hvesp9CellBalancingCommand "HVESP9 Cell Balancing Command: Command for this High Voltage Energy Storage Pack instance to perform cell balancing.This parameter is for one of multiple packs in an HVESS.  If there is only one pack in the system, the HVESS parameters should be used...";
CM_ SG_ 2352152318 Hvesp9OperationConsent "HVESP9 Operation Consent: This parameter provides an indication to this High Voltage Energy Storage Pack instance that an external device is ready for this HVES instance to proceed with normal operation.  In applications which support this parameter,...";
CM_ SG_ 2352152318 Hvesp9Control1Counter "HVESP9 Control 1 Counter: The message counter is used to detect situations where the transmitting ECU malfunction repeats the same frame all the time. The receiver of the information may use the counter parameter to detect this situation. The transmi...";
CM_ SG_ 2352152318 Hvesp9Control1Crc "HVESP9 Control 1 CRC: The CRC is defined as follows: - Length: 8 bits- Polynomial: x^8+x^5+x^3+x^2+x+1- Initial Value: FFh- Input Data Reflection: Not reflected- Result Data Reflection: Not reflected- XOR value: FFh SAE makes no claim of the function...";
CM_ SG_ 2352152318 Hvsp9HghVltgBsCnntCmmnd "HVESP9 High-Voltage Bus Connect Command: Command to connect this High Voltage Energy Storage Pack instance to the high-voltage bus.  The emergency contactor closure request may be used in situations where one or more faults in the hybrid or EV powert...";
CM_ SG_ 2352152318 Hvsp9HghVltgBsAtvIsltnTstCmmnd "HVESP9 High-Voltage Bus Active Isolation Test Command: Command for this High Voltage Energy Storage Pack instance to perform an active electrical isolation test on the high voltage bus.An active isolation test might use a generated signal (e.g. an in...";
CM_ SG_ 2352152318 Hvsp9HghVltgBsPssvIsltnTstCmmnd "HVESP9 High-Voltage Bus Passive Isolation Test Command: Command for this High Voltage Energy Storage Pack instance to perform a passive electrical isolation test on the high voltage bus.A passive isolation test uses additional circuitry (e.g. a high ...";
CM_ SG_ 2352152318 Hvsp9EnlIntrnlChrgrCmmnd "HVESP9 Enable Internal Charger Command: When the HVES has an internal charger this parameter will enable it.   External chargers may use the External Energy Source Connection Demand (SPN 7890) and related SPs.This parameter is for one of multiple pac...";
CM_ SG_ 2352152318 Hvsp9HVtBsHSdRsstCtRqst "HVESP9 High-Voltage Bus High Side Resistor Connect Request: This parameter is used to request connection of this HVES instance High-Voltage bus high side resistor in order to perform an isolation test. See also SPN 14331 (HVESP9 High-Voltage Bus Low ...";
CM_ SG_ 2352152318 Hvsp9HghVltgBsLwSdRsstrCnntRqst "HVESP9 High-Voltage Bus Low Side Resistor Connect Request: This parameter is used to request connection of this HVES instance High-Voltage bus low side resistor in order to perform an isolation test. See also SPN 14330 (HVESP9 High-Voltage Bus High S...";
CM_ SG_ 2352152318 Hvsp9ThrmlMngmntMntnnRqst "HVESP9 Thermal Management Maintenance Request: Request to engage Thermal Management Maintenance Mode for this High Voltage Energy Storage System Pack instance.00b = HVESS Thermal Management Maintenance Mode is not requested01b = HVESS Thermal Managem...";
CM_ BO_ 2352217854 "High Voltage Energy Storage Pack 10 Control 1";
CM_ SG_ 2352217854 Hvesp10PowerDownCommand "HVESP10 Power-Down Command: Command to shut down this High Voltage Energy Storage Pack instance.  A normal power-down may involve steps that take some period of time (tests, writing of data, etc.).  However, an emergency power-down should shut down t...";
CM_ SG_ 2352217854 Hvesp10CellBalancingCommand "HVESP10 Cell Balancing Command: Command for this High Voltage Energy Storage Pack instance to perform cell balancing.This parameter is for one of multiple packs in an HVESS.  If there is only one pack in the system, the HVESS parameters should be use...";
CM_ SG_ 2352217854 Hvesp10OperationConsent "HVESP10 Operation Consent: This parameter provides an indication to this High Voltage Energy Storage Pack instance that an external device is ready for this HVES instance to proceed with normal operation.  In applications which support this parameter...";
CM_ SG_ 2352217854 Hvesp10Control1Counter "HVESP10 Control 1 Counter: The message counter is used to detect situations where the transmitting ECU malfunction repeats the same frame all the time. The receiver of the information may use the counter parameter to detect this situation. The transm...";
CM_ SG_ 2352217854 Hvesp10Control1Crc "HVESP10 Control 1 CRC: The CRC is defined as follows: - Length: 8 bits- Polynomial: x^8+x^5+x^3+x^2+x+1- Initial Value: FFh- Input Data Reflection: Not reflected- Result Data Reflection: Not reflected- XOR value: FFh SAE makes no claim of the functio...";
CM_ SG_ 2352217854 Hvsp10HghVltgBsCnntCmmnd "HVESP10 High-Voltage Bus Connect Command: Command to connect this High Voltage Energy Storage Pack instance to the high-voltage bus.  The emergency contactor closure request may be used in situations where one or more faults in the hybrid or EV power...";
CM_ SG_ 2352217854 Hvsp10HghVltgBsAtvIsltnTstCmmnd "HVESP10 High-Voltage Bus Active Isolation Test Command: Command for this High Voltage Energy Storage Pack instance to perform an active electrical isolation test on the high voltage bus.An active isolation test might use a generated signal (e.g. an i...";
CM_ SG_ 2352217854 Hvsp10HVtBsPssvIstTstCd "HVESP10 High-Voltage Bus Passive Isolation Test Command: Command for this High Voltage Energy Storage Pack instance to perform a passive electrical isolation test on the high voltage bus.A passive isolation test uses additional circuitry (e.g. a high...";
CM_ SG_ 2352217854 Hvsp10EnlIntrnlChrgrCmmnd "HVESP10 Enable Internal Charger Command: When the HVES has an internal charger this parameter will enable it.   External chargers may use the External Energy Source Connection Demand (SPN 7890) and related SPs.This parameter is for one of multiple pa...";
CM_ SG_ 2352217854 Hvsp10HVtBsHSdRsstCtRqst "HVESP10 High-Voltage Bus High Side Resistor Connect Request: This parameter is used to request connection of this HVES instance High-Voltage bus high side resistor in order to perform an isolation test. See also SPN 14474 (HVESP10 High-Voltage Bus Lo...";
CM_ SG_ 2352217854 Hvsp10HVtBsLwSdRsstCtRqst "HVESP10 High-Voltage Bus Low Side Resistor Connect Request: This parameter is used to request connection of this HVES instance High-Voltage bus low side resistor in order to perform an isolation test. See also SPN 14473 (HVESP10 High-Voltage Bus High...";
CM_ SG_ 2352217854 Hvsp10ThrmlMngmntMntnnRqst "HVESP10 Thermal Management Maintenance Request: Request to engage Thermal Management Maintenance Mode for this High Voltage Energy Storage System Pack instance.00b = HVESS Thermal Management Maintenance Mode is not requested01b = HVESS Thermal Manage...";
CM_ BO_ 2555379454 "Data Transfer Support";
CM_ SG_ 2555379454 DataTransferManufacturerId "Data Transfer Manufacturer ID: The 11-bit Manufacturer ID as defined in the J1939DA. An intermediary (e.g. telematics device) can use this to associate the Data Transfer Support requirements with the Data Transfer messages from the same manufacturer.";
CM_ SG_ 2555379454 TotalWeeklyMessageInstances "Total Weekly Message Instances: The total count of weekly message instances that will be broadcast by the transmitter. An intermediary (e.g. telematics device) can use this parameter to determine how many message instances it will receive after a Dat...";
CM_ SG_ 2555379454 LongestWeeklyMessageInstance "Longest Weekly Message Instance: The number of bytes in the longest Weekly Data Transfer message instance broadcast by the transmitter. An intermediary (e.g. telematics device) can use this to estimate the buffer sizes necessary to handle data acquir...";
CM_ SG_ 2555379454 TotalMonthlyMessageInstances "Total Monthly Message Instances: The total count of monthly message instances that will be broadcast by the transmitter. An intermediary (e.g. telematics device) can use this parameter to determine how many message instances it will receive after a D...";
CM_ SG_ 2555379454 LongestMonthlyMessageInstance "Longest Monthly Message Instance: The number of bytes in the longest Monthly Data Transfer message instance broadcast by the transmitter. An intermediary (e.g. telematics device) can use this to estimate the buffer sizes necessary to handle data acqu...";
CM_ SG_ 2555379454 TotalDailyMessageInstances "Total Daily Message Instances: The total count of daily message instances that will be broadcast by the transmitter. An intermediary (e.g. telematics device) can use this parameter to determine how many message instances it will receive after a Data ...";
CM_ SG_ 2555379454 LongestDailyMessageInstance "Longest Daily Message Instance: The number of bytes in the longest Daily Data Transfer message instance broadcast by the transmitter. An intermediary (e.g. telematics device) can use this to estimate the buffer sizes necessary to handle data acquired...";
CM_ SG_ 2555379454 TotalDailyMessageBytes "Total Daily Message Bytes: The total number of bytes in all Daily Data Transfer message instances that will be broadcast by the transmitter.  An intermediary (e.g. telematics device) can use this to estimate the amount of memory necessary to handle d...";
CM_ SG_ 2555379454 TotalWeeklyMessageBytes "Total Weekly Message Bytes: The total number of bytes in all Weekly Data Transfer message instances that will be broadcast by the transmitter. An intermediary (e.g. telematics device) can use this to estimate the amount of memory necessary to handle ...";
CM_ SG_ 2555379454 TotalMonthlyMessageBytes "Total Monthly Message Bytes: The total number of bytes in all Monthly Data Transfer message instances that will be broadcast by the transmitter. An intermediary (e.g. telematics device) can use this to estimate the amount of memory necessary to handl...";
CM_ BO_ 2555444990 "Monthly Data Transfer";
CM_ SG_ 2555444990 MonthlyMessageInstance "Monthly Message Instance: A transmitter sets this number to indicate the Monthly Data Transfer message instance currently being sent in a broadcast series. It allows an intermediary device to determine what message instance is being sent or was last ...";
CM_ SG_ 2555444990 MnthlMssgInstnsRmnng "Monthly Message Instances Remaining: This number indicates the message instances yet to be broadcast in a transmitter's Monthly Data Transfer broadcast series. When used together with SPN 12983 [Monthly Message Instance], an intermediary device can d...";
CM_ SG_ 2555444990 MonthlyDataManufacturerId "Monthly Data Manufacturer ID: This 11-bit Manufacturer ID (defined in the J1939DA) identifies the transmitter manufacturer whose cloud or data repository is the final destination for the associated data.";
CM_ BO_ 2555510526 "Weekly Data Transfer";
CM_ SG_ 2555510526 WeeklyMessageInstance "Weekly Message Instance: A transmitter sets this number to indicate the Weekly Data Transfer message instance currently being sent in a broadcast series. It allows an intermediary device to determine what message instance is being sent or was last re...";
CM_ SG_ 2555510526 WeeklyMessageInstancesRemaining "Weekly Message Instances Remaining: This number indicates the message instances yet to be broadcast in a transmitter's Weekly Transfer broadcast series. When used together with SPN 12978 [Weekly Message Instance], an intermediary device can determine...";
CM_ SG_ 2555510526 WeeklyDataManufacturerId "Weekly Data Manufacturer ID: This 11-bit Manufacturer ID (defined in the J1939DA) identifies the transmitter manufacturer whose cloud or data repository is the final destination for the associated data.";
CM_ BO_ 2555576062 "Daily Data Transfer";
CM_ SG_ 2555576062 DailyMessageInstance "Daily Message Instance: A transmitter sets this number to indicate the Daily Data Transfer message instance currently being sent in a broadcast series. It allows an intermediary device to determine what message instance is being sent or was last rece...";
CM_ SG_ 2555576062 DailyMessageInstancesRemaining "Daily Message Instances Remaining: This number indicates the message instances yet to be broadcast in a transmitter's Daily Data Transfer broadcast series. When used together with SPN 12973 [Daily Message Instance], an intermediary device can determi...";
CM_ SG_ 2555576062 DailyDataManufacturerId "Daily Data Manufacturer ID: This 11-bit Manufacturer ID (defined in the J1939DA) identifies the transmitter manufacturer whose cloud or data repository is the final destination for the associated data.";
CM_ BO_ 2364675326 "High Voltage Energy Storage Pack 7 Status 2";
CM_ SG_ 2364675326 Hvsp7DshrgPwrLmtDTSttOfChrg "HVESP7 Discharge Power Limit Due to State of Charge: Indicates whether or not discharge power of this HVES instance is being limited due to state of charge.This parameter is for one of multiple packs in an HVESS.  If there is only one pack in the sys...";
CM_ SG_ 2364675326 Hvsp7DshrgPwrLmtDTBttrTmprtr "HVESP7 Discharge Power Limit Due to Battery Temperature: Indicates whether or not discharge power of this HVES instance is being limited due to battery temperature.This parameter is for one of multiple packs in an HVESS.  If there is only one pack in...";
CM_ SG_ 2364675326 Hvsp7DsPwLtDTBttDstCdt "HVESP7 Discharge Power Limit Due to Battery Diagnostic Condition: Indicates whether or not discharge power of this HVES instance is being limited due to a battery diagnostic condition.This parameter is for one of multiple packs in an HVESS.  If there...";
CM_ SG_ 2364675326 Hvsp7DshrgPwrLmtDTBttrOrCllVltg "HVESP7 Discharge Power Limit Due to Battery or Cell Voltage: Indicates whether or not discharge power of this HVES instance is being limited due to a battery or cell voltage level.This parameter is for one of multiple packs in an HVESS.  If there is ...";
CM_ SG_ 2364675326 Hvsp7DshrgPwrLmtDTBttrCrrnt "HVESP7 Discharge Power Limit Due to Battery Current: Indicates whether or not discharge power of this HVES instance is being limited due to battery current.This parameter is for one of multiple packs in an HVESS.  If there is only one pack in the sys...";
CM_ SG_ 2364675326 Hvsp7DshrgPwrLmtDTAnUndfndCs "HVESP7 Discharge Power Limit Due to an Undefined Cause: Indicates whether or not discharge power of this HVES instance is being limited due to an undefined cause.This parameter is for one of multiple packs in an HVESS.  If there is only one pack in t...";
CM_ SG_ 2364675326 Hvsp7ChrgPwrLmtDTSttOfChrg "HVESP7 Charge Power Limit Due to State of Charge: Indicates whether or not charge power of this HVES instance is being limited due to state of charge.This parameter is for one of multiple packs in an HVESS.  If there is only one pack in the system, t...";
CM_ SG_ 2364675326 Hvsp7ChrgPwrLmtDTBttrTmprtr "HVESP7 Charge Power Limit Due to Battery Temperature: Indicates whether or not charge power of this HVES instance is being limited due to battery temperature.This parameter is for one of multiple packs in an HVESS.  If there is only one pack in the s...";
CM_ SG_ 2364675326 Hvsp7ChrgPwrLmtDTBttrDgnstCndtn "HVESP7 Charge Power Limit Due to Battery Diagnostic Condition: Indicates whether or not charge power of this HVES instance is being limited due to a battery diagnostic condition.This parameter is for one of multiple packs in an HVESS.  If there is on...";
CM_ SG_ 2364675326 Hvsp7ChrgPwrLmtDTBttrOrCllVltg "HVESP7 Charge Power Limit Due to Battery or Cell Voltage: Indicates whether or not charge power of this HVES instance is being limited due to a battery or cell voltage level.This parameter is for one of multiple packs in an HVESS.  If there is only o...";
CM_ SG_ 2364675326 Hvsp7ChrgPwrLmtDTBttrCrrnt "HVESP7 Charge Power Limit Due to Battery Current: Indicates whether or not charge power of this HVES instance is being limited due to battery current.This parameter is for one of multiple packs in an HVESS.  If there is only one pack in the system, t...";
CM_ SG_ 2364675326 Hvsp7ChrgPwrLmtDTAnUndfndCs "HVESP7 Charge Power Limit Due to an Undefined Cause: Indicates whether or not charge power of this HVES instance is being limited due to an undefined cause.This parameter is for one of multiple packs in an HVESS.  If there is only one pack in the sys...";
CM_ BO_ 2364675582 "High Voltage Energy Storage Pack 7 Data 1";
CM_ SG_ 2364675582 Hvesp7AvailableDischargePower "HVESP7 Available Discharge Power: The rate at which this High Voltage Energy Storage Pack instance can currently provide energy for propulsion or other uses.This parameter is for one of multiple packs in an HVESS.  If there is only one pack in the sy...";
CM_ SG_ 2364675582 Hvesp7AvailableChargePower "HVESP7 Available Charge Power: The rate at which this High Voltage Energy Storage Pack instance can currently receive energy from a regenerative or recharging system.This parameter is for one of multiple packs in an HVESS.  If there is only one pack ...";
CM_ SG_ 2364675582 Hvesp7VoltageLevel "HVESP7 Voltage Level: The voltage level of this High Voltage Energy Storage Pack instance. This parameter should be synchronized with SPN 14063 (HVESP7 Current) such that a realized power value can be calculated. If the HVES component physically cont...";
CM_ SG_ 2364675582 Hvesp7Current "HVESP7 Current: The current in or out of this High Voltage Energy Storage Pack instance. This parameter should be synchronized with SPN 14062 (HVESP7 Voltage Level) such that a realized power value can be calculated. This parameter is defined from th...";
CM_ BO_ 2364675838 "High Voltage Energy Storage Pack 7 Data 2";
CM_ SG_ 2364675838 Hvesp7FastUpdateStateOfCharge "HVESP7 Fast Update State of Charge: Indicates this High Voltage Energy Storage Pack instance state of charge. 0% means no charge remaining, 100% means the system is fully charged in terms of physical limits of this energy storage pack instance. Accep...";
CM_ SG_ 2364675838 Hvesp7HighestCellVoltage "HVESP7 Highest Cell Voltage: The highest voltage level reported by any cell in this High Voltage Energy Storage Pack instance. If a single voltage sensor covers more than one cell, the value in this parameter is for the smallest group of cells measur...";
CM_ SG_ 2364675838 Hvesp7LowestCellVoltage "HVESP7 Lowest Cell Voltage: The lowest voltage level reported by any cell in this High Voltage Energy Storage Pack instance. If a single voltage sensor covers more than one cell, the value in this parameter is for the smallest group of cells measured...";
CM_ SG_ 2364675838 Hvsp7CllVltgDffrntlStts "HVESP7 Cell Voltage Differential Status: Indicates whether or not the differential between the highest and lowest cell voltages are within acceptable limits, according to this High Voltage Energy Storage Pack instance. The actual voltage differential...";
CM_ BO_ 2364676094 "High Voltage Energy Storage Pack 7 Data 3";
CM_ SG_ 2364676094 Hvesp7HighestCellTemperature "HVESP7 Highest Cell Temperature: The highest temperature level reported by any cell in this High Voltage Energy Storage Pack instance. If a single temperature sensor covers more than one cell, the value in this parameter is for the smallest group of ...";
CM_ SG_ 2364676094 Hvesp7LowestCellTemperature "HVESP7 Lowest Cell Temperature: The lowest temperature level reported by any cell in this High Voltage Energy Storage Pack instance. If a single temperature sensor covers more than one cell, the value in this parameter is for the smallest group of ce...";
CM_ SG_ 2364676094 Hvesp7AverageCellTemperature "HVESP7 Average Cell Temperature: The average temperature level of all cells in this High Voltage Energy Storage Pack instance.This parameter is for one of multiple packs in an HVESS.  If there is only one pack in the system, the HVESS parameters shou...";
CM_ SG_ 2364676094 Hvsp7CllTmprtrDffrntlStts "HVESP7 Cell Temperature Differential Status: Indicates whether or not the differential between the highest and lowest cell temperatures are within acceptable limits per this High Voltage Energy Storage Pack instance. The actual temperature differenti...";
CM_ BO_ 2364676350 "High Voltage Energy Storage Pack 7 Data 4";
CM_ SG_ 2364676350 Hvesp7DischargeCapacity "HVESP7 Discharge Capacity: The amount of stored electrical charge in this High Voltage Energy Storage Pack instance that is available for use by the hybrid or EV system, i.e. 'how full is the tank'. See SPN 14102 (HVESP7 Discharge Energy Capacity) fo...";
CM_ SG_ 2364676350 Hvesp7ChargeCapacity "HVESP7 Charge Capacity: The amount of unused electrical charge storage in this High Voltage Energy Storage Pack instance that is available to be filled by charging, i.e. 'how much empty space is remaining in the tank'. See SPN 14103 (HVESP7 Charge En...";
CM_ SG_ 2364676350 Hvesp7CellBalancingCount "HVESP7 Cell Balancing Count: The number of cells that are currently being balanced in this High Voltage Energy Storage Pack instance.This parameter is for one of multiple packs in an HVESS.  If there is only one pack in the system, the HVESS paramete...";
CM_ BO_ 2364676606 "High Voltage Energy Storage Pack 7 Data 5";
CM_ SG_ 2364676606 Hvesp7LowestCellStateOfCharge "HVESP7 Lowest Cell State of Charge: Indicates the state of charge of the lowest-charged cell in this High Voltage Energy Storage Pack instance. 0% means no charge remaining, 100% means the cell is fully charged. If a single state of charge value cove...";
CM_ SG_ 2364676606 Hvesp7HighestCellStateOfCharge "HVESP7 Highest Cell State of Charge: Indicates the state of charge of the highest-charged cell in this High Voltage Energy Storage Pack instance. 0% means no charge remaining, 100% means the cell is fully charged. If a single state of charge value co...";
CM_ SG_ 2364676606 Hvsp7MxmmInstntnsDshrgCrrntLmt "HVESP7 Maximum Instantaneous Discharge Current Limit: The maximum instantaneous current flow limit out of this High Voltage Energy Storage Pack instance. This parameter is defined from the high voltage energy storage pack's point of view and should r...";
CM_ SG_ 2364676606 Hvsp7MxmmInstntnsChrgCrrntLmt "HVESP7 Maximum Instantaneous Charge Current Limit: The maximum instantaneous current flow limit into this High Voltage Energy Storage Pack instance. This parameter is defined from the high voltage energy storage pack's point of view and should reflec...";
CM_ BO_ 2364676862 "High Voltage Energy Storage Pack 7 Data 6";
CM_ SG_ 2364676862 Hvesp7BusVoltage "HVESP7 Bus Voltage: The voltage level of the high voltage bus, as measured by this High Voltage Energy Storage Pack instance on the bus side (not the battery side) of its contactors.This parameter is for one of multiple packs in an HVESS.  If there i...";
CM_ SG_ 2364676862 Hvesp7IgnitionVoltage "HVESP7 Ignition Voltage: The voltage level at the ignition input of this High Voltage Energy Storage Pack controller.This parameter is for one of multiple packs in an HVESS.  If there is only one pack in the system, the HVESS parameters should be use...";
CM_ SG_ 2364676862 Hvesp7IntakeCoolantTemperature "HVESP7 Intake Coolant Temperature: The temperature of liquid coolant as it enters this High Voltage Energy Storage Pack instance.This parameter is for one of multiple packs in an HVESS.  If there is only one pack in the system, the HVESS parameters s...";
CM_ SG_ 2364676862 Hvesp7OutletCoolantTemperature "HVESP7 Outlet Coolant Temperature: The temperature of liquid coolant as it exits this High Voltage Energy Storage Pack instance.This parameter is for one of multiple packs in an HVESS.  If there is only one pack in the system, the HVESS parameters sh...";
CM_ SG_ 2364676862 Hvesp7ElectronicsTemperature "HVESP7 Electronics Temperature: The temperature of the electronics or control modules in this High Voltage Energy Storage Pack instance.  If there are multiple temperature sensors then this parameter would be set to the maximum sensor reading.This pa...";
CM_ SG_ 2364676862 Hvesp7Temperature "HVESP7 Temperature: The temperature of this High Voltage Energy Storage Pack instance. The value may be determined from a unique sensor specifically for this purpose, or by aggregating various temperature sensor readings within the pack.This paramete...";
CM_ BO_ 2364677118 "High Voltage Energy Storage Pack 7 Status 1";
CM_ SG_ 2364677118 Hvesp7HvilStatus "HVESP7 HVIL Status: Status of the High Voltage Interlock Loop from the viewpoint of this High Voltage Energy Storage Pack instance.This parameter is for one of multiple packs in an HVESS. If there is only one pack in the system, the HVESS parameters ...";
CM_ SG_ 2364677118 Hvesp7InertiaSwitchStatus "HVESP7 Inertia Switch Status: Switch indicating that an impact has been sensed by this High Voltage Energy Storage Pack instance. The impact indication may require action by another controller, or by this HVES instance itself.  For example, a control...";
CM_ SG_ 2364677118 Hvesp7StateOfChargeStatus "HVESP7 State of Charge Status: Status of this High Voltage Energy Storage Pack instance State of Charge (SOC).  Note:  A given HVES controller may not support all of the states.This parameter is for one of multiple packs in an HVESS.  If there is onl...";
CM_ SG_ 2364677118 Hvesp7CellBalanceStatus "HVESP7 Cell Balance Status: Indicates whether or not the cells in this High Voltage Energy Storage Pack instance are balanced.This parameter is for one of multiple packs in an HVESS.  If there is only one pack in the system, the HVESS parameters shou...";
CM_ SG_ 2364677118 Hvesp7CellBalancingActive "HVESP7 Cell Balancing Active: Indicates whether or not the cells in this High Voltage Energy Storage Pack instance are currently being balanced.This parameter is for one of multiple packs in an HVESS.  If there is only one pack in the system, the HVE...";
CM_ SG_ 2364677118 Hvesp7InternalChargerStatus "HVESP7 Internal Charger Status: Indicates that the charger in this HVES instance is on.  External chargers may use the External Energy Source Connection Status (SPN 7898) and related SPs.This parameter is for one of multiple packs in an HVESS. If the...";
CM_ SG_ 2364677118 Hvesp7OperationalStatus "HVESP7 Operational Status: Provides feedback on where this High Voltage Energy Storage Pack instance is in its operating spectrum, and includes feedback in response to the Operation Consent [i.e. SPN 14043 (HVESP7 Operation Consent)] and Power Down C...";
CM_ SG_ 2364677118 Hvesp7Status1Counter "HVESP7 Status 1 Counter: The message counter is used to detect situations where the transmitting ECU malfunction repeats the same frame all the time. The receiver of the information may use the counter parameter to detect this situation. The transmit...";
CM_ SG_ 2364677118 Hvesp7Status1Crc "HVESP7 Status 1 CRC: The CRC is defined as follows: - Length: 8 bits- Polynomial: x^8+x^5+x^3+x^2+x+1- Initial Value: FFh- Input Data Reflection: Not reflected- Result Data Reflection: Not reflected- XOR value: FFh SAE makes no claim of the functiona...";
CM_ SG_ 2364677118 Hvsp7HghVltgBsPstvCnttrStt "HVESP7 High-Voltage Bus (Positive) Contactor State: Position of this High Voltage Energy Storage Pack instance positive side bus contactor.  When this contactor is closed, the positive side of this HVES instance is connected to the positive side of t...";
CM_ SG_ 2364677118 Hvsp7HghVltgBsNgtvCnttrStt "HVESP7 High-Voltage Bus (Negative) Contactor State: Position of this High Voltage Energy Storage Pack instance negative side bus contactor. When this contactor is closed, the negative side of this HVES instance is connected to the negative side of th...";
CM_ SG_ 2364677118 Hvsp7HghVltgBsDsnntFrwrnng "HVESP7 High-Voltage Bus Disconnect Forewarning: Indicates that this High Voltage Energy Storage Pack instance is about to disconnect from the high voltage bus due to unacceptable conditions.This parameter is for one of multiple packs in an HVESS. If ...";
CM_ SG_ 2364677118 Hvsp7HghVltgBsPrChrgRlStt "HVESP7 High-Voltage Bus Pre-Charge Relay State: Position of the high-voltage bus contactor pre-charge relay.  When this relay is closed, this High Voltage Energy Storage Pack instance is bringing the high-voltage bus up to its operating level.This pa...";
CM_ SG_ 2364677118 Hvsp7CntrOfPkCnttrStt "HVESP7 Center of Pack Contactor State: Position of the center high-voltage contactor. When this contactor is closed, the positive half of this High Voltage Energy Storage Pack instance is connected to the negative half. If a system controls the posit...";
CM_ SG_ 2364677118 Hvsp7HghVltgBsAtvIsltnTstStts "HVESP7 High-Voltage Bus Active Isolation Test Status: Status of the high-voltage bus electrical active isolation test as performed by this High Voltage Energy Storage Pack instance.This parameter is for one of multiple packs in an HVESS. If there is ...";
CM_ SG_ 2364677118 Hvsp7HghVltgBsPssvIsltnTstStts "HVESP7 High-Voltage Bus Passive Isolation Test Status: Status of the high-voltage bus electrical passive isolation test as performed by this High Voltage Energy Storage Pack instance.This parameter is for one of multiple packs in an HVESS. If there i...";
CM_ SG_ 2364677118 Hvsp7HghVltgBsCnntnStts "HVESP7 High-Voltage Bus Connection Status: This parameter provides high level feedback on this High Voltage Energy Storage Pack instance high voltage bus connection. For specific contactor information, see SPN 14085 (HVESP7 High-Voltage Bus (Positive...";
CM_ BO_ 2364677374 "High Voltage Energy Storage Pack 7 Data 7";
CM_ SG_ 2364677374 Hvesp7DischargeEnergyCapacity "HVESP7 Discharge Energy Capacity: The amount of stored electrical energy in this High Voltage Energy Storage Pack instance that is available for use by the hybrid or EV system, i.e. 'how full is the tank'. See SPN 14072 (HVESP7 Discharge Capacity) fo...";
CM_ SG_ 2364677374 Hvesp7ChargeEnergyCapacity "HVESP7 Charge Energy Capacity: The amount of unused electrical energy storage available to be filled by charging this High Voltage Energy Storage Pack instance, i.e. 'how much empty space is remaining in the tank'. See SPN 14073 (HVESP7 Charge Capaci...";
CM_ SG_ 2364677374 Hvesp7MaximumChargeVoltageLimit "HVESP7 Maximum Charge Voltage Limit: The maximum voltage level not to be exceeded while charging this High Voltage Energy Storage Pack instance. If this parameter is not supported, the maximum charge voltage should be limited to SPN 14173 (HVESP7 Rec...";
BA_DEF_ SG_  "SPN" INT 0 524287;
BA_DEF_ BO_  "VFrameFormat" ENUM  "StandardCAN","ExtendedCAN","reserved","J1939PG";
BA_DEF_DEF_  "SPN" 0;
BA_DEF_DEF_  "VFrameFormat" "J1939PG";
BA_ "SPN" SG_ 2566605566 MtGt3IvtPwLtdDTUddRs 11889;
BA_ "SPN" SG_ 2566605566 MtGt3IvtPwLtdDTMPwMx 11894;
BA_ "SPN" SG_ 2566605566 MtGt3IvtPwLtdDTMPwM 11895;
BA_ "SPN" SG_ 2566605566 MtrGnrtr3InvrtrPwrLmtdDTTrqMxmm 11898;
BA_ "SPN" SG_ 2566605566 MtrGnrtr3InvrtrPwrLmtdDTTrqMnmm 11899;
BA_ "SPN" SG_ 2566605566 MtrGnrtr3InvrtrPwrLmtdDTSpdMxmm 11900;
BA_ "SPN" SG_ 2566605566 MtrGnrtr3InvrtrPwrLmtdDTSpdMnmm 11901;
BA_ "SPN" SG_ 2566605566 MtGt3IvtPwLtdDTIvtTpt 11902;
BA_ "SPN" SG_ 2566605566 MtGt3IvtPwLtdDTMtTpt 11903;
BA_ "SPN" SG_ 2566605566 MtGt3IvtPwLtdDTFtCdt 13049;
BA_ "SPN" SG_ 2566605566 MtGt3IvtPwLtdDTAtvTqRtLt 13050;
BA_ "SPN" SG_ 2566605566 MtGt3IvtPwLtdDTAtvSpdRtLt 13051;
BA_ "SPN" SG_ 2566605566 MtGt3IvtTqLtdDTMCtsts 13052;
BA_ "SPN" SG_ 2566605566 MtGt3IvtPwLtdDTDSdCtMx 11890;
BA_ "SPN" SG_ 2566605566 MtGt3IvtPwLtdDTDSdCtM 11891;
BA_ "SPN" SG_ 2566605566 MtGt3IvtPwLtdDTDSdVtMx 11892;
BA_ "SPN" SG_ 2566605566 MtGt3IvtPwLtdDTDSdVtM 11893;
BA_ "SPN" SG_ 2566605566 MtGt3IvtPwLtdDTDSdPwMx 11896;
BA_ "SPN" SG_ 2566605566 MtGt3IvtPwLtdDTDSdPwM 11897;
BA_ "SPN" SG_ 2566605822 SAddssOCtDvFTs1CtPpsP7 11756;
BA_ "SPN" SG_ 2566605822 Ts1CntrlPrpsP7RdnssStts 11757;
BA_ "SPN" SG_ 2566605822 AdsVhlSpdCntrlCmmndRdnssStts 15249;
BA_ "SPN" SG_ 2566605822 SAddssOCtDvFAdsVSpdCtCd 15250;
BA_ "SPN" SG_ 2566605822 AdsVhlSpdCntrlCmmndFdk 15251;
BA_ "SPN" SG_ 2566605822 AdsVhlSpdCntrlOprtnStts 21168;
BA_ "SPN" SG_ 2566605822 Adss1EmbeddedIntegritySupport 23056;
BA_ "SPN" SG_ 2566605822 Adss1Counter 23057;
BA_ "SPN" SG_ 2566605822 Adss1Crc 23058;
BA_ "SPN" SG_ 2566606078 CabHeaterPower 11755;
BA_ "SPN" SG_ 2566606078 CabACCompressorPower 20464;
BA_ "SPN" SG_ 2566606334 EngineAirFilter1LifeRemaining 11737;
BA_ "SPN" SG_ 2566606334 EngineAirFilter2LifeRemaining 11738;
BA_ "SPN" SG_ 2566606334 EngineAirFilter3LifeRemaining 11739;
BA_ "SPN" SG_ 2566606334 EngineAirFilter4LifeRemaining 11740;
BA_ "SPN" SG_ 2566606334 EngineFuelFilterLifeRemaining 11741;
BA_ "SPN" SG_ 2566606334 EngnFlFltrStnSdLfRmnng 11742;
BA_ "SPN" SG_ 2566606334 EngineOilFilterLifeRemaining 11743;
BA_ "SPN" SG_ 2566606334 TrnsmssnOlFltrLfRmnng 11744;
BA_ "SPN" SG_ 2499497726 HoistLeverPosition 11727;
BA_ "SPN" SG_ 2499497726 HoistLeverDetentPositionStatus 11728;
BA_ "SPN" SG_ 2633715710 Hvesp6StateOfHealth 11721;
BA_ "SPN" SG_ 2633715710 Hvesp6TotalEnergyThroughput 11723;
BA_ "SPN" SG_ 2633715710 Hvesp6TotalAccumulatedCharge 11724;
BA_ "SPN" SG_ 2633715710 Hvesp6TotalLifetimeEnergyInput 13377;
BA_ "SPN" SG_ 2633715710 Hvesp6TotalLifetimeEnergyOutput 13378;
BA_ "SPN" SG_ 2633715710 Hvsp6CnttrOpnUndrLdCnt 11722;
BA_ "SPN" SG_ 2566607102 Hvesp6NominalVoltage 11712;
BA_ "SPN" SG_ 2566607102 Hvesp6CellMaximumVoltageLimit 11719;
BA_ "SPN" SG_ 2566607102 Hvesp6CellMinimumVoltageLimit 11720;
BA_ "SPN" SG_ 2566607102 Hvsp6RmmnddMnmmOprtngVltg 11713;
BA_ "SPN" SG_ 2566607102 Hvsp6RmmnddMxmmOprtngVltg 11714;
BA_ "SPN" SG_ 2566607102 Hvsp6RmmnddMnmmSttOfChrg 11715;
BA_ "SPN" SG_ 2566607102 Hvsp6RmmnddMxmmSttOfChrg 11716;
BA_ "SPN" SG_ 2566607102 Hvsp6RmmnddMxmmOprtngTmprtr 11717;
BA_ "SPN" SG_ 2566607102 Hvsp6RmmnddMnmmOprtngTmprtr 11718;
BA_ "SPN" SG_ 2566607102 Hvesp6NominalRatedCapacity 15256;
BA_ "SPN" SG_ 2633716222 Hvesp5StateOfHealth 11605;
BA_ "SPN" SG_ 2633716222 Hvesp5TotalEnergyThroughput 11607;
BA_ "SPN" SG_ 2633716222 Hvesp5TotalAccumulatedCharge 11608;
BA_ "SPN" SG_ 2633716222 Hvesp5TotalLifetimeEnergyInput 13375;
BA_ "SPN" SG_ 2633716222 Hvesp5TotalLifetimeEnergyOutput 13376;
BA_ "SPN" SG_ 2633716222 Hvsp5CnttrOpnUndrLdCnt 11606;
BA_ "SPN" SG_ 2566607614 Hvesp5NominalVoltage 11596;
BA_ "SPN" SG_ 2566607614 Hvesp5CellMaximumVoltageLimit 11603;
BA_ "SPN" SG_ 2566607614 Hvesp5CellMinimumVoltageLimit 11604;
BA_ "SPN" SG_ 2566607614 Hvsp5RmmnddMnmmOprtngVltg 11597;
BA_ "SPN" SG_ 2566607614 Hvsp5RmmnddMxmmOprtngVltg 11598;
BA_ "SPN" SG_ 2566607614 Hvsp5RmmnddMnmmSttOfChrg 11599;
BA_ "SPN" SG_ 2566607614 Hvsp5RmmnddMxmmSttOfChrg 11600;
BA_ "SPN" SG_ 2566607614 Hvsp5RmmnddMxmmOprtngTmprtr 11601;
BA_ "SPN" SG_ 2566607614 Hvsp5RmmnddMnmmOprtngTmprtr 11602;
BA_ "SPN" SG_ 2566607614 Hvesp5NominalRatedCapacity 15257;
BA_ "SPN" SG_ 2633716734 Hvesp4StateOfHealth 11489;
BA_ "SPN" SG_ 2633716734 Hvesp4TotalEnergyThroughput 11491;
BA_ "SPN" SG_ 2633716734 Hvesp4TotalAccumulatedCharge 11492;
BA_ "SPN" SG_ 2633716734 Hvesp4TotalLifetimeEnergyInput 13373;
BA_ "SPN" SG_ 2633716734 Hvesp4TotalLifetimeEnergyOutput 13374;
BA_ "SPN" SG_ 2633716734 Hvsp4CnttrOpnUndrLdCnt 11490;
BA_ "SPN" SG_ 2566608126 Hvesp4NominalVoltage 11480;
BA_ "SPN" SG_ 2566608126 Hvesp4CellMaximumVoltageLimit 11487;
BA_ "SPN" SG_ 2566608126 Hvesp4CellMinimumVoltageLimit 11488;
BA_ "SPN" SG_ 2566608126 Hvsp4RmmnddMnmmOprtngVltg 11481;
BA_ "SPN" SG_ 2566608126 Hvsp4RmmnddMxmmOprtngVltg 11482;
BA_ "SPN" SG_ 2566608126 Hvsp4RmmnddMnmmSttOfChrg 11483;
BA_ "SPN" SG_ 2566608126 Hvsp4RmmnddMxmmSttOfChrg 11484;
BA_ "SPN" SG_ 2566608126 Hvsp4RmmnddMxmmOprtngTmprtr 11485;
BA_ "SPN" SG_ 2566608126 Hvsp4RmmnddMnmmOprtngTmprtr 11486;
BA_ "SPN" SG_ 2566608126 Hvesp4NominalRatedCapacity 15258;
BA_ "SPN" SG_ 2633717246 Hvesp3StateOfHealth 11373;
BA_ "SPN" SG_ 2633717246 Hvesp3TotalEnergyThroughput 11375;
BA_ "SPN" SG_ 2633717246 Hvesp3TotalAccumulatedCharge 11376;
BA_ "SPN" SG_ 2633717246 Hvesp3TotalLifetimeEnergyInput 13371;
BA_ "SPN" SG_ 2633717246 Hvesp3TotalLifetimeEnergyOutput 13372;
BA_ "SPN" SG_ 2633717246 Hvsp3CnttrOpnUndrLdCnt 11374;
BA_ "SPN" SG_ 2566608638 Hvesp3NominalVoltage 11364;
BA_ "SPN" SG_ 2566608638 Hvesp3CellMaximumVoltageLimit 11371;
BA_ "SPN" SG_ 2566608638 Hvesp3CellMinimumVoltageLimit 11372;
BA_ "SPN" SG_ 2566608638 Hvsp3RmmnddMnmmOprtngVltg 11365;
BA_ "SPN" SG_ 2566608638 Hvsp3RmmnddMxmmOprtngVltg 11366;
BA_ "SPN" SG_ 2566608638 Hvsp3RmmnddMnmmSttOfChrg 11367;
BA_ "SPN" SG_ 2566608638 Hvsp3RmmnddMxmmSttOfChrg 11368;
BA_ "SPN" SG_ 2566608638 Hvsp3RmmnddMxmmOprtngTmprtr 11369;
BA_ "SPN" SG_ 2566608638 Hvsp3RmmnddMnmmOprtngTmprtr 11370;
BA_ "SPN" SG_ 2566608638 Hvesp3NominalRatedCapacity 15259;
BA_ "SPN" SG_ 2633717758 Hvesp2StateOfHealth 11257;
BA_ "SPN" SG_ 2633717758 Hvesp2TotalEnergyThroughput 11259;
BA_ "SPN" SG_ 2633717758 Hvesp2TotalAccumulatedCharge 11260;
BA_ "SPN" SG_ 2633717758 Hvesp2TotalLifetimeEnergyInput 13369;
BA_ "SPN" SG_ 2633717758 Hvesp2TotalLifetimeEnergyOutput 13370;
BA_ "SPN" SG_ 2633717758 Hvsp2CnttrOpnUndrLdCnt 11258;
BA_ "SPN" SG_ 2566609150 Hvesp2NominalVoltage 11248;
BA_ "SPN" SG_ 2566609150 Hvesp2CellMaximumVoltageLimit 11255;
BA_ "SPN" SG_ 2566609150 Hvesp2CellMinimumVoltageLimit 11256;
BA_ "SPN" SG_ 2566609150 Hvsp2RmmnddMnmmOprtngVltg 11249;
BA_ "SPN" SG_ 2566609150 Hvsp2RmmnddMxmmOprtngVltg 11250;
BA_ "SPN" SG_ 2566609150 Hvsp2RmmnddMnmmSttOfChrg 11251;
BA_ "SPN" SG_ 2566609150 Hvsp2RmmnddMxmmSttOfChrg 11252;
BA_ "SPN" SG_ 2566609150 Hvsp2RmmnddMxmmOprtngTmprtr 11253;
BA_ "SPN" SG_ 2566609150 Hvsp2RmmnddMnmmOprtngTmprtr 11254;
BA_ "SPN" SG_ 2566609150 Hvesp2NominalRatedCapacity 15260;
BA_ "SPN" SG_ 2633718270 Hvesp1StateOfHealth 11141;
BA_ "SPN" SG_ 2633718270 Hvesp1TotalEnergyThroughput 11143;
BA_ "SPN" SG_ 2633718270 Hvesp1TotalAccumulatedCharge 11144;
BA_ "SPN" SG_ 2633718270 Hvesp1TotalLifetimeEnergyInput 13367;
BA_ "SPN" SG_ 2633718270 Hvesp1TotalLifetimeEnergyOutput 13368;
BA_ "SPN" SG_ 2633718270 Hvsp1CnttrOpnUndrLdCnt 11142;
BA_ "SPN" SG_ 2566609662 Hvesp1NominalVoltage 11132;
BA_ "SPN" SG_ 2566609662 Hvesp1CellMaximumVoltageLimit 11139;
BA_ "SPN" SG_ 2566609662 Hvesp1CellMinimumVoltageLimit 11140;
BA_ "SPN" SG_ 2566609662 Hvsp1RmmnddMnmmOprtngVltg 11133;
BA_ "SPN" SG_ 2566609662 Hvsp1RmmnddMxmmOprtngVltg 11134;
BA_ "SPN" SG_ 2566609662 Hvsp1RmmnddMnmmSttOfChrg 11135;
BA_ "SPN" SG_ 2566609662 Hvsp1RmmnddMxmmSttOfChrg 11136;
BA_ "SPN" SG_ 2566609662 Hvsp1RmmnddMxmmOprtngTmprtr 11137;
BA_ "SPN" SG_ 2566609662 Hvsp1RmmnddMnmmOprtngTmprtr 11138;
BA_ "SPN" SG_ 2566609662 Hvesp1NominalRatedCapacity 15261;
BA_ "SPN" SG_ 2633718782 VfssMdl1Dttr1DttrTp 10845;
BA_ "SPN" SG_ 2633718782 VfssMdl1Dttr2DttrTp 10848;
BA_ "SPN" SG_ 2633718782 VfssMdl1Dttr3DttrTp 10851;
BA_ "SPN" SG_ 2633718782 VfssMdl1Dttr4DttrTp 10854;
BA_ "SPN" SG_ 2633718782 VfssMdl1Dttr5DttrTp 10857;
BA_ "SPN" SG_ 2633718782 VfssMdl1Dttr6DttrTp 10860;
BA_ "SPN" SG_ 2633718782 VfssMdl1Dttr7DttrTp 10863;
BA_ "SPN" SG_ 2633718782 VfssMdl1Dttr8DttrTp 10866;
BA_ "SPN" SG_ 2633718782 VfssMdl1Dttr1DttrDtSlt 10846;
BA_ "SPN" SG_ 2633718782 VfssMdl1Dttr2DttrDtSlt 10849;
BA_ "SPN" SG_ 2633718782 VfssMdl1Dttr3DttrDtSlt 10852;
BA_ "SPN" SG_ 2633718782 VfssMdl1Dttr4DttrDtSlt 10855;
BA_ "SPN" SG_ 2633718782 VfssMdl1Dttr5DttrDtSlt 10858;
BA_ "SPN" SG_ 2633718782 VfssMdl1Dttr6DttrDtSlt 10861;
BA_ "SPN" SG_ 2633718782 VfssMdl1Dttr7DttrDtSlt 10864;
BA_ "SPN" SG_ 2633718782 VfssMdl1Dttr8DttrDtSlt 10867;
BA_ "SPN" SG_ 2633719038 VfssMdl2Dttr1DttrTp 10869;
BA_ "SPN" SG_ 2633719038 VfssMdl2Dttr2DttrTp 10872;
BA_ "SPN" SG_ 2633719038 VfssMdl2Dttr3DttrTp 10875;
BA_ "SPN" SG_ 2633719038 VfssMdl2Dttr4DttrTp 10878;
BA_ "SPN" SG_ 2633719038 VfssMdl2Dttr5DttrTp 10881;
BA_ "SPN" SG_ 2633719038 VfssMdl2Dttr6DttrTp 10884;
BA_ "SPN" SG_ 2633719038 VfssMdl2Dttr7DttrTp 10887;
BA_ "SPN" SG_ 2633719038 VfssMdl2Dttr8DttrTp 10890;
BA_ "SPN" SG_ 2633719038 VfssMdl2Dttr1DttrDtSlt 10870;
BA_ "SPN" SG_ 2633719038 VfssMdl2Dttr2DttrDtSlt 10873;
BA_ "SPN" SG_ 2633719038 VfssMdl2Dttr3DttrDtSlt 10876;
BA_ "SPN" SG_ 2633719038 VfssMdl2Dttr4DttrDtSlt 10879;
BA_ "SPN" SG_ 2633719038 VfssMdl2Dttr5DttrDtSlt 10882;
BA_ "SPN" SG_ 2633719038 VfssMdl2Dttr6DttrDtSlt 10885;
BA_ "SPN" SG_ 2633719038 VfssMdl2Dttr7DttrDtSlt 10888;
BA_ "SPN" SG_ 2633719038 VfssMdl2Dttr8DttrDtSlt 10891;
BA_ "SPN" SG_ 2633719294 VfssMdl3Dttr1DttrTp 10893;
BA_ "SPN" SG_ 2633719294 VfssMdl3Dttr2DttrTp 10896;
BA_ "SPN" SG_ 2633719294 VfssMdl3Dttr3DttrTp 10899;
BA_ "SPN" SG_ 2633719294 VfssMdl3Dttr4DttrTp 10902;
BA_ "SPN" SG_ 2633719294 VfssMdl3Dttr5DttrTp 10905;
BA_ "SPN" SG_ 2633719294 VfssMdl3Dttr6DttrTp 10908;
BA_ "SPN" SG_ 2633719294 VfssMdl3Dttr7DttrTp 10911;
BA_ "SPN" SG_ 2633719294 VfssMdl3Dttr8DttrTp 10914;
BA_ "SPN" SG_ 2633719294 VfssMdl3Dttr1DttrDtSlt 10894;
BA_ "SPN" SG_ 2633719294 VfssMdl3Dttr2DttrDtSlt 10897;
BA_ "SPN" SG_ 2633719294 VfssMdl3Dttr3DttrDtSlt 10900;
BA_ "SPN" SG_ 2633719294 VfssMdl3Dttr4DttrDtSlt 10903;
BA_ "SPN" SG_ 2633719294 VfssMdl3Dttr5DttrDtSlt 10906;
BA_ "SPN" SG_ 2633719294 VfssMdl3Dttr6DttrDtSlt 10909;
BA_ "SPN" SG_ 2633719294 VfssMdl3Dttr7DttrDtSlt 10912;
BA_ "SPN" SG_ 2633719294 VfssMdl3Dttr8DttrDtSlt 10915;
BA_ "SPN" SG_ 2633719550 VfssMdl4Dttr1DttrTp 10917;
BA_ "SPN" SG_ 2633719550 VfssMdl4Dttr2DttrTp 10920;
BA_ "SPN" SG_ 2633719550 VfssMdl4Dttr3DttrTp 10923;
BA_ "SPN" SG_ 2633719550 VfssMdl4Dttr4DttrTp 10926;
BA_ "SPN" SG_ 2633719550 VfssMdl4Dttr5DttrTp 10929;
BA_ "SPN" SG_ 2633719550 VfssMdl4Dttr6DttrTp 10932;
BA_ "SPN" SG_ 2633719550 VfssMdl4Dttr7DttrTp 10935;
BA_ "SPN" SG_ 2633719550 VfssMdl4Dttr8DttrTp 10938;
BA_ "SPN" SG_ 2633719550 VfssMdl4Dttr1DttrDtSlt 10918;
BA_ "SPN" SG_ 2633719550 VfssMdl4Dttr2DttrDtSlt 10921;
BA_ "SPN" SG_ 2633719550 VfssMdl4Dttr3DttrDtSlt 10924;
BA_ "SPN" SG_ 2633719550 VfssMdl4Dttr4DttrDtSlt 10927;
BA_ "SPN" SG_ 2633719550 VfssMdl4Dttr5DttrDtSlt 10930;
BA_ "SPN" SG_ 2633719550 VfssMdl4Dttr6DttrDtSlt 10933;
BA_ "SPN" SG_ 2633719550 VfssMdl4Dttr7DttrDtSlt 10936;
BA_ "SPN" SG_ 2633719550 VfssMdl4Dttr8DttrDtSlt 10939;
BA_ "SPN" SG_ 2633719806 VfssModule1HeatZone1Data 10941;
BA_ "SPN" SG_ 2633719806 VfssModule1HeatZone2Data 10942;
BA_ "SPN" SG_ 2633719806 VfssModule1ReleaseZone1Data 10943;
BA_ "SPN" SG_ 2633719806 VfssModule1ReleaseZone2Data 10944;
BA_ "SPN" SG_ 2633719806 VfssModule1PressureSwitch1Data 10945;
BA_ "SPN" SG_ 2633719806 VfssModule1PressureSwitch2Data 10946;
BA_ "SPN" SG_ 2633719806 VfssModule1PrimaryPowerVoltage 10947;
BA_ "SPN" SG_ 2633719806 VfssMdl1SndrPwrVltg 10948;
BA_ "SPN" SG_ 2633720062 VfssModule2HeatZone1Data 10949;
BA_ "SPN" SG_ 2633720062 VfssModule2HeatZone2Data 10950;
BA_ "SPN" SG_ 2633720062 VfssModule2ReleaseZone1Data 10951;
BA_ "SPN" SG_ 2633720062 VfssModule2ReleaseZone2Data 10952;
BA_ "SPN" SG_ 2633720062 VfssModule2PressureSwitch1Data 10953;
BA_ "SPN" SG_ 2633720062 VfssModule2PressureSwitch2Data 10954;
BA_ "SPN" SG_ 2633720062 VfssModule2PrimaryPowerVoltage 10955;
BA_ "SPN" SG_ 2633720062 VfssMdl2SndrPwrVltg 10956;
BA_ "SPN" SG_ 2633720318 VfssModule3HeatZone1Data 10957;
BA_ "SPN" SG_ 2633720318 VfssModule3HeatZone2Data 10958;
BA_ "SPN" SG_ 2633720318 VfssModule3ReleaseZone1Data 10959;
BA_ "SPN" SG_ 2633720318 VfssModule3ReleaseZone2Data 10960;
BA_ "SPN" SG_ 2633720318 VfssModule3PressureSwitch1Data 10961;
BA_ "SPN" SG_ 2633720318 VfssModule3PressureSwitch2Data 10962;
BA_ "SPN" SG_ 2633720318 VfssModule3PrimaryPowerVoltage 10963;
BA_ "SPN" SG_ 2633720318 VfssMdl3SndrPwrVltg 10964;
BA_ "SPN" SG_ 2633720574 VfssModule4HeatZone1Data 10965;
BA_ "SPN" SG_ 2633720574 VfssModule4HeatZone2Data 10966;
BA_ "SPN" SG_ 2633720574 VfssModule4ReleaseZone1Data 10967;
BA_ "SPN" SG_ 2633720574 VfssModule4ReleaseZone2Data 10968;
BA_ "SPN" SG_ 2633720574 VfssModule4PressureSwitch1Data 10969;
BA_ "SPN" SG_ 2633720574 VfssModule4PressureSwitch2Data 10970;
BA_ "SPN" SG_ 2633720574 VfssModule4PrimaryPowerVoltage 10971;
BA_ "SPN" SG_ 2633720574 VfssMdl4SndrPwrVltg 10972;
BA_ "SPN" SG_ 2633720830 VfssModule1Name 10973;
BA_ "SPN" SG_ 2633720830 VfssModule1DetectorZone1Name 10974;
BA_ "SPN" SG_ 2633720830 VfssModule1DetectorZone2Name 10975;
BA_ "SPN" SG_ 2633720830 VfssModule1DetectorZone3Name 10976;
BA_ "SPN" SG_ 2633720830 VfssModule1DetectorZone4Name 10977;
BA_ "SPN" SG_ 2633720830 VfssModule1DetectorZone5Name 10978;
BA_ "SPN" SG_ 2633720830 VfssModule1DetectorZone6Name 10979;
BA_ "SPN" SG_ 2633720830 VfssModule1DetectorZone7Name 10980;
BA_ "SPN" SG_ 2633720830 VfssModule1DetectorZone8Name 10981;
BA_ "SPN" SG_ 2633720830 VfssModule1HeatZone1Name 10982;
BA_ "SPN" SG_ 2633720830 VfssModule1HeatZone2Name 10983;
BA_ "SPN" SG_ 2633720830 VfssModule1ReleaseZone1Name 10984;
BA_ "SPN" SG_ 2633720830 VfssModule1ReleaseZone2Name 10985;
BA_ "SPN" SG_ 2633721086 VfssModule2Name 10986;
BA_ "SPN" SG_ 2633721086 VfssModule2DetectorZone1Name 10987;
BA_ "SPN" SG_ 2633721086 VfssModule2DetectorZone2Name 10988;
BA_ "SPN" SG_ 2633721086 VfssModule2DetectorZone3Name 10989;
BA_ "SPN" SG_ 2633721086 VfssModule2DetectorZone4Name 10990;
BA_ "SPN" SG_ 2633721086 VfssModule2DetectorZone5Name 10991;
BA_ "SPN" SG_ 2633721086 VfssModule2DetectorZone6Name 10992;
BA_ "SPN" SG_ 2633721086 VfssModule2DetectorZone7Name 10993;
BA_ "SPN" SG_ 2633721086 VfssModule2DetectorZone8Name 10994;
BA_ "SPN" SG_ 2633721086 VfssModule2HeatZone1Name 10995;
BA_ "SPN" SG_ 2633721086 VfssModule2HeatZone2Name 10996;
BA_ "SPN" SG_ 2633721086 VfssModule2ReleaseZone1Name 10997;
BA_ "SPN" SG_ 2633721086 VfssModule2ReleaseZone2Name 10998;
BA_ "SPN" SG_ 2633721342 VfssModule3Name 10999;
BA_ "SPN" SG_ 2633721342 VfssModule3DetectorZone1Name 11000;
BA_ "SPN" SG_ 2633721342 VfssModule3DetectorZone2Name 11001;
BA_ "SPN" SG_ 2633721342 VfssModule3DetectorZone3Name 11002;
BA_ "SPN" SG_ 2633721342 VfssModule3DetectorZone4Name 11003;
BA_ "SPN" SG_ 2633721342 VfssModule3DetectorZone5Name 11004;
BA_ "SPN" SG_ 2633721342 VfssModule3DetectorZone6Name 11005;
BA_ "SPN" SG_ 2633721342 VfssModule3DetectorZone7Name 11006;
BA_ "SPN" SG_ 2633721342 VfssModule3DetectorZone8Name 11007;
BA_ "SPN" SG_ 2633721342 VfssModule3HeatZone1Name 11008;
BA_ "SPN" SG_ 2633721342 VfssModule3HeatZone2Name 11009;
BA_ "SPN" SG_ 2633721342 VfssModule3ReleaseZone1Name 11010;
BA_ "SPN" SG_ 2633721342 VfssModule3ReleaseZone2Name 11011;
BA_ "SPN" SG_ 2633721598 VfssModule4Name 11012;
BA_ "SPN" SG_ 2633721598 VfssModule4DetectorZone1Name 11013;
BA_ "SPN" SG_ 2633721598 VfssModule4DetectorZone2Name 11014;
BA_ "SPN" SG_ 2633721598 VfssModule4DetectorZone3Name 11015;
BA_ "SPN" SG_ 2633721598 VfssModule4DetectorZone4Name 11016;
BA_ "SPN" SG_ 2633721598 VfssModule4DetectorZone5Name 11017;
BA_ "SPN" SG_ 2633721598 VfssModule4DetectorZone6Name 11018;
BA_ "SPN" SG_ 2633721598 VfssModule4DetectorZone7Name 11019;
BA_ "SPN" SG_ 2633721598 VfssModule4DetectorZone8Name 11020;
BA_ "SPN" SG_ 2633721598 VfssModule4HeatZone1Name 11021;
BA_ "SPN" SG_ 2633721598 VfssModule4HeatZone2Name 11022;
BA_ "SPN" SG_ 2633721598 VfssModule4ReleaseZone1Name 11023;
BA_ "SPN" SG_ 2633721598 VfssModule4ReleaseZone2Name 11024;
BA_ "SPN" SG_ 2566612990 MtGt2IvtPwLtdDTUddRs 10817;
BA_ "SPN" SG_ 2566612990 MtGt2IvtPwLtdDTMPwMx 10822;
BA_ "SPN" SG_ 2566612990 MtGt2IvtPwLtdDTMPwM 10823;
BA_ "SPN" SG_ 2566612990 MtrGnrtr2InvrtrPwrLmtdDTTrqMxmm 10826;
BA_ "SPN" SG_ 2566612990 MtrGnrtr2InvrtrPwrLmtdDTTrqMnmm 10827;
BA_ "SPN" SG_ 2566612990 MtrGnrtr2InvrtrPwrLmtdDTSpdMxmm 10828;
BA_ "SPN" SG_ 2566612990 MtrGnrtr2InvrtrPwrLmtdDTSpdMnmm 10829;
BA_ "SPN" SG_ 2566612990 MtGt2IvtPwLtdDTIvtTpt 10830;
BA_ "SPN" SG_ 2566612990 MtGt2IvtPwLtdDTMtTpt 10831;
BA_ "SPN" SG_ 2566612990 MtGt2IvtPwLtdDTFtCdt 13045;
BA_ "SPN" SG_ 2566612990 MtGt2IvtPwLtdDTAtvTqRtLt 13046;
BA_ "SPN" SG_ 2566612990 MtGt2IvtPwLtdDTAtvSpdRtLt 13047;
BA_ "SPN" SG_ 2566612990 MtGt2IvtTqLtdDTMCtsts 13048;
BA_ "SPN" SG_ 2566612990 MtGt2IvtPwLtdDTDSdCtMx 10818;
BA_ "SPN" SG_ 2566612990 MtGt2IvtPwLtdDTDSdCtM 10819;
BA_ "SPN" SG_ 2566612990 MtGt2IvtPwLtdDTDSdVtMx 10820;
BA_ "SPN" SG_ 2566612990 MtGt2IvtPwLtdDTDSdVtM 10821;
BA_ "SPN" SG_ 2566612990 MtGt2IvtPwLtdDTDSdPwMx 10824;
BA_ "SPN" SG_ 2566612990 MtGt2IvtPwLtdDTDSdPwM 10825;
BA_ "SPN" SG_ 2566613246 MtrGnrtr2InvrtrIsltnIntgrtCntr 10811;
BA_ "SPN" SG_ 2566613246 MtGt2IvtHVtBsAtvIstTstStts 10813;
BA_ "SPN" SG_ 2566613246 MtGt2IvtHVtBsPssvIstTstStts 10814;
BA_ "SPN" SG_ 2566613246 MtGt2IvtHVtBsAtvIstTstRsts 10815;
BA_ "SPN" SG_ 2566613246 MtGt2IvtHVtBsPssvIstTstRsts 10816;
BA_ "SPN" SG_ 2566613246 MtrGnrtr2InvrtrIsltnIntgrtCr 10810;
BA_ "SPN" SG_ 2566613246 MtGt2IvtDSdNtvTCsssGdVt 10812;
BA_ "SPN" SG_ 2566613502 MtGt1IvtPwLtdDTUddRs 10779;
BA_ "SPN" SG_ 2566613502 MtGt1IvtPwLtdDTMPwMx 10784;
BA_ "SPN" SG_ 2566613502 MtGt1IvtPwLtdDTMPwM 10785;
BA_ "SPN" SG_ 2566613502 MtrGnrtr1InvrtrPwrLmtdDTTrqMxmm 10788;
BA_ "SPN" SG_ 2566613502 MtrGnrtr1InvrtrPwrLmtdDTTrqMnmm 10789;
BA_ "SPN" SG_ 2566613502 MtrGnrtr1InvrtrPwrLmtdDTSpdMxmm 10790;
BA_ "SPN" SG_ 2566613502 MtrGnrtr1InvrtrPwrLmtdDTSpdMnmm 10791;
BA_ "SPN" SG_ 2566613502 MtGt1IvtPwLtdDTIvtTpt 10792;
BA_ "SPN" SG_ 2566613502 MtGt1IvtPwLtdDTMtTpt 10793;
BA_ "SPN" SG_ 2566613502 MtGt1IvtPwLtdDTFtCdt 13041;
BA_ "SPN" SG_ 2566613502 MtGt1IvtPwLtdDTAtvTqRtLt 13042;
BA_ "SPN" SG_ 2566613502 MtGt1IvtPwLtdDTAtvSpdRtLt 13043;
BA_ "SPN" SG_ 2566613502 MtGt1IvtTqLtdDTMCtsts 13044;
BA_ "SPN" SG_ 2566613502 MtGt1IvtPwLtdDTDSdCtMx 10780;
BA_ "SPN" SG_ 2566613502 MtGt1IvtPwLtdDTDSdCtM 10781;
BA_ "SPN" SG_ 2566613502 MtGt1IvtPwLtdDTDSdVtMx 10782;
BA_ "SPN" SG_ 2566613502 MtGt1IvtPwLtdDTDSdVtM 10783;
BA_ "SPN" SG_ 2566613502 MtGt1IvtPwLtdDTDSdPwMx 10786;
BA_ "SPN" SG_ 2566613502 MtGt1IvtPwLtdDTDSdPwM 10787;
BA_ "SPN" SG_ 2566613758 MtrGnrtr1InvrtrIsltnIntgrtCntr 10773;
BA_ "SPN" SG_ 2566613758 MtGt1IvtHVtBsAtvIstTstStts 10775;
BA_ "SPN" SG_ 2566613758 MtGt1IvtHVtBsPssvIstTstStts 10776;
BA_ "SPN" SG_ 2566613758 MtGt1IvtHVtBsAtvIstTstRsts 10777;
BA_ "SPN" SG_ 2566613758 MtGt1IvtHVtBsPssvIstTstRsts 10778;
BA_ "SPN" SG_ 2566613758 MtrGnrtr1InvrtrIsltnIntgrtCr 10772;
BA_ "SPN" SG_ 2566613758 MtGt1IvtDSdNtvTCsssGdVt 10774;
BA_ "SPN" SG_ 2566614014 HighVoltageDcBusAvailability 10298;
BA_ "SPN" SG_ 2566614014 HghVltgBsDrvlnAvllt 20802;
BA_ "SPN" SG_ 2566614014 HghVltgBsAxlrsAvllt 20803;
BA_ "SPN" SG_ 2566614014 HighVoltageBusEptoAvailability 20804;
BA_ "SPN" SG_ 2566614014 HghVltgBsOnBrdChrgrAvllt 20805;
BA_ "SPN" SG_ 2566614014 HghVltgBsOffBrdChrgrAvllt 20806;
BA_ "SPN" SG_ 2352021246 Hvesp7PowerDownCommand 14038;
BA_ "SPN" SG_ 2352021246 Hvesp7CellBalancingCommand 14041;
BA_ "SPN" SG_ 2352021246 Hvesp7OperationConsent 14043;
BA_ "SPN" SG_ 2352021246 Hvesp7Control1Counter 14046;
BA_ "SPN" SG_ 2352021246 Hvesp7Control1Crc 14047;
BA_ "SPN" SG_ 2352021246 Hvsp7HghVltgBsCnntCmmnd 14037;
BA_ "SPN" SG_ 2352021246 Hvsp7HghVltgBsAtvIsltnTstCmmnd 14039;
BA_ "SPN" SG_ 2352021246 Hvsp7HghVltgBsPssvIsltnTstCmmnd 14040;
BA_ "SPN" SG_ 2352021246 Hvsp7EnlIntrnlChrgrCmmnd 14042;
BA_ "SPN" SG_ 2352021246 Hvsp7HVtBsHSdRsstCtRqst 14044;
BA_ "SPN" SG_ 2352021246 Hvsp7HghVltgBsLwSdRsstrCnntRqst 14045;
BA_ "SPN" SG_ 2352021246 Hvsp7ThrmlMngmntMntnnRqst 20885;
BA_ "SPN" SG_ 2352086782 Hvesp8PowerDownCommand 14181;
BA_ "SPN" SG_ 2352086782 Hvesp8CellBalancingCommand 14184;
BA_ "SPN" SG_ 2352086782 Hvesp8OperationConsent 14186;
BA_ "SPN" SG_ 2352086782 Hvesp8Control1Counter 14189;
BA_ "SPN" SG_ 2352086782 Hvesp8Control1Crc 14190;
BA_ "SPN" SG_ 2352086782 Hvsp8HghVltgBsCnntCmmnd 14180;
BA_ "SPN" SG_ 2352086782 Hvsp8HghVltgBsAtvIsltnTstCmmnd 14182;
BA_ "SPN" SG_ 2352086782 Hvsp8HghVltgBsPssvIsltnTstCmmnd 14183;
BA_ "SPN" SG_ 2352086782 Hvsp8EnlIntrnlChrgrCmmnd 14185;
BA_ "SPN" SG_ 2352086782 Hvsp8HVtBsHSdRsstCtRqst 14187;
BA_ "SPN" SG_ 2352086782 Hvsp8HghVltgBsLwSdRsstrCnntRqst 14188;
BA_ "SPN" SG_ 2352086782 Hvsp8ThrmlMngmntMntnnRqst 20886;
BA_ "SPN" SG_ 2352152318 Hvesp9PowerDownCommand 14324;
BA_ "SPN" SG_ 2352152318 Hvesp9CellBalancingCommand 14327;
BA_ "SPN" SG_ 2352152318 Hvesp9OperationConsent 14329;
BA_ "SPN" SG_ 2352152318 Hvesp9Control1Counter 14332;
BA_ "SPN" SG_ 2352152318 Hvesp9Control1Crc 14333;
BA_ "SPN" SG_ 2352152318 Hvsp9HghVltgBsCnntCmmnd 14323;
BA_ "SPN" SG_ 2352152318 Hvsp9HghVltgBsAtvIsltnTstCmmnd 14325;
BA_ "SPN" SG_ 2352152318 Hvsp9HghVltgBsPssvIsltnTstCmmnd 14326;
BA_ "SPN" SG_ 2352152318 Hvsp9EnlIntrnlChrgrCmmnd 14328;
BA_ "SPN" SG_ 2352152318 Hvsp9HVtBsHSdRsstCtRqst 14330;
BA_ "SPN" SG_ 2352152318 Hvsp9HghVltgBsLwSdRsstrCnntRqst 14331;
BA_ "SPN" SG_ 2352152318 Hvsp9ThrmlMngmntMntnnRqst 20887;
BA_ "SPN" SG_ 2352217854 Hvesp10PowerDownCommand 14467;
BA_ "SPN" SG_ 2352217854 Hvesp10CellBalancingCommand 14470;
BA_ "SPN" SG_ 2352217854 Hvesp10OperationConsent 14472;
BA_ "SPN" SG_ 2352217854 Hvesp10Control1Counter 14475;
BA_ "SPN" SG_ 2352217854 Hvesp10Control1Crc 14476;
BA_ "SPN" SG_ 2352217854 Hvsp10HghVltgBsCnntCmmnd 14466;
BA_ "SPN" SG_ 2352217854 Hvsp10HghVltgBsAtvIsltnTstCmmnd 14468;
BA_ "SPN" SG_ 2352217854 Hvsp10HVtBsPssvIstTstCd 14469;
BA_ "SPN" SG_ 2352217854 Hvsp10EnlIntrnlChrgrCmmnd 14471;
BA_ "SPN" SG_ 2352217854 Hvsp10HVtBsHSdRsstCtRqst 14473;
BA_ "SPN" SG_ 2352217854 Hvsp10HVtBsLwSdRsstCtRqst 14474;
BA_ "SPN" SG_ 2352217854 Hvsp10ThrmlMngmntMntnnRqst 20888;
BA_ "SPN" SG_ 2555379454 DataTransferManufacturerId 12993;
BA_ "SPN" SG_ 2555379454 TotalWeeklyMessageInstances 12997;
BA_ "SPN" SG_ 2555379454 LongestWeeklyMessageInstance 12998;
BA_ "SPN" SG_ 2555379454 TotalMonthlyMessageInstances 13000;
BA_ "SPN" SG_ 2555379454 LongestMonthlyMessageInstance 13001;
BA_ "SPN" SG_ 2555379454 TotalDailyMessageInstances 12994;
BA_ "SPN" SG_ 2555379454 LongestDailyMessageInstance 12995;
BA_ "SPN" SG_ 2555379454 TotalDailyMessageBytes 12996;
BA_ "SPN" SG_ 2555379454 TotalWeeklyMessageBytes 12999;
BA_ "SPN" SG_ 2555379454 TotalMonthlyMessageBytes 13002;
BA_ "SPN" SG_ 2555444990 MonthlyMessageInstance 12983;
BA_ "SPN" SG_ 2555444990 MnthlMssgInstnsRmnng 12984;
BA_ "SPN" SG_ 2555444990 MonthlyDataManufacturerId 12985;
BA_ "SPN" SG_ 2555510526 WeeklyMessageInstance 12978;
BA_ "SPN" SG_ 2555510526 WeeklyMessageInstancesRemaining 12979;
BA_ "SPN" SG_ 2555510526 WeeklyDataManufacturerId 12980;
BA_ "SPN" SG_ 2555576062 DailyMessageInstance 12973;
BA_ "SPN" SG_ 2555576062 DailyMessageInstancesRemaining 12974;
BA_ "SPN" SG_ 2555576062 DailyDataManufacturerId 12975;
BA_ "SPN" SG_ 2364675326 Hvsp7DshrgPwrLmtDTSttOfChrg 14048;
BA_ "SPN" SG_ 2364675326 Hvsp7DshrgPwrLmtDTBttrTmprtr 14049;
BA_ "SPN" SG_ 2364675326 Hvsp7DsPwLtDTBttDstCdt 14050;
BA_ "SPN" SG_ 2364675326 Hvsp7DshrgPwrLmtDTBttrOrCllVltg 14051;
BA_ "SPN" SG_ 2364675326 Hvsp7DshrgPwrLmtDTBttrCrrnt 14052;
BA_ "SPN" SG_ 2364675326 Hvsp7DshrgPwrLmtDTAnUndfndCs 14053;
BA_ "SPN" SG_ 2364675326 Hvsp7ChrgPwrLmtDTSttOfChrg 14054;
BA_ "SPN" SG_ 2364675326 Hvsp7ChrgPwrLmtDTBttrTmprtr 14055;
BA_ "SPN" SG_ 2364675326 Hvsp7ChrgPwrLmtDTBttrDgnstCndtn 14056;
BA_ "SPN" SG_ 2364675326 Hvsp7ChrgPwrLmtDTBttrOrCllVltg 14057;
BA_ "SPN" SG_ 2364675326 Hvsp7ChrgPwrLmtDTBttrCrrnt 14058;
BA_ "SPN" SG_ 2364675326 Hvsp7ChrgPwrLmtDTAnUndfndCs 14059;
BA_ "SPN" SG_ 2364675582 Hvesp7AvailableDischargePower 14060;
BA_ "SPN" SG_ 2364675582 Hvesp7AvailableChargePower 14061;
BA_ "SPN" SG_ 2364675582 Hvesp7VoltageLevel 14062;
BA_ "SPN" SG_ 2364675582 Hvesp7Current 14063;
BA_ "SPN" SG_ 2364675838 Hvesp7FastUpdateStateOfCharge 14064;
BA_ "SPN" SG_ 2364675838 Hvesp7HighestCellVoltage 14065;
BA_ "SPN" SG_ 2364675838 Hvesp7LowestCellVoltage 14066;
BA_ "SPN" SG_ 2364675838 Hvsp7CllVltgDffrntlStts 14067;
BA_ "SPN" SG_ 2364676094 Hvesp7HighestCellTemperature 14068;
BA_ "SPN" SG_ 2364676094 Hvesp7LowestCellTemperature 14069;
BA_ "SPN" SG_ 2364676094 Hvesp7AverageCellTemperature 14070;
BA_ "SPN" SG_ 2364676094 Hvsp7CllTmprtrDffrntlStts 14071;
BA_ "SPN" SG_ 2364676350 Hvesp7DischargeCapacity 14072;
BA_ "SPN" SG_ 2364676350 Hvesp7ChargeCapacity 14073;
BA_ "SPN" SG_ 2364676350 Hvesp7CellBalancingCount 14074;
BA_ "SPN" SG_ 2364676606 Hvesp7LowestCellStateOfCharge 14077;
BA_ "SPN" SG_ 2364676606 Hvesp7HighestCellStateOfCharge 14078;
BA_ "SPN" SG_ 2364676606 Hvsp7MxmmInstntnsDshrgCrrntLmt 14075;
BA_ "SPN" SG_ 2364676606 Hvsp7MxmmInstntnsChrgCrrntLmt 14076;
BA_ "SPN" SG_ 2364676862 Hvesp7BusVoltage 14079;
BA_ "SPN" SG_ 2364676862 Hvesp7IgnitionVoltage 14080;
BA_ "SPN" SG_ 2364676862 Hvesp7IntakeCoolantTemperature 14081;
BA_ "SPN" SG_ 2364676862 Hvesp7OutletCoolantTemperature 14082;
BA_ "SPN" SG_ 2364676862 Hvesp7ElectronicsTemperature 14083;
BA_ "SPN" SG_ 2364676862 Hvesp7Temperature 14084;
BA_ "SPN" SG_ 2364677118 Hvesp7HvilStatus 14092;
BA_ "SPN" SG_ 2364677118 Hvesp7InertiaSwitchStatus 14093;
BA_ "SPN" SG_ 2364677118 Hvesp7StateOfChargeStatus 14094;
BA_ "SPN" SG_ 2364677118 Hvesp7CellBalanceStatus 14095;
BA_ "SPN" SG_ 2364677118 Hvesp7CellBalancingActive 14096;
BA_ "SPN" SG_ 2364677118 Hvesp7InternalChargerStatus 14097;
BA_ "SPN" SG_ 2364677118 Hvesp7OperationalStatus 14099;
BA_ "SPN" SG_ 2364677118 Hvesp7Status1Counter 14100;
BA_ "SPN" SG_ 2364677118 Hvesp7Status1Crc 14101;
BA_ "SPN" SG_ 2364677118 Hvsp7HghVltgBsPstvCnttrStt 14085;
BA_ "SPN" SG_ 2364677118 Hvsp7HghVltgBsNgtvCnttrStt 14086;
BA_ "SPN" SG_ 2364677118 Hvsp7HghVltgBsDsnntFrwrnng 14087;
BA_ "SPN" SG_ 2364677118 Hvsp7HghVltgBsPrChrgRlStt 14088;
BA_ "SPN" SG_ 2364677118 Hvsp7CntrOfPkCnttrStt 14089;
BA_ "SPN" SG_ 2364677118 Hvsp7HghVltgBsAtvIsltnTstStts 14090;
BA_ "SPN" SG_ 2364677118 Hvsp7HghVltgBsPssvIsltnTstStts 14091;
BA_ "SPN" SG_ 2364677118 Hvsp7HghVltgBsCnntnStts 14098;
BA_ "SPN" SG_ 2364677374 Hvesp7DischargeEnergyCapacity 14102;
BA_ "SPN" SG_ 2364677374 Hvesp7ChargeEnergyCapacity 14103;
BA_ "SPN" SG_ 2364677374 Hvesp7MaximumChargeVoltageLimit 14104;
